VERSION ""

NS_ :

BS_:

BU_: Tester GW ECM ESP DCT EPS Ibooster HCU EDC IBooster

BO_ 87 PEPS10: 8 GW
 SG_ PEPS_VehAuth2 : 7|64@0+ (1,0) [0|1.84467440737096E+019] ""  HCU

BO_ 96 HCU_FD1: 64 HCU
 SG_ Checksum_HCU_PT1 : 71|8@0+ (1,0) [0|255] ""  GW,DCT,ESP,ECM,Ibooster
 SG_ HCU_AccelPedalPosn_Diag : 79|8@0+ (0.3937,0) [0|100.395] "%"  GW,DCT,ESP,ECM
 SG_ HCU_BrkPedalSts : 87|2@0+ (1,0) [0|3] ""  GW,DCT,ECM
 SG_ HCU_AccelPedalPosn_DiagValid : 85|1@0+ (1,0) [0|1] ""  GW,DCT,ESP,ECM
 SG_ HCU_BrkPedalStsValid : 84|1@0+ (1,0) [0|1] ""  GW,ECM
 SG_ ActWheelTrqDmd : 83|12@0+ (5,-6000) [-6000|14475] "Nm"  GW
 SG_ HCU_AccelPedalPosn : 103|8@0+ (0.3937,0) [0|100.395] "%"  GW,DCT,ESP
 SG_ HCU_AccelPedalPosnValid : 127|1@0+ (1,0) [0|1] ""  GW,DCT,ESP
 SG_ P4M_ActRotSpd : 111|16@0+ (1,-16382) [-16382|16383] "rpm"  DCT,ESP,ECM,Ibooster,EPS
 SG_ RollingCounter_HCU_PT1 : 123|4@0+ (1,0) [0|15] ""  GW,DCT,ESP,ECM,Ibooster
 SG_ Checksum_HCU_PT9 : 135|8@0+ (1,0) [0|255] ""  GW,ESP
 SG_ MaxPsblWheelTrq : 143|10@0+ (20,-6000) [-6000|14460] "Nm"  GW,ESP,ECM
 SG_ TotWheelTrq : 147|12@0+ (5,-6000) [-6000|14475] "Nm"  GW,ESP,ECM
 SG_ MinPsblWheelTrq : 167|10@0+ (20,-6000) [-6000|14460] "Nm"  GW,ESP,ECM
 SG_ HCU_ACCInterface : 170|1@0+ (1,0) [0|1] ""  GW
 SG_ RollingCounter_HCU_PT9 : 187|4@0+ (1,0) [0|15] ""  GW,ESP
 SG_ Checksum_HCU_HP1 : 199|8@0+ (1,0) [0|255] ""  DCT,ESP
 SG_ HCU_NetTrq_TrsmClutch : 207|12@0+ (0.05,-100) [-100|100] "%"  DCT,ESP
 SG_ HCU_TrqReq_TrsmClutch : 211|12@0+ (0.05,-100) [-100|100] "%"  DCT
 SG_ HCU_TrqReqWoDCT_TrsmClutch : 231|12@0+ (0.05,-100) [-100|100] "%"  DCT
 SG_ HCU_MaxTrqLimt_TrsmClutch : 235|10@0+ (0.2,-100) [-100|100] "%"  DCT
 SG_ HCU_TrsmClutchAdaptAck : 241|1@0+ (1,0) [0|1] ""  DCT
 SG_ HCU_K0ClutchAdaptAck : 240|1@0+ (1,0) [0|1] ""  DCT
 SG_ HCU_NetTrq_TrsmClutchValid : 255|1@0+ (1,0) [0|1] ""  DCT,ESP
 SG_ HCU_MaxEngTrqLimtValid : 254|1@0+ (1,0) [0|1] ""  DCT
 SG_ HCU_TrqReqWoDCT_TrsmClutchValid : 253|1@0+ (1,0) [0|1] ""  DCT
 SG_ HCU_TgtEngTrqValid : 252|1@0+ (1,0) [0|1] ""  DCT
 SG_ RollingCounter_HCU_HP1 : 251|4@0+ (1,0) [0|15] ""  DCT,ESP
 SG_ CheckSum_HCU_HP10 : 263|8@0+ (1,0) [0|255] ""  ESP,Ibooster
 SG_ RegenWheelTrqAct : 269|14@0+ (1,-16383) [-16383|0] ""  ESP
 SG_ AvailRgnTrq : 285|14@0+ (1,-16383) [-16383|0] "Nm"  ESP
 SG_ TargetGear_RA : 319|2@0+ (1,0) [0|3] ""  ESP
 SG_ RegenWheelTrqActValid : 317|1@0+ (1,0) [0|1] ""  ESP
 SG_ AvailRgnTrqValid : 316|1@0+ (1,0) [0|1] ""  ESP
 SG_ TrqReq_FAValid : 298|1@0+ (1,0) [0|1] ""  ESP
 SG_ TrqReq_FA : 297|10@0+ (1,-224) [-224|799] "Nm"  ESP
 SG_ HCU_PowertrainSts : 303|5@0+ (1,0) [0|31] ""  GW,DCT,ESP,ECM,Ibooster
 SG_ RollingCounter_HCU_HP10 : 315|4@0+ (1,0) [0|15] ""  ESP,Ibooster
 SG_ Checksum_HCU_HP11 : 327|8@0+ (1,0) [0|255] ""  DCT,ESP
 SG_ HCU_P4M_ActTrq : 335|14@0+ (0.1,-819) [-819|819.1] "Nm"  ESP
 SG_ HCU_AccPedalPosnCorrd : 351|8@0+ (0.3937,0) [0|100.395] "%" Vector__XXX
 SG_ ACU_ShiftInProgress : 375|2@0+ (1,0) [0|3] ""  GW,ESP
 SG_ ACU_ActGear : 373|3@0+ (1,0) [0|7] ""  ESP
 SG_ HCU_AccPedalPosnCorrdValid : 368|1@0+ (1,0) [0|1] "" Vector__XXX
 SG_ HCU_RaceLaunchSts : 367|3@0+ (1,0) [0|7] ""  GW,DCT,ECM
 SG_ HCU_RaceLaunchAvail : 364|2@0+ (1,0) [0|3] ""  GW
 SG_ HCU_HWPInterface : 337|1@0+ (1,0) [0|1] ""  GW
 SG_ HCU_RespHWP : 336|1@0+ (1,0) [0|1] ""  GW,ESP,Ibooster
 SG_ Rollingcounter_HCU_HP11 : 379|4@0+ (1,0) [0|15] ""  DCT,ESP
 SG_ BMS_BattChrgPower_10s : 423|10@0+ (0.2,0) [0|132] "KW"  DCT
 SG_ BMS_BattDchrgPower_10s : 429|10@0+ (0.2,0) [0|150] "KW"  DCT

BO_ 124 DCT_FD1: 64 DCT
 SG_ CheckSum_DCT1 : 71|8@0+ (1,0) [0|255] ""  ECM
 SG_ TqIdleReq : 125|1@0+ (1,0) [0|1] ""  HCU,ECM
 SG_ TqLossAct : 79|16@0+ (0.0030518,-100) [-100|99.9966612] "%"  HCU,ECM
 SG_ EngCrkEna : 127|1@0+ (1,0) [0|1] ""  GW
 SG_ TrsmAdaptActv : 124|1@0+ (1,0) [0|1] ""  HCU,ECM
 SG_ TrqRedFastReq : 95|16@0+ (0.0030518,-100) [-100|99.9966612] "%"  HCU
 SG_ EngTqMaxLim : 111|16@0+ (0.0030518,-100) [-100|99.9966612] "%"  HCU
 SG_ TCUResponseHWP : 126|1@0+ (1,0) [0|1] ""  GW
 SG_ RollingCounter_DCT1 : 123|4@0+ (1,0) [0|15] ""  ECM
 SG_ CheckSum_DCT2 : 135|8@0+ (1,0) [0|255] ""  ECM
 SG_ TC_SLIP_STATE : 191|3@0+ (1,0) [0|7] ""  HCU,ECM
 SG_ EngIdleSpdReq : 175|8@0+ (10,0) [0|2550] "RPM"  HCU,ECM
 SG_ EngTqGradientLim : 183|8@0+ (10,0) [0|2540] "Nm/s"  HCU
 SG_ TrqRedSlowReq : 159|16@0+ (0.0030518,-100) [-100|99.9966612] "%"  HCU
 SG_ RollingCounter_DCT2 : 187|4@0+ (1,0) [0|15] ""  ECM
 SG_ CheckSum_DCT3 : 199|8@0+ (1,0) [0|255] ""  ESP
 SG_ TgtEngSpdIP : 239|12@0+ (2,0) [0|8190] "RPM"  GW
 SG_ TgtEngSpdIPValid : 242|1@0+ (1,0) [0|1] ""  GW
 SG_ DCT_RaceLaunchAvail : 253|2@0+ (1,0) [0|3] ""  HCU
 SG_ DCT_RaceLaunchProhibit : 200|1@0+ (1,0) [0|1] ""  HCU
 SG_ DCT_EPBActvReqValid : 241|1@0+ (1,0) [0|1] ""  ESP
 SG_ DCT_EPBActvReq : 240|1@0+ (1,0) [0|1] ""  ESP
 SG_ TrsmTqIdle : 223|16@0+ (0.0030518,-100) [-100|99.9966612] "%"  HCU,ECM
 SG_ Start_Stop_Mode_DCT : 204|3@0+ (1,0) [0|7] ""  HCU
 SG_ StopStartFail_B_DCT : 207|1@0+ (1,0) [0|1] ""  HCU
 SG_ Start_Stop_Req_DCT : 206|2@0+ (1,0) [0|3] ""  HCU
 SG_ RatAct : 215|8@0+ (0.1,0) [0|25.5] ""  GW,HCU
 SG_ RollingCounter_DCT3 : 251|4@0+ (1,0) [0|15] ""  ESP
 SG_ CheckSumDCT11 : 327|8@0+ (1,0) [0|255] "" Vector__XXX
 SG_ DCT_K1ClutchOilPressure : 335|16@0+ (0.473,0) [0|31000] "mBar"  HCU
 SG_ DCT_K0ClutchPredictTorque : 351|12@0+ (0.05,-100) [-100|100] "%"  HCU
 SG_ DCT_K1ClutchPredictTorque : 355|12@0+ (0.05,-100) [-100|100] "%"  HCU
 SG_ DCT_K2ClutchPredictTorque : 375|12@0+ (0.05,-100) [-100|100] "%"  HCU
 SG_ RollingCounterDCT11 : 379|4@0+ (1,0) [0|15] "" Vector__XXX
 SG_ FreshnessValue_DCT_FD1 : 455|16@0+ (1,0) [0|65535] ""  GW
 SG_ MAC_Check_DCT_FD1 : 471|48@0+ (1,0) [0|281474976710655] ""  GW
 SG_ CheckSumDCT19 : 391|8@0+ (1,0) [0|255] ""  HCU
 SG_ TCU_TgtTrsmRatio : 423|8@0+ (0.1,0) [0|25.5] ""  HCU
 SG_ DCT_TrqRatio : 431|16@0+ (0.001,0) [0|65.533] ""  HCU
 SG_ RollingCounterDCT19 : 443|4@0+ (1,0) [0|15] ""  HCU

BO_ 135 PEPS3: 8 GW
 SG_ PEPS_VehAuth1 : 7|64@0+ (1,0) [0|1.84467440737095E+019] ""  HCU

BO_ 143 ECM_FD5: 64 ECM
 SG_ Checksum_ECM1 : 7|8@0+ (1,0) [0|255] ""  GW,HCU,DCT,ESP,Ibooster
 SG_ EngSpd_PHEV : 47|16@0+ (0.125,0) [0|8191.875] "rpm"  GW,HCU,DCT,ESP,Ibooster,EDC,EPS
 SG_ EngSpdVldty_PHEV : 63|2@0+ (1,0) [0|2] ""  GW,HCU,DCT,ESP,Ibooster,EDC,EPS
 SG_ RollingCounter_ECM1 : 59|4@0+ (1,0) [0|15] ""  GW,HCU,DCT,ESP,Ibooster
 SG_ Checksum_ECM_HP2 : 71|8@0+ (1,0) [0|255] ""  HCU,ESP
 SG_ TrqMaxSlowPath : 79|10@0+ (1,-224) [-224|799] "Nm"  HCU
 SG_ TrqMinSlowPath : 85|10@0+ (1,-224) [-224|799] "Nm"  HCU
 SG_ TrqMaxFastPath : 91|10@0+ (1,-224) [-224|799] "Nm"  HCU,ESP
 SG_ TrqMinFastPath : 97|10@0+ (1,-224) [-224|799] "Nm"  HCU
 SG_ TgtCrsAcc : 119|8@0+ (0.015,-1.5) [-1.5|2.325] "m/s2"  HCU
 SG_ TrqRngValid : 127|1@0+ (1,0) [0|1] ""  HCU
 SG_ TgtCrsAccValid : 126|1@0+ (1,0) [0|1] ""  HCU
 SG_ RollingCounter_ECM_HP2 : 123|4@0+ (1,0) [0|15] ""  HCU,ESP
 SG_ Checksum_ECM_HP4 : 135|8@0+ (1,0) [0|255] ""  HCU
 SG_ IdleTrq_PI : 143|10@0+ (0.5,-256) [-256|255.5] "NM"  HCU
 SG_ IdleTrq_PIValid : 149|1@0+ (1,0) [0|1] ""  HCU
 SG_ MaxAlwdTrqIntvntn : 148|10@0+ (1,-224) [-224|799] "Nm"  HCU
 SG_ IdleTrq_ECUInternal : 154|11@0+ (0.25,0) [0|511.75] "Nm"  HCU
 SG_ MinAlwdTrqIntvntn : 175|10@0+ (1,-224) [-224|799] "Nm"  HCU
 SG_ SpdGovFactor : 181|8@0+ (0.00393,0) [0|1] ""  HCU
 SG_ RngAlwdTrqIntvntnValid : 189|1@0+ (1,0) [0|1] ""  HCU
 SG_ CANSendSts_Wakeup : 188|1@0+ (1,0) [0|1] ""  HCU
 SG_ RollingCounter_ECM_HP4 : 187|4@0+ (1,0) [0|15] ""  HCU
 SG_ Checksum_ECM_HP3 : 199|8@0+ (1,0) [0|255] ""  HCU
 SG_ EngStatnryTrqSlowPathMax : 207|10@0+ (1,-224) [-224|799] "Nm"  HCU
 SG_ EngStatnryTrqSlowPathMin : 213|10@0+ (1,-224) [-224|799] "Nm"  HCU
 SG_ EngStatnryTrqFastPathMax : 219|10@0+ (1,-224) [-224|799] "Nm"  HCU
 SG_ EngStatnryTrqFastPathMin : 225|10@0+ (1,-224) [-224|799] "Nm"  HCU
 SG_ EngStatnryTrqRngValid : 255|1@0+ (1,0) [0|1] ""  HCU
 SG_ RollingCounter_ECM_HP3 : 251|4@0+ (1,0) [0|15] ""  HCU
 SG_ Checksum_ECM_PT5 : 263|8@0+ (1,0) [0|255] ""  HCU,DCT,ESP
 SG_ EngTrqLimProtFastPath : 271|10@0+ (1,-224) [-224|799] "Nm"  HCU
 SG_ EngTrqLimProtSlowPath : 277|10@0+ (1,-224) [-224|799] "Nm"  HCU
 SG_ EngTrqCrankshaftLvl : 283|12@0+ (0.25,-224) [-224|799.75] "Nm"  GW,HCU,DCT,ESP
 SG_ EngTrqCrankshaftLvlValid : 317|1@0+ (1,0) [0|1] ""  GW,HCU,DCT
 SG_ EngTrqLimProtValid : 316|1@0+ (1,0) [0|1] ""  HCU
 SG_ RollingCounter_ECM_PT5 : 315|4@0+ (1,0) [0|15] ""  HCU,DCT,ESP
 SG_ Checksum_ECM_HP1 : 327|8@0+ (1,0) [0|255] ""  HCU
 SG_ TrqMinFastPathFCO : 351|10@0+ (1,-224) [-224|799] "Nm"  HCU
 SG_ EngTrqLoss : 357|12@0+ (0.25,-224) [-224|799.75] "Nm"  HCU
 SG_ EngErrCategory0 : 361|1@0+ (1,0) [0|1] ""  HCU
 SG_ EngErrCategory1 : 360|1@0+ (1,0) [0|1] ""  HCU
 SG_ EngErrCategory2 : 375|1@0+ (1,0) [0|1] ""  HCU
 SG_ EngErrCategory3 : 374|1@0+ (1,0) [0|1] ""  HCU
 SG_ EngErrCategory4 : 373|1@0+ (1,0) [0|1] ""  HCU
 SG_ EngStopEnable : 372|1@0+ (1,0) [0|1] ""  HCU
 SG_ EngStartReq : 371|1@0+ (1,0) [0|1] ""  HCU
 SG_ ECM_TrqStructActv : 370|1@0+ (1,0) [0|1] ""  HCU
 SG_ FCOActv : 369|1@0+ (1,0) [0|1] ""  HCU,DCT
 SG_ FCOEnable : 368|1@0+ (1,0) [0|1] ""  HCU
 SG_ EngTrqLossValid : 383|1@0+ (1,0) [0|1] ""  HCU
 SG_ TrqMinFastPathFCOValid : 382|1@0+ (1,0) [0|1] ""  HCU
 SG_ RollingCounter_ECM_HP1 : 379|4@0+ (1,0) [0|15] ""  HCU

BO_ 150 IBooster_FD3: 32 IBooster
 SG_ CheckSum_IBooster_FD3_1 : 7|8@0+ (1,0) [0|255] ""  ESP
 SG_ DrvReqTarFxBrakeAvl : 15|2@0+ (1,0) [0|2] ""  ESP
 SG_ DrvReqTarFxBrake : 13|14@0+ (8,-125000) [-125000|0] ""  ESP
 SG_ DrvPressBrkPedalAvl : 31|2@0+ (1,0) [0|2] ""  ESP
 SG_ IsDrvPressBrkPedal : 29|1@0+ (1,0) [0|1] ""  ESP
 SG_ DrvReqFxBrkDomAvail : 28|2@0+ (1,0) [0|2] ""  ESP
 SG_ IsDrvReqFxBrakeDom : 26|1@0+ (1,0) [0|1] ""  ESP
 SG_ DrvReqParkBrakeAvail : 25|2@0+ (1,0) [0|2] ""  ESP
 SG_ DriverReqParkBrake : 39|2@0+ (1,0) [0|2] ""  ESP
 SG_ IsDrvReqParkBrkDom : 37|1@0+ (1,0) [0|1] ""  ESP
 SG_ BrkDiscTempStatus : 36|2@0+ (1,0) [0|3] ""  ESP
 SG_ BrkDiscTempStatusAvl : 47|2@0+ (1,0) [0|2] ""  ESP
 SG_ BrakeBckpStratState : 45|2@0+ (1,0) [0|2] ""  ESP
 SG_ BrkBckStratFxCtrlAvl : 34|3@0+ (1,0) [0|4] ""  ESP
 SG_ BrkBckStgyVehStopAvl : 43|3@0+ (1,0) [0|4] ""  ESP
 SG_ CurrentPumpRev : 40|9@0+ (20,0) [0|10000] ""  ESP
 SG_ RollingCounter_IBooster_FD3_1 : 59|4@0+ (1,0) [0|15] ""  ESP
 SG_ CheckSum_IBooster_FD3_2 : 71|8@0+ (1,0) [0|255] ""  ESP
 SG_ CompatibilityIndexAD : 79|4@0+ (1,0) [0|15] ""  ESP
 SG_ FxDrvBrake : 87|16@0+ (10,-250000) [-250000|250000] ""  ESP
 SG_ ParkBrakeRequest : 103|3@0+ (1,0) [0|4] ""  ESP
 SG_ DriveBckp2MnState : 75|4@0+ (1,0) [0|11] ""  ESP
 SG_ StopBckp2MnState : 100|4@0+ (1,0) [0|11] ""  ESP
 SG_ LsmBckpLvl23Avail : 111|2@0+ (1,0) [0|3] ""  ESP
 SG_ LsmBckpLvl23Cpbl : 109|2@0+ (1,0) [0|2] ""  ESP
 SG_ DrvBckpLvl3Avail : 107|2@0+ (1,0) [0|3] ""  ESP
 SG_ DrvBckpLvl3Cpbl : 105|2@0+ (1,0) [0|2] ""  ESP
 SG_ RollingCounter_IBooster_FD3_2 : 123|4@0+ (1,0) [0|15] ""  ESP
 SG_ CheckSum_IBooster_FD3_3 : 135|8@0+ (1,0) [0|255] ""  ESP
 SG_ UsedChannel : 143|2@0+ (1,0) [0|3] ""  ESP
 SG_ BrakeFxCapability : 141|2@0+ (1,0) [0|2] ""  ESP
 SG_ BrakeFxAvailability : 139|2@0+ (1,0) [0|2] ""  ESP
 SG_ BrakeFxActual : 151|14@0+ (8,-125000) [-125000|0] ""  ESP
 SG_ IsBrkFctReqFxBrkDom : 153|1@0+ (1,0) [0|1] ""  ESP
 SG_ DecStabAvail : 137|2@0+ (1,0) [0|2] ""  ESP
 SG_ DecStabCpblty : 167|2@0+ (1,0) [0|3] ""  ESP
 SG_ DecStabAvlForDriver : 165|2@0+ (1,0) [0|2] ""  ESP
 SG_ DecStabCpbltyForDrvr : 163|2@0+ (1,0) [0|3] ""  ESP
 SG_ DecStabActivity : 161|2@0+ (1,0) [0|2] ""  ESP
 SG_ AccStabAvail : 175|2@0+ (1,0) [0|2] ""  ESP
 SG_ AccStabActivity : 152|1@0+ (1,0) [0|1] ""  ESP
 SG_ YawRateStabAvl : 173|2@0+ (1,0) [0|2] ""  ESP
 SG_ YawRateStabActivity : 171|1@0+ (1,0) [0|1] ""  ESP
 SG_ ParkBrakeCapability : 183|2@0+ (1,0) [0|2] ""  ESP
 SG_ ParkBrakeAvl : 181|2@0+ (1,0) [0|2] ""  ESP
 SG_ ParkBrakeState : 170|3@0+ (1,0) [0|4] ""  ESP
 SG_ ParkBrakeSupportReq : 179|1@0+ (1,0) [0|1] ""  ESP
 SG_ IsBrkFctReqPrkBrkDom : 178|1@0+ (1,0) [0|1] ""  ESP
 SG_ RollingCounter_IBooster_FD3_3 : 187|4@0+ (1,0) [0|15] ""  ESP

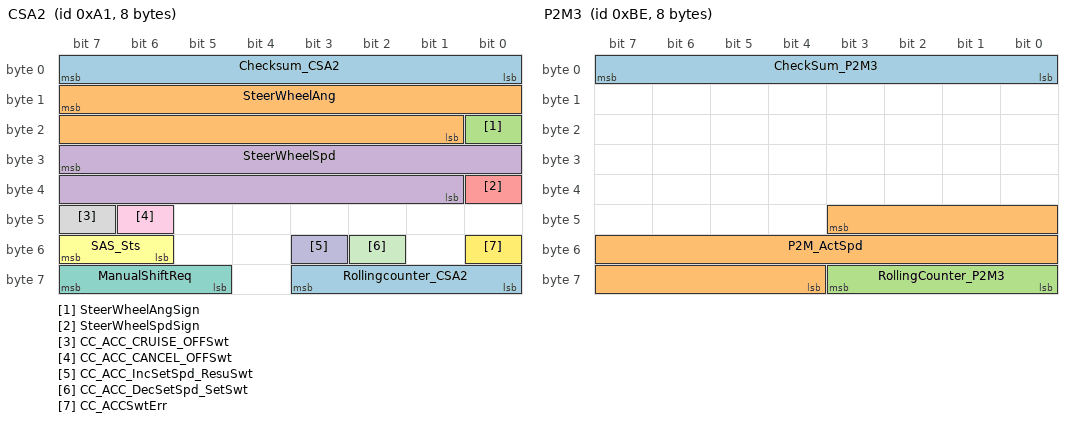
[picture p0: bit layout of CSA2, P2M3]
BO_ 161 CSA2: 8 GW
 SG_ Checksum_CSA2 : 7|8@0+ (1,0) [0|255] ""  ESP,ECM,Ibooster,EPS
 SG_ SteerWheelAng : 15|15@0+ (0.1,0) [0|780] "deg"  HCU,DCT,ESP,Ibooster,EDC,EPS
 SG_ SteerWheelAngSign : 16|1@0+ (1,0) [0|1] ""  HCU,ESP,Ibooster,EDC,EPS
 SG_ SteerWheelSpd : 31|15@0+ (0.1,0) [0|1016] "deg/s"  HCU,ESP,ECM,Ibooster,EDC
 SG_ SteerWheelSpdSign : 32|1@0+ (1,0) [0|1] ""  HCU,ESP,ECM,Ibooster,EDC
 SG_ SAS_Sts : 55|2@0+ (1,0) [0|3] ""  HCU,ESP,Ibooster,EPS
 SG_ ManualShiftReq : 63|3@0+ (1,0) [0|7] ""  DCT
 SG_ CC_ACC_CRUISE_OFFSwt : 47|1@0+ (1,0) [0|1] ""  ECM
 SG_ CC_ACC_CANCEL_OFFSwt : 46|1@0+ (1,0) [0|1] ""  ECM
 SG_ CC_ACC_IncSetSpd_ResuSwt : 51|1@0+ (1,0) [0|1] ""  ECM
 SG_ CC_ACC_DecSetSpd_SetSwt : 50|1@0+ (1,0) [0|1] ""  ECM
 SG_ CC_ACCSwtErr : 48|1@0+ (1,0) [0|1] ""  ECM
 SG_ Rollingcounter_CSA2 : 59|4@0+ (1,0) [0|15] ""  ESP,ECM,Ibooster,EPS

BO_ 165 PEPS1: 8 GW
 SG_ VehStartReq : 17|2@0+ (1,0) [0|3] ""  HCU

BO_ 168 DCT_FD2: 64 DCT
 SG_ CheckSumDCT12 : 71|8@0+ (1,0) [0|255] "" Vector__XXX
 SG_ DCT_K2ClutchOilPressure : 79|16@0+ (0.473,0) [0|31000] "mBar"  HCU
 SG_ DCT_K0ClutchActTrq : 95|12@0+ (0.05,-100) [-100|100] ""  HCU
 SG_ DCT_K1ClutchActTrq : 99|12@0+ (0.05,-100) [-100|100] "%"  HCU
 SG_ DCT_K2ClutchActTrq : 119|12@0+ (0.05,-100) [-100|100] "%"  HCU
 SG_ RollingCounterDCT12 : 123|4@0+ (1,0) [0|15] "" Vector__XXX
 SG_ CheckSumDCT13 : 135|8@0+ (1,0) [0|255] "" Vector__XXX
 SG_ DCT_K0ClutchTemp : 143|8@0+ (1,-40) [-40|214] "℃"  HCU
 SG_ DCT_K1ClutchTemp : 151|8@0+ (1,-40) [-40|214] "℃"  HCU
 SG_ DCT_K2ClutchTemp : 159|8@0+ (1,-40) [-40|214] "℃"  HCU
 SG_ DCT_K0ClutchMaxSpeedDif : 167|13@0+ (1,0) [0|8000] "rpm"  HCU
 SG_ DCT_TrsmClutchMaxSpeedDif : 170|13@0+ (1,0) [0|8000] "rpm"  HCU
 SG_ RollingCounterDCT13 : 187|4@0+ (1,0) [0|15] "" Vector__XXX
 SG_ CheckSumDCT14 : 199|8@0+ (1,0) [0|255] "" Vector__XXX
 SG_ DCT_K0ClutchOilPressure : 207|16@0+ (0.473,0) [0|31000] "mBar"  HCU
 SG_ DCT_MinTrqLim_TrsmClutch : 223|12@0+ (0.05,-100) [-100|100] "%"  HCU
 SG_ DCT_K0ClutchMinTrqLim : 227|12@0+ (0.05,-100) [-100|100] "%"  HCU
 SG_ DCT_K0ClutchMaxTrqLim : 247|12@0+ (0.05,-100) [-100|100] "%"  HCU
 SG_ RollingCounterDCT14 : 251|4@0+ (1,0) [0|15] "" Vector__XXX
 SG_ CheckSumDCT15 : 263|8@0+ (1,0) [0|255] "" Vector__XXX
 SG_ DCT_TrqOutpLimFlg : 305|2@0+ (1,0) [0|3] ""  HCU
 SG_ DCT_EngTrqLimC0 : 271|12@0+ (0.0488281,-100) [-100|99.9022414] "%"  HCU
 SG_ DCT_K0ClutchAdaptActv : 272|1@0+ (1,0) [0|1] ""  HCU
 SG_ DCT_K0ClutchActStatus : 275|3@0+ (1,0) [0|7] ""  HCU,ECM
 SG_ DCT_P2MotorSpdReq : 287|16@0+ (0.122074,0) [0|8000] "rpm"  HCU
 SG_ DCT_ISS : 303|14@0+ (1,0) [0|10000] "RPM"  HCU
 SG_ RollingCounterDCT15 : 315|4@0+ (1,0) [0|15] "" Vector__XXX
 SG_ CheckSumDCT16 : 327|8@0+ (1,0) [0|255] "" Vector__XXX
 SG_ DCT_TrqOutput : 335|12@0+ (1,-2000) [-2000|2095] "%"  HCU
 SG_ TrqIncSlowReq_Ktr : 339|12@0+ (0.0488281,-100) [-100|99.9022414] "%"  HCU
 SG_ TrqIncFastReq_Ktr : 359|12@0+ (0.0488281,-100) [-100|99.9022414] "%"  HCU
 SG_ TCU_TgtIdleLoadTrq : 363|12@0+ (0.0488281,-100) [-100|99.9022414] "%"  HCU
 SG_ DCT_K0EmgyReq : 383|2@0+ (1,0) [0|3] ""  HCU
 SG_ DCT_RvsGearSts : 381|2@0+ (1,0) [0|3] ""  HCU
 SG_ RollingCounterDCT16 : 379|4@0+ (1,0) [0|15] "" Vector__XXX

BO_ 189 ESP_FD1: 64 ESP
 SG_ CheckSum_ESP11 : 7|8@0+ (1,0) [0|255] ""  Ibooster
 SG_ ESP_VehSpd : 15|8@0+ (0.390625,0) [0|99.6] "m/s"  Ibooster
 SG_ ESP_PressEstimdMax : 23|8@0+ (1,0) [0|250] "bar"  Ibooster
 SG_ ESP_QntyTgtExt : 31|16@0+ (0.0078125,-252) [-252|252] "ml/s"  Ibooster
 SG_ ESP_VehSpdValid : 47|2@0+ (1,0) [0|2] ""  Ibooster
 SG_ ESP_QntyTgtExtVld : 43|2@0+ (1,0) [0|3] ""  Ibooster
 SG_ ESP_HMI_WarningOn : 41|2@0+ (1,0) [0|3] ""  GW,Ibooster
 SG_ ESP_IGNOn : 55|1@0+ (1,0) [0|1] ""  Ibooster
 SG_ ESP_ABSActv : 54|1@0+ (1,0) [0|1] ""  Ibooster
 SG_ RollingCounter_ESP11 : 59|4@0+ (1,0) [0|15] ""  Ibooster
 SG_ CheckSum_ESP12 : 71|8@0+ (1,0) [0|255] ""  Ibooster
 SG_ ESP_PMC1 : 79|10@0+ (0.3,-30) [-30|276.6] "bar"  Ibooster
 SG_ ESP_PMC1Vld : 85|2@0+ (1,0) [0|2] ""  Ibooster
 SG_ ESP_ForceBldActv : 83|2@0+ (1,0) [0|2] ""  Ibooster
 SG_ ESP_PMCVirt : 95|10@0+ (0.25,0) [0|250] "bar"  Ibooster
 SG_ ESP_PMCVirtVld : 101|2@0+ (1,0) [0|2] ""  Ibooster
 SG_ ESP_PressForceBldMC : 111|10@0+ (0.25,0) [0|250] "bar"  Ibooster
 SG_ ESP_PressForceBldMCVld : 117|2@0+ (1,0) [0|2] ""  Ibooster
 SG_ RollingCounter_ESP12 : 123|4@0+ (1,0) [0|15] ""  Ibooster
 SG_ Checksum_ESP10 : 199|8@0+ (1,0) [0|255] "" Vector__XXX
 SG_ TgtRcprtnTrqReq : 221|14@0+ (1,-16383) [-16383|0] "Nm"  HCU
 SG_ TgtRcprtnTrqSts : 239|2@0+ (1,0) [0|3] ""  GW,HCU
 SG_ RollingCounter_ESP10 : 251|4@0+ (1,0) [0|15] "" Vector__XXX
 SG_ CheckSum_ESP_FD1_3 : 135|8@0+ (1,0) [0|255] ""  Ibooster
 SG_ DriveMn2BckpState : 143|4@0+ (1,0) [0|11] ""  Ibooster
 SG_ StopMn2BckpState : 139|4@0+ (1,0) [0|11] ""  Ibooster
 SG_ LsmMainLvl23Avail : 151|2@0+ (1,0) [0|3] ""  Ibooster
 SG_ LsmMainLvl23Cpbl : 149|2@0+ (1,0) [0|2] ""  Ibooster
 SG_ DrvMainLvl3Avail : 147|2@0+ (1,0) [0|3] ""  Ibooster
 SG_ DrvMainLvl3Cpbl : 145|2@0+ (1,0) [0|2] ""  Ibooster
 SG_ LsmMotionSrvReq : 159|3@0+ (1,0) [0|4] ""  Ibooster
 SG_ RollingCounter_ESP_FD1_3 : 187|4@0+ (1,0) [0|15] ""  Ibooster
 SG_ CheckSum_ESP_FD1_5 : 263|8@0+ (1,0) [0|255] ""  Ibooster
 SG_ UsedChannel : 271|2@0+ (1,0) [0|3] ""  Ibooster
 SG_ BrakeFxCapability : 269|2@0+ (1,0) [0|2] ""  Ibooster
 SG_ BrakeFxAvailability : 267|2@0+ (1,0) [0|2] ""  Ibooster
 SG_ IsBrkFctReqFxBrkDom : 265|1@0+ (1,0) [0|1] ""  Ibooster
 SG_ DecStabAvail : 281|2@0+ (1,0) [0|2] ""  Ibooster
 SG_ DecStabCpblty : 295|2@0+ (1,0) [0|3] ""  Ibooster
 SG_ DecStabAvlForDriver : 293|2@0+ (1,0) [0|2] ""  Ibooster
 SG_ DecStabCpbltyForDrvr : 291|2@0+ (1,0) [0|3] ""  Ibooster
 SG_ DecStabActivity : 289|2@0+ (1,0) [0|2] ""  Ibooster
 SG_ AccStabAvail : 303|2@0+ (1,0) [0|2] ""  Ibooster
 SG_ AccStabActivity : 264|1@0+ (1,0) [0|1] ""  Ibooster
 SG_ YawRateStabAvl : 301|2@0+ (1,0) [0|2] ""  Ibooster
 SG_ YawRateStabActivity : 299|1@0+ (1,0) [0|1] ""  Ibooster
 SG_ ParkBrakeCapability : 311|2@0+ (1,0) [0|2] ""  Ibooster
 SG_ ParkBrakeAvl : 309|2@0+ (1,0) [0|2] ""  Ibooster
 SG_ ParkBrakeState : 298|3@0+ (1,0) [0|4] ""  Ibooster
 SG_ ParkBrakeSupportReq : 307|1@0+ (1,0) [0|1] ""  Ibooster
 SG_ IsBrkFctReqPrkBrkDom : 306|1@0+ (1,0) [0|1] ""  Ibooster
 SG_ BrakeFxActual : 279|14@0+ (8,-125000) [-125000|0] ""  Ibooster
 SG_ RollingCounter_ESP_FD1_5 : 315|4@0+ (1,0) [0|15] ""  Ibooster
 SG_ CheckSum_ESP_FD1_6 : 327|8@0+ (1,0) [0|255] ""  Ibooster
 SG_ DrvReqTarFxBrakeAvl : 335|2@0+ (1,0) [0|2] ""  Ibooster
 SG_ DrvPressBrkPedalAvl : 351|2@0+ (1,0) [0|2] ""  Ibooster
 SG_ IsDrvPressBrkPedal : 349|1@0+ (1,0) [0|1] ""  Ibooster
 SG_ DrvReqFxBrkDomAvail : 348|2@0+ (1,0) [0|2] ""  Ibooster
 SG_ IsDrvReqFxBrakeDom : 346|1@0+ (1,0) [0|1] ""  Ibooster
 SG_ DrvReqParkBrakeAvail : 345|2@0+ (1,0) [0|2] ""  Ibooster
 SG_ DriverReqParkBrake : 359|2@0+ (1,0) [0|2] ""  Ibooster
 SG_ IsDrvReqParkBrkDom : 357|1@0+ (1,0) [0|1] ""  Ibooster
 SG_ BrkDiscTempStatus : 356|2@0+ (1,0) [0|3] ""  Ibooster
 SG_ BrkDiscTempStatusAvl : 354|2@0+ (1,0) [0|2] ""  Ibooster
 SG_ BrakeBckpStratState : 375|2@0+ (1,0) [0|2] ""  Ibooster
 SG_ BrkBckStratFxCtrlAvl : 373|3@0+ (1,0) [0|4] ""  Ibooster
 SG_ BrkBckStgyVehStopAvl : 370|3@0+ (1,0) [0|4] ""  Ibooster
 SG_ DrvReqTarFxBrake : 333|14@0+ (8,-125000) [-125000|0] ""  Ibooster
 SG_ CurrentPumpRev : 352|9@0+ (20,0) [0|10000] ""  Ibooster
 SG_ RollingCounter_ESP_FD1_6 : 379|4@0+ (1,0) [0|15] ""  Ibooster

BO_ 190 P2M3: 8 GW
 SG_ CheckSum_P2M3 : 7|8@0+ (1,0) [0|255] ""  ESP,Ibooster
 SG_ P2M_ActSpd : 43|16@0+ (1,-2000) [-2000|10286] "rpm"  DCT,ESP,ECM,Ibooster,EDC,EPS
 SG_ RollingCounter_P2M3 : 59|4@0+ (1,0) [0|15] ""  ESP,Ibooster

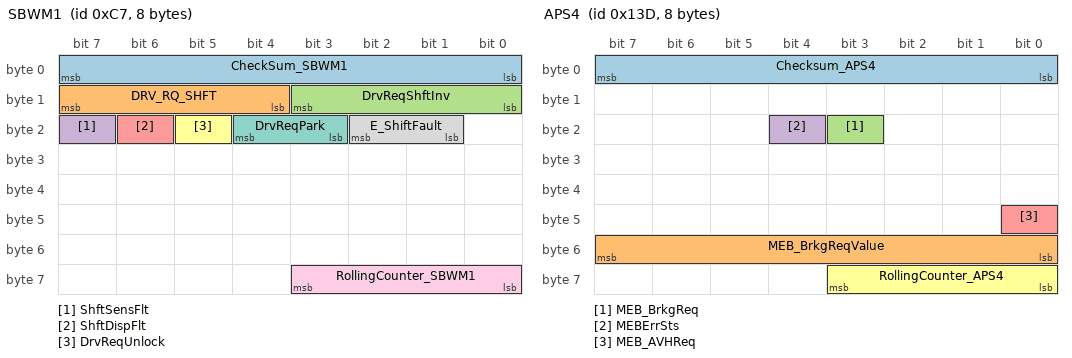
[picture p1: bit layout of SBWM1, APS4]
BO_ 199 SBWM1: 8 GW
 SG_ CheckSum_SBWM1 : 7|8@0+ (1,0) [0|255] ""  DCT
 SG_ DRV_RQ_SHFT : 15|4@0+ (1,0) [0|15] ""  DCT
 SG_ DrvReqShftInv : 11|4@0+ (1,0) [0|15] ""  DCT
 SG_ ShftSensFlt : 23|1@0+ (1,0) [0|1] ""  DCT
 SG_ ShftDispFlt : 22|1@0+ (1,0) [0|1] ""  DCT
 SG_ DrvReqUnlock : 21|1@0+ (1,0) [0|1] ""  DCT
 SG_ DrvReqPark : 20|2@0+ (1,0) [0|3] ""  DCT
 SG_ E_ShiftFault : 18|2@0+ (1,0) [0|3] ""  DCT
 SG_ RollingCounter_SBWM1 : 59|4@0+ (1,0) [0|15] ""  DCT

BO_ 209 Ibooster_FD1: 16 Ibooster
 SG_ Checksum_Ibooster1 : 7|8@0+ (1,0) [0|255] ""  HCU,ESP
 SG_ IB_DrvOutpRodVal : 15|12@0+ (0.015625,-5) [-5|47] "mm"  HCU,ESP
 SG_ IB_CurrOutpRodVal : 19|12@0+ (0.015625,-5) [-5|47] "mm"  HCU,ESP
 SG_ IB_DrvOutpRodValVld : 39|2@0+ (1,0) [0|3] ""  HCU,ESP
 SG_ IB_CurrOutpRodValVld : 37|2@0+ (1,0) [0|3] ""  HCU,ESP
 SG_ IB_ExtReqPrio : 35|1@0+ (1,0) [0|1] ""  ESP
 SG_ IB_ExtReqSts : 34|2@0+ (1,0) [0|3] ""  ESP
 SG_ RollingCounter_Ibooster1 : 59|4@0+ (1,0) [0|15] ""  HCU,ESP

BO_ 234 HCU_FD2: 64 HCU
 SG_ Checksum_HCU_HP2 : 71|8@0+ (1,0) [0|255] ""  DCT
 SG_ HCU_TrsmStsReq : 84|1@0+ (1,0) [0|1] ""  DCT
 SG_ HCU_FastRedTrqLim_TrsmClutch : 83|12@0+ (0.05,-100) [-100|100] "%"  DCT
 SG_ HCU_MinTrqLim_TrsmClutch : 103|12@0+ (0.05,-100) [-100|100] "%"  DCT
 SG_ TrqAct_RA : 107|12@0+ (0.5,-1024) [-1024|1023.5] "%"  DCT,ECM
 SG_ FastRedTrqLimValid : 127|1@0+ (1,0) [0|1] ""  DCT
 SG_ TrqAct_RAValid : 126|1@0+ (1,0) [0|1] ""  DCT,ECM
 SG_ HCU_MinEngTrqLimValid : 125|1@0+ (1,0) [0|1] ""  DCT
 SG_ RollingCounter_HCU_HP2 : 123|4@0+ (1,0) [0|15] ""  DCT
 SG_ Checksum_HCU_HP3 : 135|8@0+ (1,0) [0|255] ""  DCT,ESP,ECM
 SG_ HCU_P2MActTrq : 143|12@0+ (0.5,-819) [-819|819] "Nm"  DCT,ECM
 SG_ HCU_TrqInterventionStateESP : 147|2@0+ (1,0) [0|3] ""  ECM
 SG_ HCU_TrsmClutchStatusReq : 161|2@0+ (1,0) [0|3] ""  DCT
 SG_ AntiSurgeDamperInhb : 175|1@0+ (1,0) [0|1] ""  ECM
 SG_ HCU_PTRdy : 174|1@0+ (1,0) [0|1] ""  ECM
 SG_ HCU_EngIdleReq : 173|1@0+ (1,0) [0|1] ""  ECM
 SG_ FastTrqIntvntn : 172|1@0+ (1,0) [0|1] ""  ECM
 SG_ NoRampsReq : 171|1@0+ (1,0) [0|1] ""  ECM
 SG_ RelsIGNReq : 169|1@0+ (1,0) [0|1] ""  ECM
 SG_ FullTrqReq : 168|1@0+ (1,0) [0|1] ""  ECM
 SG_ HCU_EngStartReq : 183|1@0+ (1,0) [0|1] ""  DCT,ECM
 SG_ HCU_EngStopReq : 182|1@0+ (1,0) [0|1] ""  DCT,ECM
 SG_ FuelCutOffReq : 181|1@0+ (1,0) [0|1] ""  ECM
 SG_ CrsCtrlOvldAccelPedal : 178|1@0+ (1,0) [0|1] ""  ECM
 SG_ TrqReqSlowPathEnable : 177|1@0+ (1,0) [0|1] ""  ECM
 SG_ TrqReqFastPathEnable : 176|1@0+ (1,0) [0|1] ""  ECM
 SG_ HCU_EngStartPre : 191|1@0+ (1,0) [0|1] ""  DCT,ECM
 SG_ HCU_StartStopTypReq : 190|3@0+ (1,0) [0|7] ""  DCT,ECM
 SG_ TrqReq_RAValid : 144|1@0+ (1,0) [0|1] ""  ESP
 SG_ TrqReq_RA : 159|14@0+ (1,-224) [-224|799] "Nm"  ESP
 SG_ RollingCounter_HCU_HP3 : 187|4@0+ (1,0) [0|15] ""  DCT,ESP,ECM
 SG_ Checksum_HCU_HP4 : 199|8@0+ (1,0) [0|255] ""  ESP,ECM
 SG_ TrqLowLimit : 207|10@0+ (1,-224) [-224|799] "Nm"  ECM
 SG_ IdleTrqReserveReq : 219|10@0+ (1,-224) [-224|799] "Nm"  ECM
 SG_ P2M_InvActSts : 243|4@0+ (1,0) [0|15] ""  DCT,ESP
 SG_ P4M_OperMod : 255|4@0+ (1,0) [0|15] ""  ESP
 SG_ RollingCounter_HCU_HP4 : 251|4@0+ (1,0) [0|15] ""  ESP,ECM
 SG_ CheckSum_HCU_HP8 : 263|8@0+ (1,0) [0|255] ""  DCT,ESP,ECM
 SG_ IdleLoadTrq : 271|12@0+ (0.25,-224) [-224|799.5] "Nm"  ECM
 SG_ HCU_TrqLimMax_Norm : 272|9@0+ (2,0) [0|550] "Nm"  GW,DCT,ESP
 SG_ TrqReqSlowPath : 295|12@0+ (0.25,-224) [-224|799.5] "Nm"  ECM
 SG_ TrqReqFastPath : 299|12@0+ (0.25,-224) [-224|799.5] "Nm"  ECM
 SG_ RollingCounter_HCU_HP8 : 315|4@0+ (1,0) [0|15] ""  DCT,ESP,ECM
 SG_ Checksum_HCU_HP9 : 327|8@0+ (1,0) [0|255] ""  DCT,ESP
 SG_ HCU_K0ClutchStatusReq : 337|2@0+ (1,0) [0|3] ""  DCT
 SG_ HCU_TrsmClutchTargetSpeedDif : 335|10@0+ (1,0) [0|1000] ""  DCT
 SG_ HCU_K0ClutchTrqReq : 351|12@0+ (0.05,-100) [-100|100] ""  DCT
 SG_ TorqueLossValid : 341|1@0+ (1,0) [0|1] ""  DCT,ESP
 SG_ HCU_KickDownActv : 340|1@0+ (1,0) [0|1] ""  DCT
 SG_ HCU_EVTgtGearSts : 339|2@0+ (1,0) [0|3] ""  DCT
 SG_ HCU_DCTCreepInhbn : 362|1@0+ (1,0) [0|1] ""  DCT
 SG_ TorqueLoss : 375|12@0+ (0.0488281,-100) [-100|99.9510695] "%"  DCT,ESP
 SG_ RollingCounter_HCU_HP9 : 379|4@0+ (1,0) [0|15] ""  DCT,ESP
 SG_ HCU_ChrgDeplt : 423|1@0+ (1,0) [0|1] ""  ECM

BO_ 259 ECM_FD2: 64 ECM
 SG_ Checksum_ECM9 : 71|8@0+ (1,0) [0|255] "" Vector__XXX
 SG_ EngTgtIdleSpd : 87|8@0+ (10,0) [0|2550] "rpm"  HCU,DCT
 SG_ EngCatWarmUp : 111|8@0+ (1,0) [0|100] "%"  HCU
 SG_ RollingCounter_ECM9 : 123|4@0+ (1,0) [0|15] "" Vector__XXX
 SG_ CheckSum_ECM2 : 199|8@0+ (1,0) [0|255] ""  HCU,ESP,EPS
 SG_ FuelConsumption : 207|16@0+ (2,0) [0|131070] "μl"  GW,HCU
 SG_ EngSVSSig : 240|1@0+ (1,0) [0|1] ""  GW,HCU
 SG_ ThrtlPosRatio : 231|8@0+ (0.3937,0) [0|99.9998] "%"  GW,HCU,DCT,ESP
 SG_ TgtCrsVehSpd : 239|8@0+ (1,0) [0|255] "kph/mph"  GW,HCU,DCT
 SG_ TgtCrsVehSpdvalid : 245|1@0+ (1,0) [0|1] ""  HCU
 SG_ MILSts : 255|1@0+ (1,0) [0|1] ""  GW,HCU
 SG_ RollingCounter_ECM2 : 251|4@0+ (1,0) [0|15] ""  HCU,ESP,EPS
 SG_ Checksum_ECM_HP6 : 263|8@0+ (1,0) [0|255] ""  HCU
 SG_ EngCrankshaftPosn : 284|7@0+ (1,0) [0|119] ""  HCU
 SG_ Engoverspd : 293|2@0+ (1,0) [0|3] ""  HCU
 SG_ FCOReq : 289|2@0+ (1,0) [0|3] ""  HCU
 SG_ EngSpdLim : 311|11@0+ (4,0) [0|8188] "rpm"  HCU
 SG_ RollingCounter_ECM_HP6 : 315|4@0+ (1,0) [0|15] ""  HCU
 SG_ CheckSum_ECM_PT7 : 327|8@0+ (1,0) [0|255] ""  HCU
 SG_ EngState_PHEV : 351|3@0+ (1,0) [0|7] ""  GW,HCU,EDC,EPS
 SG_ EngStalled : 348|1@0+ (1,0) [0|1] ""  HCU
 SG_ CruiseCtrlSts_PHEV : 375|4@0+ (1,0) [0|15] ""  GW,HCU,DCT
 SG_ IdleSpdDmd : 382|1@0+ (1,0) [0|1] ""  HCU
 SG_ IdleSpdSts : 381|1@0+ (1,0) [0|1] ""  HCU
 SG_ RollingCounter_ECM_PT7 : 379|4@0+ (1,0) [0|15] ""  HCU

BO_ 266 DCT9: 8 DCT
 SG_ TCU_Auth_1 : 7|64@0+ (1,0) [0|1.84467440737096E+019] ""  GW

BO_ 267 DCT10: 8 DCT
 SG_ TCU_Auth_2 : 7|64@0+ (1,0) [0|1.84467440737096E+019] ""  GW

BO_ 270 PEPS8: 8 GW
 SG_ TCUAuth_PEPS_1 : 7|64@0+ (1,0) [0|1.84467440737096E+019] ""  DCT

BO_ 271 PEPS9: 8 GW
 SG_ TCUAuth_PEPS_2 : 7|64@0+ (1,0) [0|1.84467440737096E+019] ""  DCT

BO_ 288 Ibooster_FD2: 64 Ibooster
 SG_ Checksum_Ibooster2 : 7|8@0+ (1,0) [0|255] ""  ESP
 SG_ IB_Cmpatbltyindcd : 15|4@0+ (1,0) [0|15] ""  ESP
 SG_ IB_BrkPedalAppld : 11|1@0+ (1,0) [0|1] ""  GW,HCU,ESP
 SG_ IB_BrkPedalAppldVld : 10|2@0+ (1,0) [0|3] ""  GW,HCU,ESP
 SG_ IB_HBCReq : 8|1@0+ (1,0) [0|1] ""  ESP
 SG_ IB_PressRunout : 23|8@0+ (1,0) [0|250] "bar"  ESP
 SG_ IB_PressRunoutVld : 31|2@0+ (1,0) [0|3] ""  ESP
 SG_ IB_DiagActv : 29|1@0+ (1,0) [0|1] ""  ESP
 SG_ IB_RPRMod : 28|3@0+ (1,0) [0|5] ""  ESP
 SG_ IB_PressForceBldPotialVld : 25|2@0+ (1,0) [0|3] ""  ESP
 SG_ IB_PressForceBldPotial : 39|8@0+ (0.5,0) [0|125] "bar"  ESP
 SG_ IB_BLA : 47|1@0+ (1,0) [0|1] "" Vector__XXX
 SG_ IB_Warn : 46|1@0+ (1,0) [0|1] ""  GW,ESP
 SG_ IBooster_MILSts : 43|1@0+ (1,0) [0|1] ""  HCU
 SG_ RollingCounter_Ibooster2 : 59|4@0+ (1,0) [0|15] ""  ESP
 SG_ CheckSum_ABS1 : 135|8@0+ (1,0) [0|255] ""  GW
 SG_ FLWheelDriveDirection : 143|2@0+ (1,0) [0|3] ""  GW
 SG_ FLWheelSpdVld : 141|1@0+ (1,0) [0|1] ""  GW
 SG_ FLWheelSpd : 140|13@0+ (0.05625,0) [0|299.98125] "km/h"  GW
 SG_ FRWheelDriveDirection : 159|2@0+ (1,0) [0|3] ""  GW
 SG_ FRWheelSpdVld : 157|1@0+ (1,0) [0|1] ""  GW
 SG_ FRWheelSpd : 156|13@0+ (0.05625,0) [0|299.98125] "km/h"  GW
 SG_ WssFLEdgesSum : 175|8@0+ (1,0) [0|255] ""  GW
 SG_ WssFREdgesSum : 183|8@0+ (1,0) [0|255] ""  GW
 SG_ WssFLEdgesSumVld : 191|1@0+ (1,0) [0|1] ""  GW
 SG_ WssFREdgesSumVld : 190|1@0+ (1,0) [0|1] ""  GW
 SG_ RollingCounter_ABS1 : 187|4@0+ (1,0) [0|15] ""  GW
 SG_ CheckSum_ABS3 : 199|8@0+ (1,0) [0|255] ""  GW
 SG_ VehSpdVld : 205|1@0+ (1,0) [0|1] ""  GW
 SG_ VehSpd : 204|13@0+ (0.05625,0) [0|299.98125] "kph"  GW
 SG_ RollingCounter_ABS3 : 251|4@0+ (1,0) [0|15] ""  GW
 SG_ CheckSum_IBooster_FD2_5 : 263|8@0+ (1,0) [0|255] ""  GW,DCT,ESP
 SG_ L3VLCADactive : 271|1@0+ (1,0) [0|1] ""  GW
 SG_ L3mainVMCavailiable : 270|2@0+ (1,0) [0|3] ""  GW
 SG_ VLC_TgtGear : 268|3@0+ (1,0) [0|7] ""  DCT
 SG_ RollingCounter_Booster_FD2_5 : 315|4@0+ (1,0) [0|15] ""  GW,DCT,ESP
 SG_ CheckSum_ABS2 : 327|8@0+ (1,0) [0|255] ""  GW
 SG_ RLWheelDriveDirection : 335|2@0+ (1,0) [0|3] ""  GW
 SG_ RLWheelSpdVld : 333|1@0+ (1,0) [0|1] ""  GW
 SG_ RLWheelSpd : 332|13@0+ (0.05625,0) [0|299.98125] "km/h"  GW
 SG_ RRWheelDriveDirection : 351|2@0+ (1,0) [0|3] ""  GW
 SG_ RRWheelSpdVld : 349|1@0+ (1,0) [0|1] ""  GW
 SG_ RRWheelSpd : 348|13@0+ (0.05625,0) [0|299.98125] "km/h"  GW
 SG_ WssRREdgesSum : 367|8@0+ (1,0) [0|255] ""  GW
 SG_ WssRLEdgesSum : 375|8@0+ (1,0) [0|255] ""  GW
 SG_ WssRLEdgesSumVld : 383|1@0+ (1,0) [0|1] ""  GW
 SG_ WssRREdgesSumVld : 382|1@0+ (1,0) [0|1] ""  GW
 SG_ RollingCounter_ABS2 : 379|4@0+ (1,0) [0|15] ""  GW

BO_ 299 IFC_FD1: 64 GW
 SG_ Checksum_IFC1 : 71|8@0+ (1,0) [0|255] ""  EPS
 SG_ IFCTrqOvlCmdProtnValue : 79|14@0+ (1,0) [0|16383] ""  EPS
 SG_ IFCTrqOvlCmdReqValue : 103|11@0+ (0.01,-10.23) [-10.23|10.24] "Nm"  EPS
 SG_ IFCFuncTrqCmdReqFlag : 127|3@0+ (1,0) [0|7] ""  EPS
 SG_ IFCVibrationWarning : 105|2@0+ (1,0) [0|3] ""  EPS
 SG_ RollingCounter_IFC1 : 123|4@0+ (1,0) [0|15] ""  EPS

BO_ 303 HCU_FD3: 64 HCU
 SG_ Checksum_HCU_PT5 : 71|8@0+ (1,0) [0|255] ""  GW,DCT,ESP
 SG_ HCU_DrvMod : 79|4@0+ (1,0) [0|15] ""  GW,DCT,ESP,ECM
 SG_ HCU_PTDrvMod : 75|3@0+ (1,0) [0|7] ""  GW,ESP
 SG_ DrvTrqReqOvld : 87|2@0+ (1,0) [0|3] ""  GW
 SG_ HCUImmoAuthRes : 85|2@0+ (1,0) [0|3] ""  GW
 SG_ HCU_EPSEnable : 83|1@0+ (1,0) [0|1] ""  EPS
 SG_ HCU_EngLimpHome : 82|1@0+ (1,0) [0|1] ""  DCT
 SG_ HCU_VitlAccelPedalPosn_CrpValid : 81|1@0+ (1,0) [0|1] ""  ESP
 SG_ HCU_EVLmpSts : 80|1@0+ (1,0) [0|1] ""  GW
 SG_ HCU_ECODrvHabit_Indcn : 95|8@0+ (0.1,-10) [-10|10] ""  GW
 SG_ HCU_TotDrvReqPower : 103|8@0+ (1,-100) [-100|100] "%"  GW
 SG_ HCU_VitlAccelPedalPosn_Crp : 111|8@0+ (0.3937,0) [0|100.3935] "%"  ESP
 SG_ HCU_AvailPower_TM : 119|8@0+ (0.5,0) [0|50] "%"  GW
 SG_ RollingCounter_HCU_PT5 : 123|4@0+ (1,0) [0|15] ""  GW,DCT,ESP
 SG_ Checksum_HCU_HP6 : 135|8@0+ (1,0) [0|255] ""  DCT,ESP
 SG_ IdleSpdSetPointReq : 143|11@0+ (2,0) [0|4090] "rpm"  DCT,ECM
 SG_ HCU_VirtLoad_FA : 148|5@0+ (1,0) [0|31] ""  DCT
 SG_ HCU_VirtAccelPedalPosn_FA : 175|8@0+ (0.784314,-100) [-100|100] "%"  DCT
 SG_ HCU_GearShftInhibitReq_FA : 183|1@0+ (1,0) [0|1] ""  DCT
 SG_ HCU_EngSts : 182|3@0+ (1,0) [0|7] ""  DCT,ESP,ECM
 SG_ HCU_VirtAccelPedalPosn_FAValid : 177|1@0+ (1,0) [0|1] ""  DCT
 SG_ CrsCtrlSwSts_ASIL : 176|1@0+ (1,0) [0|1] ""  ECM
 SG_ CrsCtrlSwSts_NoClrSpd : 191|1@0+ (1,0) [0|1] ""  ECM
 SG_ CrsCtrlSwSts_ClrSpd : 190|1@0+ (1,0) [0|1] ""  ECM
 SG_ HCU_APS_Available : 188|1@0+ (1,0) [0|1] ""  GW
 SG_ RollingCounter_HCU_HP6 : 187|4@0+ (1,0) [0|15] ""  DCT,ESP
 SG_ HCU_SaveModChrgMod_OBD : 206|3@0+ (1,0) [0|7] ""  ECM
 SG_ HCU_VehSpdLimit : 215|8@0+ (2,0) [0|510] "km/h"  GW

BO_ 311 ESP_FD2: 64 ESP
 SG_ CheckSum_ESP_FD2_1 : 7|8@0+ (1,0) [0|255] ""  GW,DCT,ECM,Ibooster
 SG_ L12VLCADactive : 63|1@0+ (1,0) [0|1] ""  GW,DCT,ECM
 SG_ L12mainVMCavailiable : 62|1@0+ (1,0) [0|1] ""  GW,DCT,ECM
 SG_ WssCoreMonRob : 15|8@0+ (1,0) [0|255] ""  Ibooster
 SG_ TtcFactor_FL : 23|16@0+ (1E-005,0.7) [0.7|1.3] ""  Ibooster
 SG_ TtcFactor_FR : 39|16@0+ (1E-005,0.7) [0.7|1.3] ""  Ibooster
 SG_ RollingCounter_ESP_FD2_1 : 59|4@0+ (1,0) [0|15] ""  GW,DCT,ECM,Ibooster
 SG_ CheckSum_ESP2 : 71|8@0+ (1,0) [0|255] ""  GW,HCU,DCT
 SG_ BrkDskOvrheatd : 75|1@0+ (1,0) [0|1] ""  GW
 SG_ NoBrkForce : 76|1@0+ (1,0) [0|1] ""  GW,HCU
 SG_ VehStandstill : 78|2@0+ (1,0) [0|3] ""  GW,HCU
 SG_ SwtOffCrsCtrl : 79|1@0+ (1,0) [0|1] ""  HCU
 SG_ HHCSts : 80|1@0+ (1,0) [0|1] ""  HCU,DCT
 SG_ AEBIBActv : 81|1@0+ (1,0) [0|1] ""  GW,HCU,DCT
 SG_ AEBBAActv : 82|1@0+ (1,0) [0|1] ""  GW,HCU
 SG_ AEBAvailable : 83|1@0+ (1,0) [0|1] ""  GW,HCU,DCT
 SG_ ABPAvailable : 84|1@0+ (1,0) [0|1] ""  GW,HCU
 SG_ ABPActv : 85|1@0+ (1,0) [0|1] ""  GW,HCU
 SG_ ABAavailable : 86|1@0+ (1,0) [0|1] ""  GW,HCU
 SG_ ABAActv : 87|1@0+ (1,0) [0|1] ""  GW,HCU
 SG_ HDCFault : 89|2@0+ (1,0) [0|3] ""  GW,HCU
 SG_ HDCCtrl : 91|2@0+ (1,0) [0|2] ""  GW,HCU
 SG_ CDDActv : 92|1@0+ (1,0) [0|1] ""  GW,HCU,DCT
 SG_ CDDAvailable : 93|1@0+ (1,0) [0|1] ""  GW,HCU,DCT
 SG_ AWBAvailable : 94|1@0+ (1,0) [0|1] ""  GW,HCU
 SG_ AWBActv : 95|1@0+ (1,0) [0|1] ""  GW,HCU
 SG_ AVHErrSts : 99|2@0+ (1,0) [0|3] ""  GW,HCU,DCT
 SG_ AVHSts : 101|2@0+ (1,0) [0|2] ""  GW,HCU,DCT
 SG_ CDPVld : 102|1@0+ (1,0) [0|1] ""  HCU,DCT
 SG_ CDPActv : 103|1@0+ (1,0) [0|1] ""  GW,HCU,DCT
 SG_ SysOperatingMod_ESP : 127|4@0+ (1,0) [0|15] ""  HCU
 SG_ SCMActv : 72|1@0+ (1,0) [0|1] "" Vector__XXX
 SG_ CTABrkAvailable : 74|1@0+ (1,0) [0|1] ""  GW
 SG_ RollingCounter_ESP2 : 123|4@0+ (1,0) [0|15] ""  GW,HCU,DCT
 SG_ CheckSum_ESP1 : 135|8@0+ (1,0) [0|255] ""  GW,HCU
 SG_ ESPFuncOffSts : 140|1@0+ (1,0) [0|1] ""  GW,HCU
 SG_ ESPActvInfoLmp : 141|1@0+ (1,0) [0|1] ""  GW,HCU
 SG_ ESPBrkLmpCtrl : 142|1@0+ (1,0) [0|1] ""  GW,DCT
 SG_ ESPFailSts : 143|1@0+ (1,0) [0|1] ""  GW,HCU,DCT
 SG_ ESP_MasterCylBrkPressVld : 144|1@0+ (1,0) [0|1] ""  GW,HCU,DCT
 SG_ GearShftInhibitReq_FA : 145|1@0+ (1,0) [0|1] ""  HCU,DCT
 SG_ MSRActv : 149|1@0+ (1,0) [0|1] ""  GW,HCU
 SG_ VDCActv : 148|1@0+ (1,0) [0|1] ""  GW,HCU,DCT
 SG_ PTCActv : 150|1@0+ (1,0) [0|1] ""  GW,HCU,DCT
 SG_ BTCActv : 151|1@0+ (1,0) [0|1] ""  GW,HCU,DCT
 SG_ MSRActv_RA : 174|1@0+ (1,0) [0|1] ""  GW,HCU
 SG_ PTCActv_RA : 136|1@0+ (1,0) [0|1] ""  GW,HCU
 SG_ BTCActv_RA : 137|1@0+ (1,0) [0|1] ""  GW,HCU
 SG_ ESP_MasterCylBrkPress : 159|16@0+ (0.03125,-42.5) [-42.5|425] "bar"  GW,HCU,DCT
 SG_ TrqMaxLim : 171|12@0+ (1,0) [0|4094] "Nm" Vector__XXX
 SG_ RollingCounter_ESP1 : 187|4@0+ (1,0) [0|15] ""  GW
 SG_ CheckSum_ESP7 : 199|8@0+ (1,0) [0|255] ""  GW,DCT
 SG_ ESP_MEBBrkAvail : 209|1@0+ (1,0) [0|1] ""  GW
 SG_ APS_EngTrqReqEna : 247|1@0+ (1,0) [0|1] ""  GW,HCU
 SG_ EngTrqReq : 231|16@0+ (0.0030518,-100) [-100|99.999713] "%"  GW,HCU
 SG_ ESP_APS_GearBoxEna : 252|1@0+ (1,0) [0|1] ""  DCT
 SG_ ESP_APS_TgtGear : 242|3@0+ (1,0) [0|7] ""  DCT
 SG_ FourWhlsBrkTrq : 207|14@0+ (1,0) [0|16383] ""  GW,HCU,DCT
 SG_ LgtCtrlrAvail : 255|3@0+ (1,0) [0|7] ""  GW
 SG_ LgtCtrlrFailr : 220|3@0+ (1,0) [0|7] ""  GW,DCT
 SG_ LgtCtrlrSts : 223|3@0+ (1,0) [0|7] ""  GW
 SG_ RollingCounter_ESP7 : 251|4@0+ (1,0) [0|15] ""  GW,DCT
 SG_ CheckSum_ESP4 : 263|8@0+ (1,0) [0|255] "" Vector__XXX
 SG_ DrvTrqIncReq_FA : 271|16@0+ (0.0030518,-100) [-100|99.999713] "%"  HCU,DCT
 SG_ DrvTrqRedFastReq_FA : 287|16@0+ (0.0030518,-100) [-100|99.999713] "%"  HCU,DCT
 SG_ DrvTrqRedSlowReq_FA : 303|16@0+ (0.0030518,-100) [-100|99.999713] "%"  HCU,DCT
 SG_ DrvTrqRedReqActv_FA : 319|1@0+ (1,0) [0|1] ""  HCU,DCT
 SG_ DrvTrqIncReqActv_FA : 318|1@0+ (1,0) [0|1] ""  HCU,DCT
 SG_ RollingCounter_ESP4 : 315|4@0+ (1,0) [0|15] "" Vector__XXX
 SG_ CheckSum_ABS3 : 327|8@0+ (1,0) [0|255] ""  GW,ECM,Ibooster,EPS
 SG_ ABSFailSts : 335|1@0+ (1,0) [0|1] ""  GW,HCU,DCT
 SG_ EBDFailSts : 334|1@0+ (1,0) [0|1] ""  GW,HCU
 SG_ VehSpdVld : 333|1@0+ (1,0) [0|1] ""  GW,HCU,DCT,ECM,Ibooster,EDC,EPS
 SG_ VehSpd : 332|13@0+ (0.05625,0) [0|299.98125] "kph"  GW,HCU,DCT,ECM,Ibooster,EDC,EPS
 SG_ EBDActv : 351|1@0+ (1,0) [0|1] ""  GW,HCU,DCT
 SG_ ABSActv : 347|1@0+ (1,0) [0|1] ""  GW,HCU,DCT
 SG_ VehOdoInfoSts : 346|1@0+ (1,0) [0|1] ""  GW
 SG_ VehOdoInfo : 345|10@0+ (1,0) [0|999] "m"  GW
 SG_ ESP_MILSts : 349|1@0+ (1,0) [0|1] ""  HCU
 SG_ RollingCounter_ABS3 : 379|4@0+ (1,0) [0|15] ""  GW,ECM,Ibooster,EPS
 SG_ CheckSum_ESP_FD2_7 : 391|8@0+ (1,0) [0|255] ""  Ibooster
 SG_ TtcFactor_RL : 399|16@0+ (1E-005,0.7) [0.7|1.3] ""  Ibooster
 SG_ TtcFactor_RR : 415|16@0+ (1E-005,0.7) [0.7|1.3] ""  Ibooster
 SG_ RollingCounter_ESP_FD2_7 : 443|4@0+ (1,0) [0|15] ""  Ibooster

BO_ 315 ESP_FD3: 64 ESP
 SG_ CheckSum_ABS1 : 7|8@0+ (1,0) [0|255] ""  GW,DCT,ECM,EPS
 SG_ FLWheelDriveDirection : 15|2@0+ (1,0) [0|3] ""  GW,HCU,DCT,EPS
 SG_ FLWheelSpdVld : 13|1@0+ (1,0) [0|1] ""  GW,HCU,DCT,ECM,EDC,EPS
 SG_ FLWheelSpd : 12|13@0+ (0.05625,0) [0|299.98125] "km/h"  GW,HCU,DCT,ECM,EDC,EPS
 SG_ FRWheelDriveDirection : 31|2@0+ (1,0) [0|3] ""  GW,HCU,DCT,EPS
 SG_ FRWheelSpdVld : 29|1@0+ (1,0) [0|1] ""  GW,HCU,DCT,ECM,EDC,EPS
 SG_ FRWheelSpd : 28|13@0+ (0.05625,0) [0|299.98125] "km/h"  GW,HCU,DCT,ECM,EDC,EPS
 SG_ WssFLEdgesSum : 47|8@0+ (1,0) [0|255] ""  GW
 SG_ WssFREdgesSum : 55|8@0+ (1,0) [0|255] ""  GW
 SG_ WssFLEdgesSumVld : 63|1@0+ (1,0) [0|1] ""  GW
 SG_ WssFREdgesSumVld : 62|1@0+ (1,0) [0|1] ""  GW
 SG_ RollingCounter_ABS1 : 59|4@0+ (1,0) [0|15] ""  GW,DCT,ECM,EPS
 SG_ CheckSum_ABS2 : 327|8@0+ (1,0) [0|255] ""  GW,DCT,ECM,EPS
 SG_ RLWheelDriveDirection : 335|2@0+ (1,0) [0|3] ""  GW,HCU,DCT,EPS
 SG_ RLWheelSpdVld : 333|1@0+ (1,0) [0|1] ""  GW,HCU,DCT,ECM,EDC,EPS
 SG_ RLWheelSpd : 332|13@0+ (0.05625,0) [0|299.98125] "km/h"  GW,HCU,DCT,ECM,EDC,EPS
 SG_ RRWheelDriveDirection : 351|2@0+ (1,0) [0|3] ""  GW,HCU,DCT,EPS
 SG_ RRWheelSpdVld : 349|1@0+ (1,0) [0|1] ""  GW,HCU,DCT,ECM,EDC,EPS
 SG_ RRWheelSpd : 348|13@0+ (0.05625,0) [0|299.98125] "km/h"  GW,HCU,DCT,ECM,EDC,EPS
 SG_ WssRREdgesSum : 367|8@0+ (1,0) [0|255] ""  GW
 SG_ WssRLEdgesSum : 375|8@0+ (1,0) [0|255] ""  GW
 SG_ WssRLEdgesSumVld : 383|1@0+ (1,0) [0|1] ""  GW
 SG_ WssRREdgesSumVld : 382|1@0+ (1,0) [0|1] ""  GW
 SG_ RollingCounter_ABS2 : 379|4@0+ (1,0) [0|15] ""  GW,DCT,ECM,EPS
 SG_ CheckSum_EPB1 : 71|8@0+ (1,0) [0|255] ""  GW,EPS
 SG_ EPB_SwtPosnVld : 80|1@0+ (1,0) [0|1] ""  GW,HCU
 SG_ PressBrakePedalPointOut : 81|1@0+ (1,0) [0|1] "N/A"  GW
 SG_ EPBErrSts : 91|2@0+ (1,0) [0|3] ""  GW,HCU,DCT
 SG_ EPBSts : 93|2@0+ (1,0) [0|3] ""  GW,HCU,DCT
 SG_ EPB_SwtPosn : 95|2@0+ (1,0) [0|3] ""  GW,HCU
 SG_ EPBTextDisp : 103|4@0+ (1,0) [0|15] "N/A"  GW
 SG_ ESP_DSTTrqReq : 111|10@0+ (0.01,0) [0|8] "Nm"  EPS
 SG_ ESP_DSTTrqReqDir : 117|1@0+ (1,0) [0|1] ""  EPS
 SG_ ESP_DSTSts : 116|3@0+ (1,0) [0|7] ""  EPS
 SG_ EPBRedLmpSts : 89|2@0+ (1,0) [0|3] ""  GW
 SG_ RollingCounter_EPB1 : 123|4@0+ (1,0) [0|15] ""  GW,EPS
 SG_ CheckSum_ESP13 : 199|8@0+ (1,0) [0|255] "" Vector__XXX
 SG_ DrvTrqIncReq_RA : 207|16@0+ (0.0030518,-100) [-100|99.999713] "%"  HCU
 SG_ DrvTrqRedReq_RA : 223|16@0+ (0.0030518,-100) [-100|99.999713] "%"  HCU
 SG_ GearShftInhibitReq_RA : 239|1@0+ (1,0) [0|1] ""  HCU
 SG_ DrvTrqRedReqActv_RA : 232|1@0+ (1,0) [0|1] ""  HCU
 SG_ DrvTrqIncReqActv_RA : 255|1@0+ (1,0) [0|1] ""  HCU
 SG_ RollingCounter_ESP13 : 251|4@0+ (1,0) [0|15] "" Vector__XXX
 SG_ CheckSum_ESP_FD3_7 : 391|8@0+ (1,0) [0|255] ""  GW,HCU,DCT,Ibooster
 SG_ L3VLCADactive : 422|1@0+ (1,0) [0|1] ""  GW
 SG_ L3mainVMCavailiable : 421|2@0+ (1,0) [0|3] ""  GW
 SG_ VLC_ESP_FuelCutOffPrevention : 419|1@0+ (1,0) [0|1] ""  GW,HCU
 SG_ VLC_ESP_State : 418|2@0+ (1,0) [0|3] ""  GW,HCU
 SG_ LSMPosLongACapbl : 407|2@0+ (1,0) [0|3] ""  GW
 SG_ LSMSubMTReqAvailable : 392|1@0+ (1,0) [0|1] ""  GW
 SG_ LSMSubMTLevelEcho : 405|2@0+ (1,0) [0|3] ""  GW
 SG_ LSMSubMTLongEcho : 403|2@0+ (1,0) [0|3] ""  GW
 SG_ LSMSubMTReqEcho : 401|2@0+ (1,0) [0|2] ""  GW
 SG_ Lsm12ComfortAvl : 415|2@0+ (1,0) [0|3] ""  GW
 SG_ Lsm12EmergencyAvl : 413|2@0+ (1,0) [0|3] ""  GW
 SG_ Lsm23Avl : 411|2@0+ (1,0) [0|3] ""  GW
 SG_ LSMGearRequest : 409|2@0+ (1,0) [0|2] ""  GW,DCT
 SG_ ParkPawlRequest : 423|1@0+ (1,0) [0|1] ""  GW,DCT
 SG_ RollingCounter_ESP_FD3_7 : 443|4@0+ (1,0) [0|15] ""  GW,HCU,DCT,Ibooster

BO_ 317 APS4: 8 GW
 SG_ Checksum_APS4 : 7|8@0+ (1,0) [0|255] ""  ESP
 SG_ MEB_BrkgReqValue : 55|8@0+ (0.05,-10) [-10|0] "m/s^2"  ESP
 SG_ MEB_BrkgReq : 19|1@0+ (1,0) [0|1] ""  ESP
 SG_ MEBErrSts : 20|1@0+ (1,0) [0|1] ""  ESP
 SG_ MEB_AVHReq : 40|1@0+ (1,0) [0|1] ""  ESP
 SG_ RollingCounter_APS4 : 59|4@0+ (1,0) [0|15] ""  ESP

BO_ 323 ACC_FD1: 64 GW
 SG_ HWP_MotTypeReqMode_L2 : 55|2@0+ (1,0) [0|3] ""  HCU,ESP
 SG_ HWP_MotTypeReqLong_L2 : 53|2@0+ (1,0) [0|4] ""  ESP
 SG_ HWP_ShutdownReq_L2 : 51|1@0+ (1,0) [0|1] ""  ESP
 SG_ HWP_TgtAccel_L2 : 15|8@0+ (1,-10) [-10|10] ""  ESP
 SG_ HWP_UpperLimit_L2 : 23|8@0+ (0.1,0) [0|12.7] ""  ESP
 SG_ HWP_LowerLimit_L2 : 31|8@0+ (0.1,-12.7) [-12.7|0] ""  ESP
 SG_ HWP_SecureReq_L2 : 62|1@0+ (1,0) [0|1] ""  ESP
 SG_ HWP_AEBAvail : 61|1@0+ (1,0) [0|1] ""  ESP
 SG_ HWP_ACCAvail : 60|1@0+ (1,0) [0|1] ""  ESP
 SG_ HWP_TgtAccelCmftUpprLimVal_L2 : 39|8@0+ (0.0125,0) [0|3.125] ""  ESP
 SG_ HWP_TgtAccelCmftLwrLimVal_L2 : 47|8@0+ (0.0125,0) [0|3.125] ""  ESP
 SG_ HWP_UseTgtAccelCmftUpprLimVal_L2 : 63|1@0+ (1,0) [0|1] ""  ESP
 SG_ Checksum_ACC1 : 71|8@0+ (1,0) [0|255] ""  ESP
 SG_ Longctrl_VehHldReq : 79|1@0+ (1,0) [0|1] ""  ESP
 SG_ Longctrl_DrvOFF_Req : 78|1@0+ (1,0) [0|1] ""  ESP
 SG_ Longctrl_ModSts : 77|4@0+ (1,0) [0|15] ""  HCU,DCT,ESP
 SG_ Longctrl_Decel_Req : 72|1@0+ (1,0) [0|1] ""  ESP
 SG_ Longctrl_DecelToStopReq : 101|1@0+ (1,0) [0|1] ""  ESP
 SG_ Longctrl_Decel_ReqValue : 111|8@0+ (0.05,-7) [-7|5.75] "m/s^2"  ESP
 SG_ Longctrl_ParkShiftReq : 99|2@0+ (1,0) [0|3] ""  DCT
 SG_ RollingCounter_ACC1 : 123|4@0+ (1,0) [0|15] ""  ESP
 SG_ Checksum_ACC10 : 199|8@0+ (1,0) [0|255] ""  HCU,DCT
 SG_ Longctrl_HCUTrqReq : 223|16@0+ (0.5,-16384) [-16384|16383.5] "NM"  HCU,DCT
 SG_ Longctrl_HCUTrqReqActive : 239|1@0+ (1,0) [0|1] ""  HCU,DCT
 SG_ RollingCounter_ACC10 : 251|4@0+ (1,0) [0|15] ""  HCU,DCT

BO_ 327 EPS_FD1: 64 EPS
 SG_ CheckSum_EPS1 : 7|8@0+ (1,0) [0|255] ""  GW,ESP
 SG_ EPS_DSTCtrlSts : 11|3@0+ (1,0) [0|7] ""  ESP
 SG_ EPS_FailSts : 13|2@0+ (1,0) [0|3] ""  GW
 SG_ EPS_TrqSnsrSts : 14|1@0+ (1,0) [0|1] ""  GW
 SG_ EPS_InterferDetd : 31|1@0+ (1,0) [0|1] ""  GW
 SG_ EPS_InterferDetdVld : 30|1@0+ (1,0) [0|1] ""  GW
 SG_ EPS_AvailSts : 29|2@0+ (1,0) [0|3] ""  GW
 SG_ EPS_SteerMod : 55|3@0+ (1,0) [0|7] ""  GW
 SG_ RollingCounter_EPS1 : 59|4@0+ (1,0) [0|15] ""  GW,ESP
 SG_ CheckSum_EPS2 : 71|8@0+ (1,0) [0|255] ""  GW,ESP
 SG_ EPS_LKATorqOvrlDlvd : 111|16@0+ (0.01,-15) [-15|15] "Nm"  GW
 SG_ EPS_LKATorqOvrlDlvdVld : 127|1@0+ (1,0) [0|1] ""  GW
 SG_ EPS_LKATrqOvlDlvdSts : 125|2@0+ (1,0) [0|3] ""  GW
 SG_ EPS_DSTTrqOvl : 95|16@0+ (0.01,-15) [-15|15] "Nm"  ESP
 SG_ EPS_DrvInpTrqVal_HighReslolution : 79|12@0+ (0.015625,-31.984375) [-31.984375|32] "Nm"  GW,ESP
 SG_ RollingCounter_EPS2 : 123|4@0+ (1,0) [0|15] ""  GW,ESP
 SG_ CheckSum_EPS3 : 135|8@0+ (1,0) [0|255] ""  GW
 SG_ ElecPwrSteerCpby : 143|2@0+ (1,0) [0|2] ""  GW
 SG_ EPS_SteerWheelAng : 151|15@0+ (0.1,0) [0|780] "deg"  GW
 SG_ EPS_SteerWheelAngSign : 152|1@0+ (1,0) [0|1] ""  GW
 SG_ EPS_SteerWheelSpd : 167|15@0+ (0.1,0) [0|1016] "deg/s"  GW
 SG_ EPS_SteerWheelSpdSign : 168|1@0+ (1,0) [0|1] ""  GW
 SG_ EPS_HWPHndShkResp : 141|1@0+ (1,0) [0|1] ""  GW
 SG_ RollingCounter_EPS3 : 187|4@0+ (1,0) [0|15] ""  GW
 SG_ FreshnessValue_EPS_FD1 : 455|16@0+ (1,0) [0|65535] ""  GW
 SG_ MAC_Check_EPS_FD1 : 471|48@0+ (1,0) [0|281474976710655] ""  GW

BO_ 344 IDC_L3_FD1: 64 GW
 SG_ Checksum_IDC_L3_1 : 7|8@0+ (1,0) [0|255] ""  EPS
 SG_ HWP_ReqCtrlEPS : 55|1@0+ (1,0) [0|1] ""  EPS
 SG_ HWP_ReqCtrlEPSVld : 54|1@0+ (1,0) [0|1] ""  EPS
 SG_ HWP_AngCmdReqVal : 15|14@0+ (0.1,-780) [-780|780] "°"  EPS
 SG_ HWP_AngCmdReqValVld : 53|1@0+ (1,0) [0|1] ""  EPS
 SG_ HWP_HapcWarnReq : 52|2@0+ (1,0) [0|3] ""  EPS
 SG_ HWP_TrqOvlCmdProtnValue : 17|14@0+ (1,0) [0|16383] ""  EPS
 SG_ HWP_TrqOvlCmdReqValue : 35|11@0+ (0.01,-10.23) [-10.23|10.24] "Nm"  EPS
 SG_ HWP_FuncTrqCmdReqFlag : 50|3@0+ (1,0) [0|7] ""  EPS
 SG_ RollingCounter_IDC_L3_1 : 59|4@0+ (1,0) [0|15] ""  EPS
 SG_ HWP_WorkReq : 98|3@0+ (1,0) [0|7] ""  DCT,EPS
 SG_ HWP_WorkReqVld : 111|1@0+ (1,0) [0|1] ""  DCT,EPS
 SG_ HWP_TgtGearReq : 95|3@0+ (1,0) [0|7] ""  DCT
 SG_ HWP_TgtGearReqVld : 92|1@0+ (1,0) [0|1] ""  DCT
 SG_ HWP_lgt_ModSts : 102|4@0+ (1,0) [0|15] ""  DCT,ESP,Ibooster
 SG_ HWP_lgt_VehHldReq : 167|1@0+ (1,0) [0|1] ""  ESP,Ibooster
 SG_ HWP_lgt_DrvOFF_Req : 166|1@0+ (1,0) [0|1] ""  ESP,Ibooster
 SG_ HWP_lgt_DecelToStopReq : 164|1@0+ (1,0) [0|1] ""  ESP,Ibooster
 SG_ HWP_EPBCtrlReq : 183|1@0+ (1,0) [0|1] ""  ESP
 SG_ HWP_EPBCtrlReqVld : 182|1@0+ (1,0) [0|1] ""  ESP
 SG_ HWP_Lgt_HCUTrqReq : 207|16@0+ (0.5,-16384) [-16384|16383.5] "NM"  HCU
 SG_ HWP_Lgt_HCUTrqReqVld : 223|1@0+ (1,0) [0|1] ""  HCU
 SG_ HWP_Lgt_HCUTrqReqActv : 222|1@0+ (1,0) [0|1] ""  HCU
 SG_ HWP_Lgt_HCUTrqReqActvVld : 221|1@0+ (1,0) [0|1] ""  HCU
 SG_ HWP_HCUOvrdReq : 220|1@0+ (1,0) [0|1] ""  HCU
 SG_ HWP_MotTypeReqMode : 319|2@0+ (1,0) [0|3] ""  HCU,ESP,Ibooster
 SG_ HWP_MotTypeReqLong : 317|2@0+ (1,0) [0|3] ""  ESP,Ibooster
 SG_ HWP_ShutdownReq : 311|1@0+ (1,0) [0|1] ""  ESP,Ibooster
 SG_ HWP_TgtAccel : 271|8@0+ (1,-10) [-10|10] ""  ESP,Ibooster
 SG_ HWP_UpperLimit : 279|8@0+ (0.1,0) [0|12.7] ""  ESP,Ibooster
 SG_ HWP_LowerLimit : 287|8@0+ (0.1,-12.7) [-12.7|0] ""  ESP,Ibooster
 SG_ HWP_SecureReq : 309|1@0+ (1,0) [0|1] ""  ESP,Ibooster
 SG_ HWP_SuprAvail : 308|1@0+ (1,0) [0|1] ""  ESP,Ibooster
 SG_ HWP_TgtAccelCmftUpprLimVal : 295|8@0+ (0.0125,0) [0|3.125] ""  ESP,Ibooster
 SG_ HWP_TgtAccelCmftLwrLimVal : 303|8@0+ (0.0125,0) [0|3.125] ""  ESP,Ibooster
 SG_ HWP_UseTgtAccelCmftUpprLimVal : 310|1@0+ (1,0) [0|1] ""  ESP,Ibooster
 SG_ FreshnessValue_IDC_L3_FD1 : 455|16@0+ (1,0) [0|65535] ""  EPS
 SG_ MAC_Check_IDC_L3_FD1 : 471|48@0+ (1,0) [0|281474976710655] ""  EPS

BO_ 347 HAP_FD1: 64 GW
 SG_ Checksum_APS1 : 71|8@0+ (1,0) [0|255] ""  EPS
 SG_ APS_ReqEPSTgtAngValid : 73|1@0+ (1,0) [0|1] ""  EPS
 SG_ APS_ReqCtrlEPS : 72|1@0+ (1,0) [0|1] ""  EPS
 SG_ APS_ReqEPSTgtAng : 87|15@0+ (0.1,0) [-1638.3|1638.3] "deg"  EPS
 SG_ RollingCounter_APS1 : 123|4@0+ (1,0) [0|15] ""  EPS
 SG_ Checksum_APS4 : 135|8@0+ (1,0) [0|255] ""  ESP
 SG_ APS_BrkFctnMod : 143|3@0+ (1,0) [0|7] ""  ESP
 SG_ APS_ESP_TgtGearReq : 140|3@0+ (1,0) [0|7] ""  ESP
 SG_ APS_BrkCategory : 137|2@0+ (1,0) [0|3] ""  ESP
 SG_ APS_BrkModSts : 151|3@0+ (1,0) [0|7] ""  ESP
 SG_ MEBErrSts : 148|1@0+ (1,0) [0|1] ""  ESP
 SG_ MEB_BrkgReq : 147|1@0+ (1,0) [0|1] ""  ESP
 SG_ APS_WorkSts : 146|3@0+ (1,0) [0|7] ""  HCU
 SG_ APS_ESP_SpdLimn : 159|8@0+ (0.1,0) [0|25.5] "kmh"  DCT,ESP
 SG_ APS_ESP_BrkDistance : 167|12@0+ (1,0) [0|4095] "cm"  ESP
 SG_ MEB_AVHReq : 168|1@0+ (1,0) [0|1] ""  ESP
 SG_ MEB_BrkgReqValue : 183|8@0+ (0.05,-10) [-10|0] "m/s^2"  ESP
 SG_ RollingCounter_APS4 : 187|4@0+ (1,0) [0|15] ""  ESP
 SG_ HAP_ESP_LSMSubMTReq : 209|2@0+ (1,0) [0|3] ""  ESP
 SG_ HAP_ESP_LSMSubMTLevel : 226|2@0+ (1,0) [0|3] ""  ESP
 SG_ HAP_ESP_LSMSubMTLong : 239|2@0+ (1,0) [0|3] ""  ESP
 SG_ HAP_ESP_LSMPrefill : 224|1@0+ (1,0) [0|1] ""  ESP
 SG_ HAP_ESP_LSMDistToStop : 207|12@0+ (1,0) [0|4095] "cm"  ESP
 SG_ HAP_ESP_LSMVehDirRq : 237|2@0+ (1,0) [0|3] ""  ESP
 SG_ HAP_ESP_LSMvMaxRq : 223|11@0+ (0.1,0) [0|20] "kph"  ESP
 SG_ HAP_ESP_LSMVehSecReq : 233|1@0+ (1,0) [0|1] ""  ESP
 SG_ HAP_ESP_LSMNudgeReq : 232|1@0+ (1,0) [0|1] ""  ESP
 SG_ HAP_ESP_LSMComfBrakeReq : 235|2@0+ (1,0) [0|3] ""  ESP
 SG_ HAP_ESP_DriverPresenceExternal : 210|1@0+ (1,0) [0|1] ""  ESP
 SG_ HAP_ESP_SafeDrvrHandoverReq : 227|1@0+ (1,0) [0|1] ""  ESP
 SG_ FreshnessValue_HAP_FD1 : 455|16@0+ (1,0) [0|65535] ""  EPS
 SG_ MAC_Check_HAP_FD1 : 471|48@0+ (1,0) [0|281474976710655] ""  EPS

BO_ 367 RSDS_FD1: 64 GW
 SG_ Checksum_RSDS_R_2 : 71|8@0+ (1,0) [0|255] ""  ESP
 SG_ RSDS_Brk_ErrSts : 79|1@0+ (1,0) [0|1] ""  ESP
 SG_ RSDS_BrkgReq : 78|1@0+ (1,0) [0|1] ""  ESP
 SG_ RSDS_BrkgReqVal : 77|8@0+ (0.05,-10) [-10|2.75] "m/s^2"  ESP
 SG_ RollingCounter_RSDS_R_2 : 123|4@0+ (1,0) [0|15] ""  ESP

BO_ 395 AEB_FD1: 64 GW
 SG_ Checksum_AEB1 : 71|8@0+ (1,0) [0|255] ""  ESP
 SG_ AEB_ABA_Level : 79|2@0+ (1,0) [0|3] ""  ESP
 SG_ AEB_ABA_Req : 77|1@0+ (1,0) [0|1] ""  ESP
 SG_ EBA_TgtDecel_Req : 76|1@0+ (1,0) [0|1] ""  ESP
 SG_ AEB_ObjSty : 111|3@0+ (1,0) [0|7] ""  ESP
 SG_ AEB_VehHldReq : 75|1@0+ (1,0) [0|1] ""  ESP
 SG_ AEB_TgtDecel_Req : 74|1@0+ (1,0) [0|1] ""  ESP
 SG_ AEB_TgtDecel_ReqValue : 87|16@0+ (0.000488,-16) [-16|16] "m/s2"  ESP
 SG_ AEB_AWB_Req : 73|1@0+ (1,0) [0|1] ""  ESP
 SG_ AEB_AWB_Level : 103|4@0+ (1,0) [0|15] ""  ESP
 SG_ AEB_ABP_Req : 72|1@0+ (1,0) [0|1] ""  ESP
 SG_ RollingCounter_AEB1 : 123|4@0+ (1,0) [0|15] ""  ESP

BO_ 411 F_PBox1: 8 GW
 SG_ HoodSts_F_Pbox : 21|1@0+ (1,0) [0|1] ""  HCU

BO_ 516 HCU_FD4: 64 HCU
 SG_ CheckSum_HCU_PT7 : 71|8@0+ (1,0) [0|255] ""  GW
 SG_ HCU_HybSysErr_1 : 79|1@0+ (1,0) [0|1] ""  GW
 SG_ HCU_HybSysErr_2 : 78|1@0+ (1,0) [0|1] ""  GW
 SG_ HCU_HybSysErr_3 : 77|1@0+ (1,0) [0|1] ""  GW
 SG_ HCU_HybSysErr_4 : 76|1@0+ (1,0) [0|1] ""  GW
 SG_ HCU_HybSysErr_5 : 75|1@0+ (1,0) [0|1] ""  GW
 SG_ HCU_HybSysErr_6 : 74|1@0+ (1,0) [0|1] ""  GW
 SG_ HCU_HybSysErr_7 : 73|1@0+ (1,0) [0|1] ""  GW
 SG_ HCU_12VSysErrLmpSts : 72|1@0+ (1,0) [0|1] ""  GW
 SG_ HCU_HybSysErrLmpSts : 91|2@0+ (1,0) [0|3] ""  GW
 SG_ HCU_PowerRedWarnLmpCmd : 89|1@0+ (1,0) [0|1] ""  GW
 SG_ HCU_12VSysErr_1 : 88|1@0+ (1,0) [0|1] ""  GW
 SG_ HCU_12VSysErr_2 : 103|1@0+ (1,0) [0|1] ""  GW
 SG_ HCU_12VSysErr_3 : 102|1@0+ (1,0) [0|1] ""  GW
 SG_ HCU_RdyLmpSts : 101|1@0+ (1,0) [0|1] ""  GW,ECM
 SG_ HCU_EnrgFlowInd_P2 : 87|5@0+ (1,0) [0|31] ""  GW
 SG_ HCU_StrtMod : 114|2@0+ (1,0) [0|3] ""  GW
 SG_ HCU_ModSwtFail : 127|4@0+ (1,0) [0|15] ""  GW
 SG_ RollingCounter_HCU_PT7 : 123|4@0+ (1,0) [0|15] ""  GW
 SG_ HCU_ChrgSysLmpSts : 146|3@0+ (1,0) [0|7] ""  GW
 SG_ HCU_ChrgSysErr_1 : 159|1@0+ (1,0) [0|1] ""  GW
 SG_ HCU_ChrgSysErr_2 : 158|1@0+ (1,0) [0|1] ""  GW
 SG_ HCU_ChrgSysErr_3 : 157|1@0+ (1,0) [0|1] ""  GW
 SG_ HCU_ChrgSysErr_4 : 156|1@0+ (1,0) [0|1] ""  GW
 SG_ HCU_ChrgSysErr_5 : 155|1@0+ (1,0) [0|1] ""  GW
 SG_ HCU_ChrgSysErr_6 : 154|1@0+ (1,0) [0|1] ""  GW
 SG_ HCU_ChrgSysErr_7 : 153|1@0+ (1,0) [0|1] ""  GW
 SG_ HCU_ChrgSysErr_8 : 152|1@0+ (1,0) [0|1] ""  GW
 SG_ HCU_DrvModDisp : 175|4@0+ (1,0) [0|15] ""  GW
 SG_ Checksum_HCU_HP5 : 199|8@0+ (1,0) [0|255] ""  ECM
 SG_ HCU_MILSts : 212|1@0+ (1,0) [0|1] ""  ECM
 SG_ RadiatorFanReq : 223|8@0+ (0.3937,0) [0|100.395] "%"  ECM
 SG_ RollingCounter_HCU_HP5 : 251|4@0+ (1,0) [0|15] ""  ECM

BO_ 542 DCT_FD3: 64 DCT
 SG_ CheckSum_DCT5 : 71|8@0+ (1,0) [0|255] ""  GW,ESP
 SG_ CurrentGearValid : 82|1@0+ (1,0) [0|1] ""  GW,HCU,ESP,ECM
 SG_ SHIFT_IN_PROGRESS : 81|1@0+ (1,0) [0|1] ""  GW,HCU,ESP,ECM
 SG_ TargetGearValid : 80|1@0+ (1,0) [0|1] ""  GW,HCU,ESP
 SG_ TCU_APS_Available : 92|1@0+ (1,0) [0|1] ""  GW,ESP
 SG_ TCU_ESP_DriverIntervention : 72|1@0+ (1,0) [0|1] ""  ESP
 SG_ TARGET_GEAR : 91|4@0+ (1,0) [0|15] ""  GW,HCU,ESP
 SG_ ShiftInPrgValid : 95|1@0+ (1,0) [0|1] ""  GW,HCU,ESP,ECM
 SG_ DCT_OSS : 103|14@0+ (1,0) [0|10000] "RPM"  HCU
 SG_ CURRENT_GEAR : 119|4@0+ (1,0) [0|15] ""  GW,HCU,ESP,ECM
 SG_ TGS_LEVER : 115|4@0+ (1,0) [0|15] ""  GW,HCU,ESP,ECM,EPS
 SG_ TRANS_Warning_LAMP : 127|1@0+ (1,0) [0|1] ""  ECM
 SG_ ShiftLeverPosn_SBWM : 126|3@0+ (1,0) [0|7] ""  GW
 SG_ RollingCounter_DCT5 : 123|4@0+ (1,0) [0|15] ""  GW,ESP
 SG_ CheckSumDCT17 : 135|8@0+ (1,0) [0|255] "" Vector__XXX
 SG_ DCT_SlipStrtSts : 189|2@0+ (1,0) [0|3] ""  HCU
 SG_ TCU_DrivingMode : 159|4@0+ (1,0) [0|15] ""  HCU
 SG_ TCU_EngSpdReq : 143|12@0+ (2,0) [0|6300] "RPM"  HCU
 SG_ TCU_TgtGearHybMode : 147|4@0+ (1,0) [0|15] ""  HCU
 SG_ DCT_TgtGearEleMode : 155|4@0+ (1,0) [0|15] ""  HCU
 SG_ RollingCounterDCT17 : 187|4@0+ (1,0) [0|15] "" Vector__XXX

BO_ 566 DCT_FD4: 64 DCT
 SG_ CheckSum_DCT7 : 71|8@0+ (1,0) [0|255] ""  GW
 SG_ Oil_CoolerReq : 79|4@0+ (1,0) [0|15] ""  ECM
 SG_ TRANS_OIL_TEMP : 87|8@0+ (1,-40) [-40|214] "℃"  HCU
 SG_ DCT_PrsBrk_Warn : 95|2@0+ (1,0) [0|3] ""  GW
 SG_ DCT_ShftNotAlwd_Warn : 93|2@0+ (1,0) [0|3] ""  GW
 SG_ DCT_ShftRecom_M : 91|2@0+ (1,0) [0|3] ""  GW
 SG_ DrvWarnMsg : 103|3@0+ (1,0) [0|7] ""  GW
 SG_ DrvFaiMsg : 100|4@0+ (1,0) [0|15] ""  GW
 SG_ DrvModDisp : 111|3@0+ (1,0) [0|7] ""  GW
 SG_ DrvModDispSts : 108|2@0+ (1,0) [0|3] ""  GW
 SG_ DrvAutoGearDisp : 127|4@0+ (1,0) [0|15] ""  GW
 SG_ DrvGearDispSts : 119|2@0+ (1,0) [0|3] ""  GW
 SG_ CoolFanReq_DCT7 : 116|4@0+ (1,0) [0|15] ""  ECM
 SG_ RollingCounter_DCT7 : 123|4@0+ (1,0) [0|15] ""  GW
 SG_ CheckSum_DCT18 : 135|8@0+ (1,0) [0|255] "" Vector__XXX
 SG_ DCT_MaxVehSpd : 143|8@0+ (1,0) [0|255] "kph"  HCU
 SG_ DCT_MinVehSpd : 151|8@0+ (1,0) [0|255] "kph"  HCU
 SG_ DCT_OvrspdFlag : 153|2@0+ (1,0) [0|3] ""  HCU
 SG_ DCT_MaxAllwSpd : 175|12@0+ (2,0) [0|6300] "RPM"  HCU
 SG_ RollingCounter_DCT18 : 187|4@0+ (1,0) [0|15] "" Vector__XXX
 SG_ FreshnessValue_DCT_FD4 : 455|16@0+ (1,0) [0|65535] ""  GW
 SG_ MAC_Check_DCT_FD4 : 471|48@0+ (1,0) [0|281474976710655] ""  GW

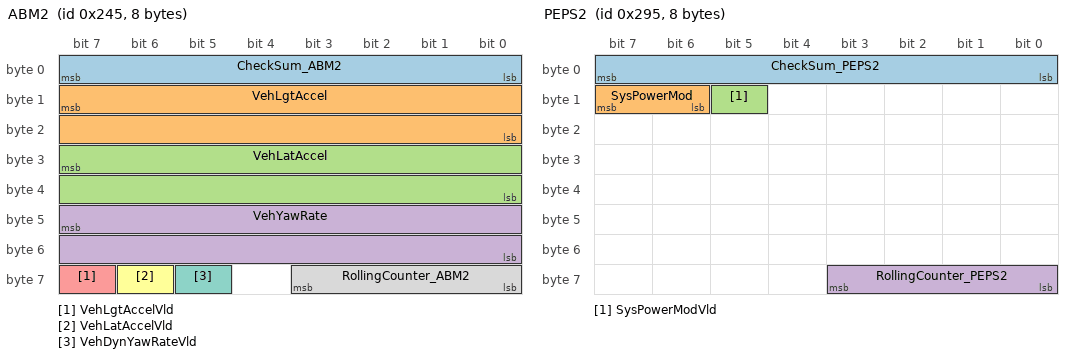
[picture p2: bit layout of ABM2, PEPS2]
BO_ 581 ABM2: 8 GW
 SG_ CheckSum_ABM2 : 7|8@0+ (1,0) [0|255] ""  ESP,Ibooster
 SG_ VehLgtAccel : 15|16@0+ (0.00098,-21.592) [-21.592|21.592] "m/s^2"  HCU,DCT,ESP,Ibooster,EDC
 SG_ VehLatAccel : 31|16@0+ (0.00098,-21.592) [-21.592|21.592] "m/s^2"  HCU,DCT,ESP,Ibooster,EDC
 SG_ VehYawRate : 47|16@0+ (0.00024,-2.093) [-2.093|2.093] "rad/s"  HCU,ESP,Ibooster,EPS
 SG_ VehLgtAccelVld : 63|1@0+ (1,0) [0|1] ""  HCU,DCT,ESP,Ibooster,EDC
 SG_ VehLatAccelVld : 62|1@0+ (1,0) [0|1] ""  HCU,DCT,ESP,Ibooster,EDC
 SG_ VehDynYawRateVld : 61|1@0+ (1,0) [0|1] ""  HCU,ESP,Ibooster,EPS
 SG_ RollingCounter_ABM2 : 59|4@0+ (1,0) [0|15] ""  ESP,Ibooster

BO_ 639 IP2: 16 GW
 SG_ CheckSum_IP2 : 7|8@0+ (1,0) [0|255] ""  DCT,ESP,Ibooster
 SG_ IP_VehTotDistance : 15|24@0+ (0.1,0) [0|999999.9] "Km"  DCT,ESP,ECM,Ibooster,EDC,EPS
 SG_ IP_FuelLvlInfo : 39|8@0+ (1,0) [0|200] "L"  ECM
 SG_ IP_VehTotDistanceValid : 46|1@0+ (1,0) [0|1] ""  ESP,ECM,Ibooster,EDC,EPS
 SG_ IP_VehSpdUnit : 53|1@0+ (1,0) [0|1] ""  HCU,DCT,ECM
 SG_ IP_VINcompr : 63|1@0+ (1,0) [0|1] ""  ECM
 SG_ RollingCounter_IP2 : 59|4@0+ (1,0) [0|15] ""  DCT,ESP,Ibooster

BO_ 659 IP1: 8 GW
 SG_ IP_FuelMainTankR : 17|10@0+ (1,0) [10|1000] "Ohm"  ECM
 SG_ IP_FuelAuxTankR : 39|10@0+ (1,0) [10|1000] "Ohm"  ECM

BO_ 661 PEPS2: 8 GW
 SG_ CheckSum_PEPS2 : 7|8@0+ (1,0) [0|255] ""  DCT
 SG_ SysPowerMod : 15|2@0+ (1,0) [0|3] ""  HCU,DCT
 SG_ SysPowerModVld : 13|1@0+ (1,0) [0|1] ""  HCU,DCT
 SG_ RollingCounter_PEPS2 : 59|4@0+ (1,0) [0|15] ""  DCT

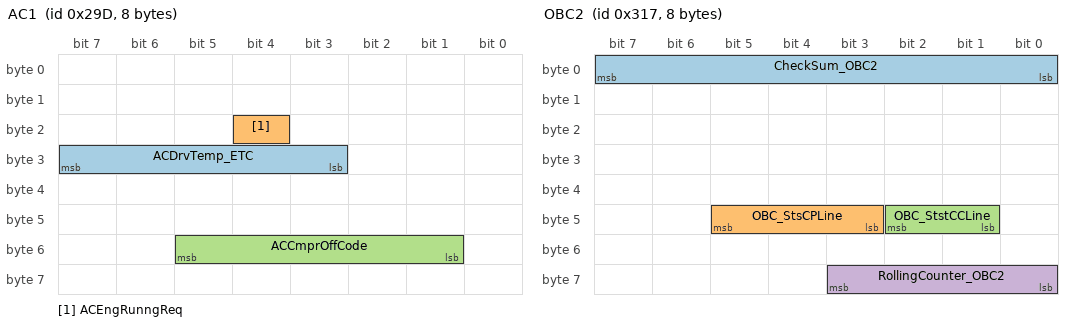
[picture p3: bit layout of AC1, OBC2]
BO_ 669 AC1: 8 GW
 SG_ ACDrvTemp_ETC : 31|5@0+ (1,0) [0|17] ""  ECM
 SG_ ACEngRunngReq : 20|1@0+ (1,0) [0|1] ""  HCU
 SG_ ACCmprOffCode : 53|5@0+ (1,0) [0|31] ""  HCU

BO_ 680 EEM1: 8 GW
 SG_ TranPMode_Sts : 7|1@0+ (1,0) [0|1] ""  ECM

BO_ 699 GW_FD1: 64 GW
 SG_ U_BATT : 71|14@0+ (0.0009765625,3) [3|18] "V"  HCU
 SG_ I_RANGE : 73|2@0+ (1,0) [0|3] ""  HCU
 SG_ I_BATT : 87|16@0+ (1,-32768) [-200|200] "A"  HCU
 SG_ T_BATT : 103|8@0+ (1,-40) [-40|105] "°C"  HCU
 SG_ IBATT_QUIESCENT : 111|8@0+ (0.00390625,0) [0|0.984375] "A"  HCU
 SG_ Status_Current : 119|2@0+ (1,0) [0|3] ""  HCU
 SG_ Status_Voltage : 117|2@0+ (1,0) [0|3] ""  HCU
 SG_ Status_Temp : 115|2@0+ (1,0) [0|3] ""  HCU
 SG_ ERROR_Calib : 113|1@0+ (1,0) [0|1] ""  HCU
 SG_ ERROR_IDENT : 112|1@0+ (1,0) [0|1] ""  HCU
 SG_ Resp_Error : 127|1@0+ (1,0) [0|1] ""  HCU
 SG_ FLAG_INCONSISTENCY : 126|1@0+ (1,0) [0|1] ""  HCU
 SG_ SOC : 135|8@0+ (1,0) [0|100] "%"  HCU,DCT
 SG_ SOH_SUL : 143|8@0+ (1,0) [0|100] "%"  HCU
 SG_ SOFV_StopEnable : 151|8@0+ (0.0625,0) [0|15.875] "V"  HCU
 SG_ SOFV_Restart : 159|8@0+ (0.0625,0) [0|15.875] "V"  HCU
 SG_ SOH_LAM : 167|8@0+ (0.5,0) [0|127] "Ah"  HCU
 SG_ SOH_COR : 175|8@0+ (0.0625,0) [0|15.875] "V"  HCU
 SG_ SOC_STATE : 183|2@0+ (1,0) [0|3] ""  HCU
 SG_ SOH_SUL_STATE : 181|2@0+ (1,0) [0|3] ""  HCU
 SG_ SOFV_StopEnable_STATE : 179|2@0+ (1,0) [0|3] ""  HCU
 SG_ SOFV_Restart_STATE : 177|2@0+ (1,0) [0|3] ""  HCU
 SG_ SOH_LAM_STATE : 191|2@0+ (1,0) [0|3] ""  HCU
 SG_ SOH_COR_STATE : 189|2@0+ (1,0) [0|3] ""  HCU
 SG_ Q_Charge : 207|16@0+ (0.125,0) [0|8191.75] "Ah"  HCU
 SG_ Q_Discharge : 223|16@0+ (0.125,0) [0|8191.75] "Ah"  HCU

BO_ 707 HUT_FD1: 64 GW
 SG_ HUT_ESPFuncOffSwtSts : 98|1@0+ (1,0) [0|1] ""  ESP
 SG_ DSTSwtReq : 112|1@0+ (1,0) [0|1] ""  ESP
 SG_ EPSSteerModSwtReq : 114|2@0+ (1,0) [0|3] ""  EPS
 SG_ HUT_BattSOCLimSaveMod : 119|5@0+ (1,0) [0|31] ""  HCU

BO_ 708 BMS35: 8 GW
 SG_ BMS_BattSOC : 15|10@0+ (0.1,0) [0|100] "%"  DCT,ECM

BO_ 729 EDC1: 8 EDC
 SG_ CurrDamprMode : 15|3@0+ (1,0) [0|7] ""  GW
 SG_ WarnLmpReq : 12|1@0+ (1,0) [0|1] ""  GW

BO_ 760 AC6: 8 GW
 SG_ ACCoolFanReq : 46|7@0+ (1,0) [0|100] "%"  ECM

BO_ 764 HCU_FD5: 64 HCU
 SG_ Checksum_HCU_PT4 : 71|8@0+ (1,0) [0|255] ""  DCT
 SG_ P2M_MotorStatorActTemp : 79|8@0+ (1,-40) [-40|213] "°C"  DCT
 SG_ P4M_MotorOverSpdSts : 96|1@0+ (1,0) [0|1] ""  DCT
 SG_ HCU_EnerSavePowerMod : 93|2@0+ (1,0) [0|3] ""  GW
 SG_ HCU_SOCLow_Indcn : 89|1@0+ (1,0) [0|1] ""  GW
 SG_ HCU_RemoveChrgLine_Indcn : 88|1@0+ (1,0) [0|1] ""  GW
 SG_ HCU_Shift_P_Indcn : 100|1@0+ (1,0) [0|1] ""  GW
 SG_ HCU_ConnectChrgLine_Indcn : 99|1@0+ (1,0) [0|1] ""  GW
 SG_ ImdtlyChrgSts : 98|1@0+ (1,0) [0|1] ""  GW
 SG_ HCU_EgyRecFB : 111|2@0+ (1,0) [0|3] ""  GW
 SG_ HCU_ACStsReq : 114|2@0+ (1,0) [0|3] ""  GW
 SG_ HCU_RefuReq : 87|3@0+ (1,0) [0|7] ""  GW,ECM
 SG_ HCU_OilTankCoverSts : 109|1@0+ (1,0) [0|1] ""  GW,ECM
 SG_ HCU_InhbChrgInfo : 108|1@0+ (1,0) [0|1] ""  GW
 SG_ HCU_RefuBtnSts : 112|1@0+ (1,0) [0|1] "" Vector__XXX
 SG_ HCU_EACPwrAld : 107|9@0+ (0.02,0) [0|8] "Kw"  GW
 SG_ RollingCounter_HCU_PT4 : 123|4@0+ (1,0) [0|15] ""  DCT
 SG_ HCU_AGSPosnReq : 271|7@0+ (1,0) [0|100] "%"  ECM

BO_ 769 ECM_FD3: 64 ECM
 SG_ CheckSum_ECM3 : 71|8@0+ (1,0) [0|255] ""  GW,HCU,DCT,ESP,Ibooster
 SG_ BaroPressure : 79|8@0+ (0.59,0) [0|149.86] "kPa"  GW,HCU,DCT,ESP
 SG_ EngCoolantTemp : 95|8@0+ (0.75,-48) [-48|143.25] "°C"  GW,HCU,DCT,ESP,Ibooster
 SG_ IntakeAirTemp : 103|8@0+ (0.75,-48) [-48|142.5] "°C"  HCU
 SG_ GPF_Warning : 111|2@0+ (1,0) [0|3] ""  GW
 SG_ EngClntTempWarn : 104|1@0+ (1,0) [0|1] ""  GW,HCU
 SG_ EngClntTempVldty : 119|2@0+ (1,0) [0|2] ""  GW,HCU,DCT,ESP,Ibooster
 SG_ DrivingCycle : 117|1@0+ (1,0) [0|1] ""  GW,HCU,DCT,ESP,Ibooster
 SG_ WarmUpCycle : 116|1@0+ (1,0) [0|1] ""  GW,HCU,DCT,ESP,Ibooster
 SG_ GPF_ActvRgn_Ena : 114|1@0+ (1,0) [0|1] "" Vector__XXX
 SG_ ECM_ClearPDTC : 112|1@0+ (1,0) [0|1] ""  GW,HCU,DCT,ESP,Ibooster
 SG_ GeneralDenominator : 127|1@0+ (1,0) [0|1] ""  GW,HCU,DCT,ESP,Ibooster
 SG_ IgnitionCycle : 126|1@0+ (1,0) [0|1] ""  GW,HCU,DCT,ESP,Ibooster
 SG_ ECM_FreezeIUPR : 124|1@0+ (1,0) [0|1] ""  GW,HCU,DCT,ESP,Ibooster
 SG_ AGS_Failure : 113|1@0+ (1,0) [0|1] ""  GW
 SG_ RollingCounter_ECM3 : 123|4@0+ (1,0) [0|15] ""  GW,HCU,DCT,ESP,Ibooster
 SG_ CheckSum_ECM11 : 135|8@0+ (1,0) [0|255] ""  GW,HCU,ESP,Ibooster
 SG_ EngSpd_ForIP : 175|16@0+ (0.125,0) [0|8191.875] "rpm"  GW
 SG_ CoolFanDutyRatio : 143|7@0+ (1,0) [0|100] "%"  GW
 SG_ GPF_PasRgn_Ena : 191|2@0+ (1,0) [0|3] ""  HCU
 SG_ AbsltthrtlPosn : 151|8@0+ (0.3922,0) [0|100] "%"  GW,HCU,DCT,ESP,Ibooster
 SG_ MaxAvailEngTrq : 159|8@0+ (0.3922,0) [0|100] "%"  GW,HCU,DCT,ESP,Ibooster
 SG_ CoolerSts : 167|7@0+ (1,0) [0|100] "%"  DCT
 SG_ EWP_Err : 160|1@0+ (1,0) [1|1] ""  GW
 SG_ RollingCounter_ECM11 : 187|4@0+ (1,0) [0|15] ""  GW,HCU,ESP,Ibooster
 SG_ CheckSum_ECM_PT6 : 199|8@0+ (1,0) [0|255] ""  HCU
 SG_ PressReliProgs : 215|7@0+ (1,0) [0|100] "%"  GW,HCU
 SG_ FTIVFault : 208|1@0+ (1,0) [0|1] ""  GW,HCU
 SG_ FanErrSts : 234|2@0+ (1,0) [0|3] ""  HCU
 SG_ FuelTankCapWarning : 242|2@0+ (1,0) [0|3] ""  GW
 SG_ RollingCounter_ECM_PT6 : 251|4@0+ (1,0) [0|15] ""  HCU

BO_ 791 OBC2: 8 GW
 SG_ CheckSum_OBC2 : 7|8@0+ (1,0) [0|255] ""  DCT
 SG_ OBC_StsCPLine : 45|3@0+ (1,0) [0|7] ""  DCT
 SG_ OBC_StstCCLine : 42|2@0+ (1,0) [0|3] ""  DCT
 SG_ RollingCounter_OBC2 : 59|4@0+ (1,0) [0|15] ""  DCT

BO_ 793 BCM1: 16 GW
 SG_ DrvDoorSts : 22|1@0+ (1,0) [0|1] ""  HCU,DCT,ESP

BO_ 837 BCM3: 16 GW
 SG_ DoorLockSts : 13|2@0+ (1,0) [0|3] ""  HCU
 SG_ VehicleSoakTime : 31|12@0+ (1,0) [0|1000] "Min"  ESP

BO_ 849 ABM1: 16 GW
 SG_ CheckSum_ABM1 : 7|8@0+ (1,0) [0|255] ""  ESP,ECM
 SG_ DrvSBR : 11|1@0+ (1,0) [0|1] ""  HCU,ESP
 SG_ CrashOutputSts : 23|8@0+ (1,0) [0|18] ""  HCU,DCT,ESP,ECM
 SG_ RollingCounter_ABM1 : 59|4@0+ (1,0) [0|15] ""  ESP,ECM

BO_ 865 HCU_FD6: 64 HCU
 SG_ P2M_DFC : 7|8@0+ (1,0) [0|255] ""  GW
 SG_ P2M_MotorStatorActTemp : 15|8@0+ (1,-40) [-40|213] "°C"  GW
 SG_ P2M_InverterActTemp : 23|8@0+ (1,-40) [-40|213] "°C"  GW
 SG_ P2M_CoolantTemp : 31|8@0+ (1,-40) [-40|213] "°C"  GW
 SG_ P2M_ResOffsetActSts : 39|2@0+ (1,0) [0|3] ""  GW
 SG_ P2M_InvActSts : 37|4@0+ (1,0) [0|15] ""  GW
 SG_ P2M_ResOffset_Calib : 33|2@0+ (1,0) [0|3] ""  GW
 SG_ P2M_ActvDchrgSts : 47|3@0+ (1,0) [0|7] ""  GW
 SG_ P2M_ErrCagy : 44|5@0+ (1,0) [0|31] ""  GW
 SG_ P2M_ActEffi : 55|7@0+ (1,0) [0|100] "%"  GW
 SG_ P2M_ASCSts : 63|2@0+ (1,0) [0|3] ""  GW
 SG_ P2M_InvPlsOffSts : 61|2@0+ (1,0) [0|3] ""  GW
 SG_ P2M_ActvdampSts : 48|1@0+ (1,0) [0|1] ""  GW
 SG_ P2M_MILSts : 59|1@0+ (1,0) [0|1] ""  GW
 SG_ P2M_PosTrqAvailMax : 71|13@0+ (0.1,0) [0|819.1] "Nm"  GW
 SG_ P2M_NegTrqAvailMin : 87|13@0+ (0.1,-819) [-819|0] "Nm"  GW
 SG_ P2M_NegTrqAvailMin_2s : 103|13@0+ (0.1,-819) [-819|0] "Nm"  GW
 SG_ P2M_PosTrqAvailMax_2s : 119|13@0+ (0.1,0) [0|819.1] "Nm"  GW
 SG_ P4M_PosTrqAvailMax_2s : 135|13@0+ (0.1,0) [0|819.1] "Nm"  GW
 SG_ P4M_NegTrqAvailMin_2s : 151|13@0+ (0.1,-819) [-819|0] "Nm"  GW
 SG_ P4M_NegTrqAvailMin_10s : 167|13@0+ (0.1,-819) [-819|0] "Nm"  GW
 SG_ P4M_NegTrqAvailMin : 183|13@0+ (0.1,-819) [-819|0] "Nm"  GW
 SG_ P4M_MotorActTemp : 199|8@0+ (1,-40) [-40|213] "°C"  GW
 SG_ P4M_InvActTemp : 207|8@0+ (1,-40) [-40|213] "°C"  GW
 SG_ P4M_InletCoolantTemp : 215|8@0+ (1,-40) [-40|213] "°C"  GW
 SG_ P4M_ResOffsetActSts : 223|2@0+ (1,0) [0|3] ""  GW
 SG_ P4M_SPOTest : 221|2@0+ (1,0) [0|3] ""  GW
 SG_ P4M_MotorOverSpdSts : 219|1@0+ (1,0) [0|1] ""  GW
 SG_ HCU_HVILSts : 218|2@0+ (1,0) [0|3] ""  GW
 SG_ HCU_BMSSleepCmd : 216|1@0+ (1,0) [0|1] ""  GW
 SG_ HCU_InvStsReq_P2M : 247|4@0+ (1,0) [0|15] ""  GW
 SG_ HCU_P2MTrqReq : 231|14@0+ (0.1,-819) [-819|819.1] "Nm"  GW
 SG_ HCU_P2MActHvDcCurr_RM : 263|16@0+ (0.1,-1000) [-1000|1000] "A"  GW
 SG_ HCU_P2MActHvDcVolt_RM : 279|16@0+ (0.1,0) [0|6000] "V"  GW
 SG_ HCU_DTCNumber1 : 293|9@0+ (1,0) [0|511] ""  GW
 SG_ HCU_DTCNumber2 : 300|9@0+ (1,0) [0|511] ""  GW
 SG_ HCU_MotorAmount_RM : 335|8@0+ (1,0) [1|253] ""  GW

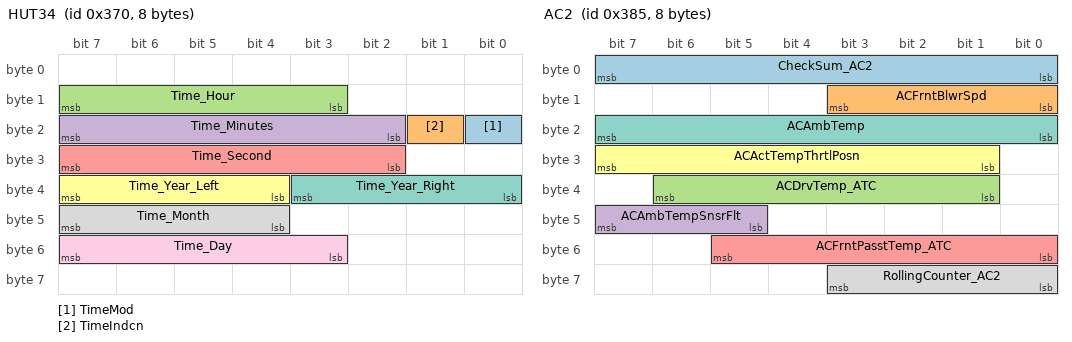
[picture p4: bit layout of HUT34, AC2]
BO_ 880 HUT34: 8 GW
 SG_ TimeMod : 16|1@0+ (1,0) [0|1] ""  DCT,ESP,ECM,Ibooster,EDC
 SG_ TimeIndcn : 17|1@0+ (1,0) [0|1] ""  DCT,ESP,ECM,Ibooster,EDC
 SG_ Time_Hour : 15|5@0+ (1,0) [0|31] ""  DCT,ESP,ECM,Ibooster,EDC,EPS
 SG_ Time_Minutes : 23|6@0+ (1,0) [0|63] ""  DCT,ESP,ECM,Ibooster,EDC,EPS
 SG_ Time_Second : 31|6@0+ (1,0) [0|63] ""  DCT,ESP,ECM,Ibooster,EDC
 SG_ Time_Year_Left : 39|4@0+ (1,0) [0|15] ""  DCT,ESP,ECM,Ibooster,EDC,EPS
 SG_ Time_Year_Right : 35|4@0+ (1,0) [0|15] ""  DCT,ESP,ECM,Ibooster,EDC,EPS
 SG_ Time_Month : 47|4@0+ (1,0) [0|15] ""  DCT,ESP,ECM,Ibooster,EDC,EPS
 SG_ Time_Day : 55|5@0+ (1,0) [0|31] ""  DCT,ESP,ECM,Ibooster,EDC,EPS

BO_ 901 AC2: 8 GW
 SG_ CheckSum_AC2 : 7|8@0+ (1,0) [0|255] ""  ESP,ECM,Ibooster
 SG_ ACFrntBlwrSpd : 11|4@0+ (1,0) [0|15] ""  ECM
 SG_ ACDrvTemp_ATC : 38|6@0+ (0.5,16) [16|32] "°C"  ECM
 SG_ ACAmbTempSnsrFlt : 47|3@0+ (1,0) [0|7] ""  ECM
 SG_ ACFrntPasstTemp_ATC : 53|6@0+ (0.5,16) [16|32] "°C"  ECM
 SG_ ACActTempThrtlPosn : 31|7@0+ (1,0) [0|100] "%"  ECM
 SG_ ACAmbTemp : 23|8@0+ (0.5,-40) [-40|86.5] "°C"  DCT,ESP,ECM,Ibooster
 SG_ RollingCounter_AC2 : 59|4@0+ (1,0) [0|15] ""  ESP,ECM,Ibooster

BO_ 949 ECM19: 8 ECM
 SG_ ECM_VIN : 7|64@0+ (1,0) [0|1.84467440737096E+019] ""  GW

BO_ 951 ECM20: 8 ECM
 SG_ ECM_VehDstBackup : 7|24@0+ (0.1,0) [0|999999.9] "Km"  GW
 SG_ EngStrtEndCounter : 31|16@0+ (1,0) [0|65535] "s"  DCT

BO_ 961 ECM21: 8 ECM
 SG_ ECMIntErr : 7|64@0+ (1,0) [0|1.84467440737096E+019] "" Vector__XXX

BO_ 968 ECM22: 8 ECM
 SG_ CloudMdlReqHiPre : 7|64@0+ (1,0) [0|1.84467440737096E+019] "" Vector__XXX

BO_ 971 ECM23: 8 ECM
 SG_ CloudMdlReqRot : 7|64@0+ (1,0) [0|1.84467440737096E+019] "" Vector__XXX

BO_ 1888 DiagFuncReq: 8 Tester
 SG_ DiagFuncReq : 7|64@0+ (1,0) [0|1.84467440737096E+019] ""  GW,HCU,ECM,ESP,DCT,EPS,Ibooster,EDC

BO_ 2015 DiagFuncEOBDReqFT: 8 Tester
 SG_ DiagFuncEOBDReqFT : 7|64@0+ (1,0) [0|1.84467440737096E+019] ""  GW,HCU,ECM,ESP,DCT,Ibooster

BO_ 1889 GW_Phy_Req: 8 Tester
 SG_ GW_Phy_Req : 7|64@0+ (1,0) [0|1.84467440737096E+019] ""  GW

BO_ 2019 HCU_Phy_Req_EOBD: 8 Tester
 SG_ HCU_Phy_Req_EOBD : 7|64@0+ (1,0) [0|1.84467440737096E+019] ""  GW,HCU

BO_ 1930 HCU_Phy_Req: 8 Tester
 SG_ HCU_Phy_Req : 7|64@0+ (1,0) [0|1.84467440737096E+019] ""  GW,HCU

BO_ 2016 ECM_Phy_Req: 8 Tester
 SG_ ECM_Phy_Req : 7|64@0+ (1,0) [0|1.84467440737096E+019] ""  GW,ECM

BO_ 1922 ESP_Phy_Req: 8 Tester
 SG_ ESP_Phy_Req : 7|64@0+ (1,0) [0|1.84467440737096E+019] ""  GW,ESP

BO_ 2021 ESP_Phy_Req_EOBD: 8 Tester
 SG_ ESP_Phy_Req_EOBD : 7|64@0+ (1,0) [0|1.84467440737096E+019] ""  GW,ESP

BO_ 2017 DCT_Phy_Req: 8 Tester
 SG_ DCT_Phy_Req : 7|64@0+ (1,0) [0|1.84467440737096E+019] ""  GW,DCT

BO_ 1825 EPS_Phy_Req: 8 Tester
 SG_ EPS_Phy_Req : 7|64@0+ (1,0) [0|1.84467440737096E+019] ""  GW,EPS

BO_ 1765 EDC_Phy_Req: 8 Tester
 SG_ EDC_Phy_Req : 7|64@0+ (1,0) [0|1.84467440737096E+019] ""  GW,EDC

BO_ 1728 IB_Phy_Req: 8 Tester
 SG_ IB_Phy_Req : 7|64@0+ (1,0) [0|1.84467440737096E+019] ""  GW,Ibooster

BO_ 2022 IB_Phy_Req_EOBD: 8 Tester
 SG_ IB_Phy_Req_EOBD : 7|64@0+ (1,0) [0|1.84467440737096E+019] ""  GW,Ibooster

BO_ 1953 GW_Phy_Resp: 8 GW
 SG_ GW_Phy_Resp : 7|64@0+ (1,0) [0|1.84467440737096E+019] ""  Tester

BO_ 2024 ECM_Phy_Resp: 8 ECM
 SG_ ECM_Phy_Resp : 7|64@0+ (1,0) [0|1.84467440737096E+019] ""  GW,Tester

BO_ 1986 ESP_Phy_Resp: 8 ESP
 SG_ ESP_Phy_Resp : 7|64@0+ (1,0) [0|1.84467440737096E+019] ""  GW,Tester

BO_ 2029 ESP_Phy_Resp_EOBD: 8 ESP
 SG_ ESP_Phy_Resp_EOBD : 7|64@0+ (1,0) [0|1.84467440737096E+019] ""  GW,Tester

BO_ 2025 DCT_Phy_Resp: 8 DCT
 SG_ DCT_Phy_Resp : 7|64@0+ (1,0) [0|1.84467440737096E+019] ""  GW,Tester

BO_ 1833 EPS_Phy_Resp: 8 EPS
 SG_ EPS_Phy_Resp : 7|64@0+ (1,0) [0|1.84467440737096E+019] ""  GW,Tester

BO_ 1729 IB_Phy_Resp: 8 Ibooster
 SG_ IB_Phy_Resp : 7|64@0+ (1,0) [0|1.84467440737096E+019] ""  GW,Tester

BO_ 2030 IB_Phy_Resp_EOBD: 8 Ibooster
 SG_ IB_Phy_Resp_EOBD : 7|64@0+ (1,0) [0|1.84467440737096E+019] ""  GW,Tester

BO_ 1994 HCU_Phy_Resp: 8 HCU
 SG_ HCU_Phy_Resp : 7|64@0+ (1,0) [0|1.84467440737096E+019] ""  GW,Tester

BO_ 2027 HCU_Phy_Resp_EOBD: 8 HCU
 SG_ HCU_Phy_Resp_EOBD : 7|64@0+ (1,0) [0|1.84467440737096E+019] ""  GW,Tester

BO_ 1773 EDC_Phy_Resp: 8 EDC
 SG_ EDC_Phy_Resp : 7|64@0+ (1,0) [0|1.84467440737096E+019] ""  GW,Tester

CM_ SG_ 96 HCU_BrkPedalSts "C";
CM_ SG_ 96 HCU_AccelPedalPosn "C";
CM_ SG_ 96 HCU_AccelPedalPosnValid "C";
CM_ SG_ 96 HCU_NetTrq_TrsmClutch "C";
CM_ SG_ 96 HCU_TrqReq_TrsmClutch "C";
CM_ SG_ 96 HCU_TrqReqWoDCT_TrsmClutch "C";
CM_ SG_ 96 HCU_NetTrq_TrsmClutchValid "C";
CM_ SG_ 96 HCU_TrqReqWoDCT_TrsmClutchValid "C";
CM_ SG_ 96 HCU_PowertrainSts "A";
CM_ SG_ 161 CC_ACC_CRUISE_OFFSwt "A";
CM_ SG_ 161 CC_ACC_CANCEL_OFFSwt "A";
CM_ SG_ 161 CC_ACC_IncSetSpd_ResuSwt "A";
CM_ SG_ 161 CC_ACC_DecSetSpd_SetSwt "A";
CM_ SG_ 161 CC_ACCSwtErr "A";
CM_ SG_ 234 HCU_TrsmClutchStatusReq "A";
CM_ SG_ 234 HCU_EngStartReq "A";
CM_ SG_ 234 HCU_EngStopReq "QM(A)";
CM_ SG_ 234 HCU_StartStopTypReq "B";
CM_ SG_ 234 TrqReqSlowPath "C";
CM_ SG_ 234 TrqReqFastPath "C";
CM_ SG_ 234 HCU_K0ClutchStatusReq "A(A)";
CM_ SG_ 311 VehOdoInfoSts "B";
CM_ SG_ 311 VehOdoInfo "B";
CM_ SG_ 516 HCU_12VSysErrLmpSts "B";
CM_ SG_ 516 HCU_HybSysErrLmpSts "B（C)";
CM_ SG_ 639 IP_VehTotDistance "B";
CM_ SG_ 639 IP_VehTotDistanceValid "B";
CM_ SG_ 764 P4M_MotorOverSpdSts "C";
CM_ SG_ 764 HCU_RefuReq "/";
CM_ SG_ 764 HCU_OilTankCoverSts "/";
CM_ SG_ 764 HCU_InhbChrgInfo "/";
CM_ SG_ 764 HCU_RefuBtnSts "/";
CM_ SG_ 791 OBC_StsCPLine "A";
CM_ SG_ 791 OBC_StstCCLine "A";
CM_ SG_ 865 P2M_InvActSts "A";
CM_ SG_ 865 P2M_ASCSts "A";
CM_ SG_ 865 P2M_InvPlsOffSts "A";
CM_ SG_ 865 P4M_MotorOverSpdSts "C";
CM_ SG_ 865 HCU_InvStsReq_P2M "A";
CM_ SG_ 865 HCU_P2MTrqReq "C";
BA_DEF_  "Manufacturer" STRING ;
BA_DEF_  "DBName" STRING ;
BA_DEF_  "BusType" STRING ;
BA_DEF_  "GenEnvVarEndingDsp" STRING ;
BA_DEF_  "GenEnvVarEndingSnd" STRING ;
BA_DEF_  "GenEnvVarPrefix" STRING ;
BA_DEF_  "GenNWMApBusSleep" STRING ;
BA_DEF_  "GenNWMApCanNormal" STRING ;
BA_DEF_  "GenNWMApCanOff" STRING ;
BA_DEF_  "GenNWMApCanOn" STRING ;
BA_DEF_  "GenNWMApCanSleep" STRING ;
BA_DEF_  "GenNWMApCanWakeUp" STRING ;
BA_DEF_  "GenNWMGotoMode_Awake" STRING ;
BA_DEF_  "GenNWMGotoMode_BusSleep" STRING ;
BA_DEF_  "GenNWMTalkNM" STRING ;
BA_DEF_  "NmBaseAddress" HEX 1152 1279;
BA_DEF_ BU_  "NodeLayerModules" STRING ;
BA_DEF_ BU_  "NmCAN" INT 0 2;
BA_DEF_ BU_  "ILUsed" ENUM  "No","Yes";
BA_DEF_ BO_  "DiagState" ENUM  "No","Yes";
BA_DEF_ BO_  "GenMsgILSupport" ENUM  "No","Yes";
BA_DEF_ BO_  "GenMsgCycleTime" INT 0 65535;
BA_DEF_ BO_  "GenMsgMinAcceptLength" INT 0 8;
BA_DEF_ BO_  "GenMsgSendType" ENUM  "Cyclic","CyclicAndSpontanX","Event";
BA_DEF_ BO_  "CANFD_BRS" ENUM  "0","1";
BA_DEF_ BO_  "VFrameFormat" ENUM  "StandardCAN","ExtendedCAN","reserved","reserved","reserved","reserved","reserved","reserved","reserved","reserved","reserved","reserved","reserved","reserved","StandardCAN_FD","ExtendedCAN_FD";
BA_DEF_ SG_  "GenSigEnvVarType" ENUM  "undef","int","float";
BA_DEF_ SG_  "GenSigSendType" ENUM  "Cyclic","OnWrite","OnWriteWithRepetition","OnChange","OnChangeWithRepetition","IfActive","IfActiveWithRepetition","NoSigSendType","NotUsed","NotUsed","NotUsed","NotUsed","NotUsed";
BA_DEF_ SG_  "GenSigStartValue" FLOAT 0 1215752192;
BA_DEF_DEF_  "Manufacturer" "GWM";
BA_DEF_DEF_  "DBName" "V71P_for_PT_CANFD_V2_2_1";
BA_DEF_DEF_  "BusType" "";
BA_DEF_DEF_  "GenEnvVarEndingDsp" "_d";
BA_DEF_DEF_  "GenEnvVarEndingSnd" "_s";
BA_DEF_DEF_  "GenEnvVarPrefix" "c";
BA_DEF_DEF_  "GenNWMApBusSleep" "apBusSleep()";
BA_DEF_DEF_  "GenNWMApCanNormal" "apCanNormal()";
BA_DEF_DEF_  "GenNWMApCanOff" "apCanOff()";
BA_DEF_DEF_  "GenNWMApCanOn" "apCanOn()";
BA_DEF_DEF_  "GenNWMApCanSleep" "apCanSleep()";
BA_DEF_DEF_  "GenNWMApCanWakeUp" "apCanWakeUp()";
BA_DEF_DEF_  "GenNWMGotoMode_Awake" "GotoMode_Awake()";
BA_DEF_DEF_  "GenNWMGotoMode_BusSleep" "GotoMode_BusSleep()";
BA_DEF_DEF_  "GenNWMTalkNM" "TalkNM()";
BA_DEF_DEF_  "NmBaseAddress" 1152;
BA_DEF_DEF_  "NodeLayerModules" "CANoeILNLVector.dll";
BA_DEF_DEF_  "NmCAN" 1;
BA_DEF_DEF_  "ILUsed" "Yes";
BA_DEF_DEF_  "DiagState" "No";
BA_DEF_DEF_  "GenMsgILSupport" "Yes";
BA_DEF_DEF_  "GenMsgCycleTime" 10;
BA_DEF_DEF_  "GenMsgMinAcceptLength" 8;
BA_DEF_DEF_  "GenMsgSendType" "Cyclic";
BA_DEF_DEF_  "CANFD_BRS" "1";
BA_DEF_DEF_  "VFrameFormat" "StandardCAN";
BA_DEF_DEF_  "GenSigEnvVarType" "undef";
BA_DEF_DEF_  "GenSigSendType" "Cyclic";
BA_DEF_DEF_  "GenSigStartValue" 0;
BA_ "BusType" "CAN FD";
BA_ "GenMsgSendType" BO_ 87 2;
BA_ "GenMsgCycleTime" BO_ 87 0;
BA_ "VFrameFormat" BO_ 87 14;
BA_ "VFrameFormat" BO_ 96 14;
BA_ "VFrameFormat" BO_ 124 14;
BA_ "GenMsgSendType" BO_ 135 2;
BA_ "GenMsgCycleTime" BO_ 135 0;
BA_ "VFrameFormat" BO_ 135 14;
BA_ "VFrameFormat" BO_ 143 14;
BA_ "VFrameFormat" BO_ 150 14;
BA_ "VFrameFormat" BO_ 161 14;
BA_ "GenMsgSendType" BO_ 165 2;
BA_ "GenMsgCycleTime" BO_ 165 0;
BA_ "VFrameFormat" BO_ 165 14;
BA_ "VFrameFormat" BO_ 168 14;
BA_ "VFrameFormat" BO_ 189 14;
BA_ "VFrameFormat" BO_ 190 14;
BA_ "GenMsgCycleTime" BO_ 199 50;
BA_ "VFrameFormat" BO_ 199 14;
BA_ "VFrameFormat" BO_ 209 14;
BA_ "VFrameFormat" BO_ 234 14;
BA_ "GenMsgCycleTime" BO_ 259 20;
BA_ "VFrameFormat" BO_ 259 14;
BA_ "GenMsgSendType" BO_ 266 2;
BA_ "GenMsgCycleTime" BO_ 266 0;
BA_ "VFrameFormat" BO_ 266 14;
BA_ "GenMsgSendType" BO_ 267 2;
BA_ "GenMsgCycleTime" BO_ 267 0;
BA_ "VFrameFormat" BO_ 267 14;
BA_ "GenMsgSendType" BO_ 270 2;
BA_ "GenMsgCycleTime" BO_ 270 0;
BA_ "VFrameFormat" BO_ 270 14;
BA_ "GenMsgSendType" BO_ 271 2;
BA_ "GenMsgCycleTime" BO_ 271 0;
BA_ "VFrameFormat" BO_ 271 14;
BA_ "GenMsgCycleTime" BO_ 288 20;
BA_ "VFrameFormat" BO_ 288 14;
BA_ "GenMsgCycleTime" BO_ 299 20;
BA_ "VFrameFormat" BO_ 299 14;
BA_ "GenMsgCycleTime" BO_ 303 20;
BA_ "VFrameFormat" BO_ 303 14;
BA_ "GenMsgCycleTime" BO_ 311 20;
BA_ "VFrameFormat" BO_ 311 14;
BA_ "GenMsgCycleTime" BO_ 315 20;
BA_ "VFrameFormat" BO_ 315 14;
BA_ "GenMsgCycleTime" BO_ 317 20;
BA_ "VFrameFormat" BO_ 317 14;
BA_ "GenMsgCycleTime" BO_ 323 20;
BA_ "VFrameFormat" BO_ 323 14;
BA_ "GenMsgCycleTime" BO_ 327 20;
BA_ "VFrameFormat" BO_ 327 14;
BA_ "GenMsgCycleTime" BO_ 344 20;
BA_ "VFrameFormat" BO_ 344 14;
BA_ "GenMsgCycleTime" BO_ 347 20;
BA_ "VFrameFormat" BO_ 347 14;
BA_ "GenMsgCycleTime" BO_ 367 20;
BA_ "VFrameFormat" BO_ 367 14;
BA_ "GenMsgCycleTime" BO_ 395 20;
BA_ "VFrameFormat" BO_ 395 14;
BA_ "GenMsgCycleTime" BO_ 411 50;
BA_ "VFrameFormat" BO_ 411 14;
BA_ "GenMsgCycleTime" BO_ 516 50;
BA_ "VFrameFormat" BO_ 516 14;
BA_ "GenMsgCycleTime" BO_ 542 20;
BA_ "VFrameFormat" BO_ 542 14;
BA_ "GenMsgCycleTime" BO_ 566 50;
BA_ "VFrameFormat" BO_ 566 14;
BA_ "GenMsgCycleTime" BO_ 581 20;
BA_ "VFrameFormat" BO_ 581 14;
BA_ "GenMsgCycleTime" BO_ 639 50;
BA_ "VFrameFormat" BO_ 639 14;
BA_ "GenMsgCycleTime" BO_ 659 100;
BA_ "VFrameFormat" BO_ 659 14;
BA_ "GenMsgCycleTime" BO_ 661 50;
BA_ "VFrameFormat" BO_ 661 14;
BA_ "GenMsgCycleTime" BO_ 669 100;
BA_ "VFrameFormat" BO_ 669 14;
BA_ "GenMsgCycleTime" BO_ 680 100;
BA_ "VFrameFormat" BO_ 680 14;
BA_ "GenMsgCycleTime" BO_ 699 100;
BA_ "VFrameFormat" BO_ 699 14;
BA_ "GenMsgCycleTime" BO_ 707 100;
BA_ "VFrameFormat" BO_ 707 14;
BA_ "GenMsgCycleTime" BO_ 708 100;
BA_ "VFrameFormat" BO_ 708 14;
BA_ "GenMsgCycleTime" BO_ 729 100;
BA_ "VFrameFormat" BO_ 729 14;
BA_ "GenMsgCycleTime" BO_ 760 100;
BA_ "VFrameFormat" BO_ 760 14;
BA_ "GenMsgCycleTime" BO_ 764 100;
BA_ "VFrameFormat" BO_ 764 14;
BA_ "GenMsgCycleTime" BO_ 769 100;
BA_ "VFrameFormat" BO_ 769 14;
BA_ "GenMsgCycleTime" BO_ 791 200;
BA_ "VFrameFormat" BO_ 791 14;
BA_ "GenMsgCycleTime" BO_ 793 50;
BA_ "VFrameFormat" BO_ 793 14;
BA_ "GenMsgCycleTime" BO_ 837 50;
BA_ "VFrameFormat" BO_ 837 14;
BA_ "GenMsgSendType" BO_ 849 1;
BA_ "GenMsgCycleTime" BO_ 849 500;
BA_ "VFrameFormat" BO_ 849 14;
BA_ "GenMsgCycleTime" BO_ 865 500;
BA_ "VFrameFormat" BO_ 865 14;
BA_ "GenMsgCycleTime" BO_ 880 1000;
BA_ "VFrameFormat" BO_ 880 14;
BA_ "GenMsgCycleTime" BO_ 901 100;
BA_ "VFrameFormat" BO_ 901 14;
BA_ "GenMsgCycleTime" BO_ 949 1000;
BA_ "VFrameFormat" BO_ 949 14;
BA_ "GenMsgCycleTime" BO_ 951 1000;
BA_ "VFrameFormat" BO_ 951 14;
BA_ "GenMsgSendType" BO_ 961 2;
BA_ "GenMsgCycleTime" BO_ 961 0;
BA_ "VFrameFormat" BO_ 961 14;
BA_ "GenMsgCycleTime" BO_ 968 1000;
BA_ "VFrameFormat" BO_ 968 14;
BA_ "GenMsgCycleTime" BO_ 971 1000;
BA_ "VFrameFormat" BO_ 971 14;
BA_ "GenMsgSendType" BO_ 1888 2;
BA_ "GenMsgCycleTime" BO_ 1888 0;
BA_ "DiagState" BO_ 1888 1;
BA_ "GenMsgSendType" BO_ 2015 2;
BA_ "GenMsgCycleTime" BO_ 2015 0;
BA_ "DiagState" BO_ 2015 1;
BA_ "GenMsgSendType" BO_ 1889 2;
BA_ "GenMsgCycleTime" BO_ 1889 0;
BA_ "GenMsgSendType" BO_ 2019 2;
BA_ "GenMsgCycleTime" BO_ 2019 0;
BA_ "GenMsgSendType" BO_ 1930 2;
BA_ "GenMsgCycleTime" BO_ 1930 0;
BA_ "GenMsgSendType" BO_ 2016 2;
BA_ "GenMsgCycleTime" BO_ 2016 0;
BA_ "GenMsgSendType" BO_ 1922 2;
BA_ "GenMsgCycleTime" BO_ 1922 0;
BA_ "GenMsgSendType" BO_ 2021 2;
BA_ "GenMsgCycleTime" BO_ 2021 0;
BA_ "GenMsgSendType" BO_ 2017 2;
BA_ "GenMsgCycleTime" BO_ 2017 0;
BA_ "GenMsgSendType" BO_ 1825 2;
BA_ "GenMsgCycleTime" BO_ 1825 0;
BA_ "GenMsgSendType" BO_ 1765 2;
BA_ "GenMsgCycleTime" BO_ 1765 0;
BA_ "GenMsgSendType" BO_ 1728 2;
BA_ "GenMsgCycleTime" BO_ 1728 0;
BA_ "GenMsgSendType" BO_ 2022 2;
BA_ "GenMsgCycleTime" BO_ 2022 0;
BA_ "GenMsgSendType" BO_ 1953 2;
BA_ "GenMsgCycleTime" BO_ 1953 0;
BA_ "GenMsgSendType" BO_ 2024 2;
BA_ "GenMsgCycleTime" BO_ 2024 0;
BA_ "GenMsgSendType" BO_ 1986 2;
BA_ "GenMsgCycleTime" BO_ 1986 0;
BA_ "GenMsgSendType" BO_ 2029 2;
BA_ "GenMsgCycleTime" BO_ 2029 0;
BA_ "GenMsgSendType" BO_ 2025 2;
BA_ "GenMsgCycleTime" BO_ 2025 0;
BA_ "GenMsgSendType" BO_ 1833 2;
BA_ "GenMsgCycleTime" BO_ 1833 0;
BA_ "GenMsgSendType" BO_ 1729 2;
BA_ "GenMsgCycleTime" BO_ 1729 0;
BA_ "GenMsgSendType" BO_ 2030 2;
BA_ "GenMsgCycleTime" BO_ 2030 0;
BA_ "GenMsgSendType" BO_ 1994 2;
BA_ "GenMsgCycleTime" BO_ 1994 0;
BA_ "GenMsgSendType" BO_ 2027 2;
BA_ "GenMsgCycleTime" BO_ 2027 0;
BA_ "GenMsgSendType" BO_ 1773 2;
BA_ "GenMsgCycleTime" BO_ 1773 0;
BA_ "GenSigSendType" SG_ 87 PEPS_VehAuth2 10;
BA_ "GenSigStartValue" SG_ 96 HCU_AccelPedalPosn_DiagValid 1;
BA_ "GenSigStartValue" SG_ 96 ActWheelTrqDmd 1200;
BA_ "GenSigStartValue" SG_ 96 HCU_AccelPedalPosnValid 1;
BA_ "GenSigStartValue" SG_ 96 P4M_ActRotSpd 32766;
BA_ "GenSigStartValue" SG_ 96 MaxPsblWheelTrq 300;
BA_ "GenSigStartValue" SG_ 96 TotWheelTrq 1200;
BA_ "GenSigStartValue" SG_ 96 MinPsblWheelTrq 300;
BA_ "GenSigStartValue" SG_ 96 HCU_NetTrq_TrsmClutch 2000;
BA_ "GenSigStartValue" SG_ 96 HCU_TrqReq_TrsmClutch 2000;
BA_ "GenSigStartValue" SG_ 96 HCU_TrqReqWoDCT_TrsmClutch 2000;
BA_ "GenSigStartValue" SG_ 96 HCU_MaxTrqLimt_TrsmClutch 500;
BA_ "GenSigStartValue" SG_ 96 HCU_NetTrq_TrsmClutchValid 1;
BA_ "GenSigStartValue" SG_ 96 HCU_MaxEngTrqLimtValid 1;
BA_ "GenSigStartValue" SG_ 96 HCU_TrqReqWoDCT_TrsmClutchValid 1;
BA_ "GenSigStartValue" SG_ 96 HCU_TgtEngTrqValid 1;
BA_ "GenSigStartValue" SG_ 96 RegenWheelTrqActValid 1;
BA_ "GenSigStartValue" SG_ 96 AvailRgnTrqValid 1;
BA_ "GenSigStartValue" SG_ 96 HCU_P4M_ActTrq 16382;
BA_ "GenSigStartValue" SG_ 96 HCU_AccPedalPosnCorrdValid 1;
BA_ "GenSigStartValue" SG_ 124 TrqRedFastReq 65534;
BA_ "GenSigStartValue" SG_ 124 TrqRedSlowReq 65534;
BA_ "GenSigStartValue" SG_ 124 DCT_RaceLaunchAvail 3;
BA_ "GenSigStartValue" SG_ 124 DCT_RaceLaunchProhibit 1;
BA_ "GenSigStartValue" SG_ 124 RatAct 254;
BA_ "GenSigStartValue" SG_ 124 DCT_K0ClutchPredictTorque 2000;
BA_ "GenSigStartValue" SG_ 124 DCT_K1ClutchPredictTorque 2000;
BA_ "GenSigStartValue" SG_ 124 DCT_K2ClutchPredictTorque 2000;
BA_ "GenSigStartValue" SG_ 124 TCU_TgtTrsmRatio 254;
BA_ "GenSigStartValue" SG_ 124 DCT_TrqRatio 65534;
BA_ "GenSigSendType" SG_ 135 PEPS_VehAuth1 10;
BA_ "GenSigStartValue" SG_ 143 EngSpdVldty_PHEV 2;
BA_ "GenSigStartValue" SG_ 143 TrqRngValid 1;
BA_ "GenSigStartValue" SG_ 143 TgtCrsAccValid 1;
BA_ "GenSigStartValue" SG_ 143 IdleTrq_PIValid 1;
BA_ "GenSigStartValue" SG_ 143 RngAlwdTrqIntvntnValid 1;
BA_ "GenSigStartValue" SG_ 143 EngStatnryTrqRngValid 1;
BA_ "GenSigStartValue" SG_ 143 EngTrqCrankshaftLvlValid 1;
BA_ "GenSigStartValue" SG_ 143 EngTrqLimProtValid 1;
BA_ "GenSigStartValue" SG_ 143 EngTrqLossValid 1;
BA_ "GenSigStartValue" SG_ 143 TrqMinFastPathFCOValid 1;
BA_ "GenSigSendType" SG_ 165 VehStartReq 10;
BA_ "GenSigStartValue" SG_ 168 DCT_K0ClutchActTrq 2000;
BA_ "GenSigStartValue" SG_ 168 DCT_K1ClutchActTrq 2000;
BA_ "GenSigStartValue" SG_ 168 DCT_K2ClutchActTrq 2000;
BA_ "GenSigStartValue" SG_ 168 DCT_MinTrqLim_TrsmClutch 2000;
BA_ "GenSigStartValue" SG_ 168 DCT_K0ClutchMinTrqLim 2000;
BA_ "GenSigStartValue" SG_ 168 DCT_K0ClutchMaxTrqLim 2000;
BA_ "GenSigStartValue" SG_ 168 DCT_K0ClutchActStatus 7;
BA_ "GenSigStartValue" SG_ 168 TrqIncSlowReq_Ktr 4094;
BA_ "GenSigStartValue" SG_ 168 TrqIncFastReq_Ktr 4094;
BA_ "GenSigStartValue" SG_ 168 DCT_RvsGearSts 2;
BA_ "GenSigStartValue" SG_ 189 TgtRcprtnTrqReq 8192;
BA_ "GenSigStartValue" SG_ 199 DRV_RQ_SHFT 8;
BA_ "GenSigStartValue" SG_ 199 DrvReqShftInv 7;
BA_ "GenSigStartValue" SG_ 234 HCU_FastRedTrqLim_TrsmClutch 2000;
BA_ "GenSigStartValue" SG_ 234 HCU_MinTrqLim_TrsmClutch 2000;
BA_ "GenSigStartValue" SG_ 234 TrqAct_RA 2048;
BA_ "GenSigStartValue" SG_ 234 FastRedTrqLimValid 1;
BA_ "GenSigStartValue" SG_ 234 TrqAct_RAValid 1;
BA_ "GenSigStartValue" SG_ 234 HCU_MinEngTrqLimValid 1;
BA_ "GenSigStartValue" SG_ 234 HCU_P2MActTrq 4094;
BA_ "GenSigStartValue" SG_ 234 HCU_TrqLimMax_Norm 275;
BA_ "GenSigStartValue" SG_ 234 HCU_K0ClutchTrqReq 2000;
BA_ "GenSigStartValue" SG_ 234 TorqueLossValid 1;
BA_ "GenSigStartValue" SG_ 234 TorqueLoss 2048;
BA_ "GenSigStartValue" SG_ 259 TgtCrsVehSpdvalid 1;
BA_ "GenSigSendType" SG_ 266 TCU_Auth_1 10;
BA_ "GenSigSendType" SG_ 267 TCU_Auth_2 10;
BA_ "GenSigSendType" SG_ 270 TCUAuth_PEPS_1 10;
BA_ "GenSigSendType" SG_ 271 TCUAuth_PEPS_2 10;
BA_ "GenSigStartValue" SG_ 288 WssFLEdgesSumVld 1;
BA_ "GenSigStartValue" SG_ 288 WssFREdgesSumVld 1;
BA_ "GenSigStartValue" SG_ 288 WssRLEdgesSumVld 1;
BA_ "GenSigStartValue" SG_ 288 WssRREdgesSumVld 1;
BA_ "GenSigStartValue" SG_ 299 IFCTrqOvlCmdProtnValue 7169;
BA_ "GenSigStartValue" SG_ 299 IFCTrqOvlCmdReqValue 1023;
BA_ "GenSigStartValue" SG_ 303 HCU_VitlAccelPedalPosn_CrpValid 1;
BA_ "GenSigStartValue" SG_ 303 HCU_ECODrvHabit_Indcn 100;
BA_ "GenSigStartValue" SG_ 303 HCU_TotDrvReqPower 100;
BA_ "GenSigStartValue" SG_ 303 IdleSpdSetPointReq 2046;
BA_ "GenSigStartValue" SG_ 303 HCU_VirtAccelPedalPosn_FAValid 1;
BA_ "GenSigStartValue" SG_ 311 SwtOffCrsCtrl 1;
BA_ "GenSigStartValue" SG_ 311 SysOperatingMod_ESP 1;
BA_ "GenSigStartValue" SG_ 311 ESP_MasterCylBrkPressVld 1;
BA_ "GenSigStartValue" SG_ 311 EngTrqReq 65535;
BA_ "GenSigStartValue" SG_ 311 DrvTrqRedFastReq_FA 65535;
BA_ "GenSigStartValue" SG_ 311 DrvTrqRedSlowReq_FA 65535;
BA_ "GenSigStartValue" SG_ 311 ABSFailSts 1;
BA_ "GenSigStartValue" SG_ 311 VehOdoInfoSts 1;
BA_ "GenSigStartValue" SG_ 315 WssFLEdgesSumVld 1;
BA_ "GenSigStartValue" SG_ 315 WssFREdgesSumVld 1;
BA_ "GenSigStartValue" SG_ 315 WssRLEdgesSumVld 1;
BA_ "GenSigStartValue" SG_ 315 WssRREdgesSumVld 1;
BA_ "GenSigStartValue" SG_ 317 MEB_BrkgReqValue 200;
BA_ "GenSigStartValue" SG_ 323 Longctrl_ModSts 1;
BA_ "GenSigStartValue" SG_ 327 EPS_DSTCtrlSts 2;
BA_ "GenSigStartValue" SG_ 327 EPS_TrqSnsrSts 1;
BA_ "GenSigStartValue" SG_ 327 EPS_DrvInpTrqVal_HighReslolution 2047;
BA_ "GenSigStartValue" SG_ 344 HWP_AngCmdReqVal 7800;
BA_ "GenSigStartValue" SG_ 344 HWP_TrqOvlCmdProtnValue 7169;
BA_ "GenSigStartValue" SG_ 344 HWP_TrqOvlCmdReqValue 1023;
BA_ "GenSigStartValue" SG_ 344 HWP_WorkReqVld 1;
BA_ "GenSigStartValue" SG_ 344 HWP_TgtGearReqVld 1;
BA_ "GenSigStartValue" SG_ 344 HWP_Lgt_HCUTrqReqVld 1;
BA_ "GenSigStartValue" SG_ 344 HWP_Lgt_HCUTrqReqActvVld 1;
BA_ "GenSigStartValue" SG_ 347 MEB_BrkgReqValue 200;
BA_ "GenSigStartValue" SG_ 367 RSDS_BrkgReqVal 200;
BA_ "GenSigStartValue" SG_ 542 TGS_LEVER 14;
BA_ "GenSigStartValue" SG_ 542 ShiftLeverPosn_SBWM 7;
BA_ "GenSigStartValue" SG_ 566 DCT_MaxVehSpd 255;
BA_ "GenSigStartValue" SG_ 566 DCT_MinVehSpd 255;
BA_ "GenSigStartValue" SG_ 581 VehLgtAccel 22033;
BA_ "GenSigStartValue" SG_ 581 VehLatAccel 22033;
BA_ "GenSigStartValue" SG_ 581 VehYawRate 8721;
BA_ "GenSigStartValue" SG_ 659 IP_FuelMainTankR 10;
BA_ "GenSigStartValue" SG_ 659 IP_FuelAuxTankR 10;
BA_ "GenSigStartValue" SG_ 699 U_BATT 16383;
BA_ "GenSigStartValue" SG_ 699 I_RANGE 3;
BA_ "GenSigStartValue" SG_ 699 I_BATT 65535;
BA_ "GenSigStartValue" SG_ 699 T_BATT 255;
BA_ "GenSigStartValue" SG_ 699 IBATT_QUIESCENT 255;
BA_ "GenSigStartValue" SG_ 699 SOC 255;
BA_ "GenSigStartValue" SG_ 699 SOH_SUL 255;
BA_ "GenSigStartValue" SG_ 699 SOFV_StopEnable 255;
BA_ "GenSigStartValue" SG_ 699 SOFV_Restart 255;
BA_ "GenSigStartValue" SG_ 699 SOH_LAM 255;
BA_ "GenSigStartValue" SG_ 699 SOH_COR 255;
BA_ "GenSigStartValue" SG_ 699 SOC_STATE 3;
BA_ "GenSigStartValue" SG_ 699 SOH_SUL_STATE 3;
BA_ "GenSigStartValue" SG_ 699 SOFV_StopEnable_STATE 3;
BA_ "GenSigStartValue" SG_ 699 SOFV_Restart_STATE 3;
BA_ "GenSigStartValue" SG_ 699 SOH_LAM_STATE 3;
BA_ "GenSigStartValue" SG_ 699 SOH_COR_STATE 3;
BA_ "GenSigStartValue" SG_ 699 Q_Charge 65535;
BA_ "GenSigStartValue" SG_ 699 Q_Discharge 65535;
BA_ "GenSigStartValue" SG_ 707 HUT_BattSOCLimSaveMod 4;
BA_ "GenSigStartValue" SG_ 764 P2M_MotorStatorActTemp 254;
BA_ "GenSigStartValue" SG_ 764 HCU_ACStsReq 2;
BA_ "GenSigStartValue" SG_ 764 HCU_EACPwrAld 511;
BA_ "GenSigStartValue" SG_ 769 IntakeAirTemp 255;
BA_ "GenSigStartValue" SG_ 769 EngClntTempVldty 2;
BA_ "GenSigStartValue" SG_ 849 DrvSBR 1;
BA_ "GenSigStartValue" SG_ 865 P2M_DFC 254;
BA_ "GenSigStartValue" SG_ 865 P2M_MotorStatorActTemp 254;
BA_ "GenSigStartValue" SG_ 865 P2M_InverterActTemp 254;
BA_ "GenSigStartValue" SG_ 865 P2M_CoolantTemp 254;
BA_ "GenSigStartValue" SG_ 865 P2M_InvActSts 13;
BA_ "GenSigStartValue" SG_ 865 P2M_ActvDchrgSts 6;
BA_ "GenSigStartValue" SG_ 865 P2M_PosTrqAvailMax 8190;
BA_ "GenSigStartValue" SG_ 865 P2M_NegTrqAvailMin 8190;
BA_ "GenSigStartValue" SG_ 865 P2M_NegTrqAvailMin_2s 8190;
BA_ "GenSigStartValue" SG_ 865 P2M_PosTrqAvailMax_2s 8190;
BA_ "GenSigStartValue" SG_ 865 P4M_PosTrqAvailMax_2s 8190;
BA_ "GenSigStartValue" SG_ 865 P4M_NegTrqAvailMin_2s 8190;
BA_ "GenSigStartValue" SG_ 865 P4M_NegTrqAvailMin_10s 8190;
BA_ "GenSigStartValue" SG_ 865 P4M_NegTrqAvailMin 8190;
BA_ "GenSigStartValue" SG_ 865 P4M_MotorActTemp 254;
BA_ "GenSigStartValue" SG_ 865 P4M_InvActTemp 254;
BA_ "GenSigStartValue" SG_ 865 HCU_InvStsReq_P2M 13;
BA_ "GenSigStartValue" SG_ 865 HCU_P2MTrqReq 16382;
BA_ "GenSigStartValue" SG_ 880 Time_Hour 31;
BA_ "GenSigStartValue" SG_ 880 Time_Minutes 63;
BA_ "GenSigStartValue" SG_ 880 Time_Second 63;
BA_ "GenSigStartValue" SG_ 880 Time_Year_Left 15;
BA_ "GenSigStartValue" SG_ 880 Time_Year_Right 15;
BA_ "GenSigStartValue" SG_ 901 ACFrntBlwrSpd 15;
BA_ "GenSigStartValue" SG_ 901 ACDrvTemp_ATC 33;
BA_ "GenSigStartValue" SG_ 901 ACFrntPasstTemp_ATC 33;
BA_ "GenSigStartValue" SG_ 901 ACAmbTemp 254;
BA_ "GenSigSendType" SG_ 961 ECMIntErr 10;
BA_ "GenSigSendType" SG_ 1888 DiagFuncReq 10;
BA_ "GenSigSendType" SG_ 2015 DiagFuncEOBDReqFT 10;
BA_ "GenSigSendType" SG_ 1889 GW_Phy_Req 10;
BA_ "GenSigSendType" SG_ 2019 HCU_Phy_Req_EOBD 10;
BA_ "GenSigSendType" SG_ 1930 HCU_Phy_Req 10;
BA_ "GenSigSendType" SG_ 2016 ECM_Phy_Req 10;
BA_ "GenSigSendType" SG_ 1922 ESP_Phy_Req 10;
BA_ "GenSigSendType" SG_ 2021 ESP_Phy_Req_EOBD 10;
BA_ "GenSigSendType" SG_ 2017 DCT_Phy_Req 10;
BA_ "GenSigSendType" SG_ 1825 EPS_Phy_Req 10;
BA_ "GenSigSendType" SG_ 1765 EDC_Phy_Req 10;
BA_ "GenSigSendType" SG_ 1728 IB_Phy_Req 10;
BA_ "GenSigSendType" SG_ 2022 IB_Phy_Req_EOBD 10;
BA_ "GenSigSendType" SG_ 1953 GW_Phy_Resp 10;
BA_ "GenSigSendType" SG_ 2024 ECM_Phy_Resp 10;
BA_ "GenSigSendType" SG_ 1986 ESP_Phy_Resp 10;
BA_ "GenSigSendType" SG_ 2029 ESP_Phy_Resp_EOBD 10;
BA_ "GenSigSendType" SG_ 2025 DCT_Phy_Resp 10;
BA_ "GenSigSendType" SG_ 1833 EPS_Phy_Resp 10;
BA_ "GenSigSendType" SG_ 1729 IB_Phy_Resp 10;
BA_ "GenSigSendType" SG_ 2030 IB_Phy_Resp_EOBD 10;
BA_ "GenSigSendType" SG_ 1994 HCU_Phy_Resp 10;
BA_ "GenSigSendType" SG_ 2027 HCU_Phy_Resp_EOBD 10;
BA_ "GenSigSendType" SG_ 1773 EDC_Phy_Resp 10;
VAL_ 96 Checksum_HCU_PT1 0 " Valid values " ;
VAL_ 96 HCU_AccelPedalPosn_Diag 0 " Vaild value " ;
VAL_ 96 HCU_BrkPedalSts 0 " not pressed " 1 " pressed " 2 " reserved " 3 " error " ;
VAL_ 96 HCU_AccelPedalPosn_DiagValid 0 " Invaild " 1 " Vaild " ;
VAL_ 96 HCU_BrkPedalStsValid 0 " Invalid values " 1 " Valid values " ;
VAL_ 96 ActWheelTrqDmd 0 " Valid values " ;
VAL_ 96 HCU_AccelPedalPosn 0 " Vaild value " ;
VAL_ 96 HCU_AccelPedalPosnValid 0 " Invalid value " 1 " Valid value " ;
VAL_ 96 P4M_ActRotSpd 0 " Valid value " 32766 " Reserved " 65534 " Init " 65535 " invalid " ;
VAL_ 96 RollingCounter_HCU_PT1 0 " Valid value " 15 " Invalid value " ;
VAL_ 96 Checksum_HCU_PT9 0 " Valid values " ;
VAL_ 96 MaxPsblWheelTrq 0 " Vaild value " ;
VAL_ 96 TotWheelTrq 0 " Vaild value " ;
VAL_ 96 MinPsblWheelTrq 0 " Vaild value " ;
VAL_ 96 HCU_ACCInterface 0 " No response " 1 " Response " ;
VAL_ 96 RollingCounter_HCU_PT9 0 " Valid value " 15 " Invalid value " ;
VAL_ 96 Checksum_HCU_HP1 0 " Valid values " ;
VAL_ 96 HCU_NetTrq_TrsmClutch 0 " Valid values " 4001 " Reserved " ;
VAL_ 96 HCU_TrqReq_TrsmClutch 0 " Valid values " 4001 " Reserved " ;
VAL_ 96 HCU_TrqReqWoDCT_TrsmClutch 0 " Valid values " 4001 " Reserved " ;
VAL_ 96 HCU_MaxTrqLimt_TrsmClutch 0 " Valid values " 1001 " Reserved " ;
VAL_ 96 HCU_TrsmClutchAdaptAck 0 " Inactive " 1 " Active " ;
VAL_ 96 HCU_K0ClutchAdaptAck 0 " Inactive " 1 " Active " ;
VAL_ 96 HCU_NetTrq_TrsmClutchValid 0 " Invalid value " 1 " Valid value " ;
VAL_ 96 HCU_MaxEngTrqLimtValid 0 " Invalid value " 1 " Valid value " ;
VAL_ 96 HCU_TrqReqWoDCT_TrsmClutchValid 0 " Invalid value " 1 " Valid value " ;
VAL_ 96 HCU_TgtEngTrqValid 0 " Invalid value " 1 " Valid value " ;
VAL_ 96 RollingCounter_HCU_HP1 0 " Valid value " 15 " Invalid value " ;
VAL_ 96 CheckSum_HCU_HP10 0 " Valid values " ;
VAL_ 96 RegenWheelTrqAct 0 " Valid values " ;
VAL_ 96 AvailRgnTrq 0 " Valid values " ;
VAL_ 96 TargetGear_RA 0 " Default value " 1 " 1st gear " 2 " 2nd gear " 3 " N gear " ;
VAL_ 96 RegenWheelTrqActValid 0 " Invalid values " 1 " Valid values " ;
VAL_ 96 AvailRgnTrqValid 0 " Invalid value " 1 " Valid value " ;
VAL_ 96 TrqReq_FAValid 0 " Invaild " 1 " Vaild " ;
VAL_ 96 TrqReq_FA 0 " Vaild value " ;
VAL_ 96 HCU_PowertrainSts 0 " Sleep " 1 " Initialize Mode " 2 " power up " 3 " power down " 4 " Home " 5 " run " 6 " Charging " 7 " Cellphone AC " 8 " Limphome  " 9 " Emergency Mode  " 10 " V2L " 11 " Prepare Sleep " 12 " ready " 13 " LV Charging " 14 " LT Charging " 15 " IL heating " 16 " Thermal run away " 17 " End of line " 18 " BattTempKeep " 19 " Reserved " ;
VAL_ 96 RollingCounter_HCU_HP10 0 " Valid value " 15 " Invalid value " ;
VAL_ 96 Checksum_HCU_HP11 0 " Valid values " ;
VAL_ 96 HCU_P4M_ActTrq 0 " Valid values " 16382 " Init " 16383 " invalid values " ;
VAL_ 96 HCU_AccPedalPosnCorrd 0 " Vaild value " ;
VAL_ 96 ACU_ShiftInProgress 0 " Not in progress " 1 " In progress " 2 " Reserved " 3 " Invalid " ;
VAL_ 96 ACU_ActGear 0 " Default " 1 " First gear " 2 " Second gear " 3 " Neutral gear " 4 " Between position N-1    " 5 " Between position N-2 " 6 " Unknow-before/during referencing ,and in the repeatable referencing phase " 7 " Gear not determinable due to error  or final unsuccessful referencing " ;
VAL_ 96 HCU_AccPedalPosnCorrdValid 0 " Invaild " 1 " Vaild " ;
VAL_ 96 HCU_RaceLaunchSts 0 " Not active " 1 " Active " 2 " Timeout protection " 3 " Reserved " ;
VAL_ 96 HCU_RaceLaunchAvail 0 " Race Launch is available  " 1 " Race Launch is not available due to ESP is not OFF  " 2 " Race Launch is not available due to temporary hybrid system limitations  " 3 " Reserved  " ;
VAL_ 96 HCU_HWPInterface 0 " No response " 1 " Response " ;
VAL_ 96 HCU_RespHWP 0 " No response " 1 " Response " ;
VAL_ 96 Rollingcounter_HCU_HP11 0 " Valid value " 15 " Invalid value " ;
VAL_ 96 BMS_BattChrgPower_10s 0 " Valid value " 661 " Reserved " 1023 " Invalid " ;
VAL_ 96 BMS_BattDchrgPower_10s 0 " Valid value " 751 " Reserved " 1023 " Invalid " ;
VAL_ 124 CheckSum_DCT1 0 " Valid values " ;
VAL_ 124 TqIdleReq 0 " Inactive " 1 " Active " ;
VAL_ 124 TqLossAct 0 " Valid values " 65535 " Invalid values " ;
VAL_ 124 EngCrkEna 0 " No " 1 " Yes " ;
VAL_ 124 TrsmAdaptActv 0 " Inactive " 1 " Active " ;
VAL_ 124 TrqRedFastReq 0 " Valid values " 65534 " No control " 65535 " Invalid values " ;
VAL_ 124 EngTqMaxLim 0 " Valid values " 65535 " Invalid values " ;
VAL_ 124 TCUResponseHWP 0 " No response " 1 " Response " ;
VAL_ 124 RollingCounter_DCT1 0 " Valid value " 15 " Invalid value " ;
VAL_ 124 CheckSum_DCT2 0 " Valid values " ;
VAL_ 124 TC_SLIP_STATE 0 " Closed " 1 " Open  " 2 " Micro slip " 3 " Slip " 4 " Reversed " 7 " Invalid values " ;
VAL_ 124 EngIdleSpdReq 0 " Valid values " ;
VAL_ 124 EngTqGradientLim 0 " Valid values " 255 " No limit(No control) " ;
VAL_ 124 TrqRedSlowReq 0 " Valid values " 65534 " No control " 65535 " Invalid values " ;
VAL_ 124 RollingCounter_DCT2 0 " Valid value " 15 " Invalid value " ;
VAL_ 124 CheckSum_DCT3 0 " Valid values " ;
VAL_ 124 TgtEngSpdIP 0 " Valid values " ;
VAL_ 124 TgtEngSpdIPValid 0 " Invalid " 1 " Valid " ;
VAL_ 124 DCT_RaceLaunchAvail 0 " Race Launch is available " 1 " Race Launch is not available due to ESP is not OFF " 2 " Race Launch is not available due to temporary hybrid system limitations " 3 " reserved " ;
VAL_ 124 DCT_RaceLaunchProhibit 0 " no prohibit " 1 " prohibit " ;
VAL_ 124 DCT_EPBActvReqValid 0 " Invalid values  " 1 " Valid values " ;
VAL_ 124 DCT_EPBActvReq 0 " No request " 1 " Request " ;
VAL_ 124 TrsmTqIdle 0 " Valid values " 65535 " Invalid values " ;
VAL_ 124 Start_Stop_Mode_DCT 0 " Normal operation " 1 " TCU ready to stop " 2 " Engine running down " 3 " Engine stopped " 4 " Engine cranking " 5 " Engine starting " 6 " Transmit torque " 7 " Reserved " ;
VAL_ 124 StopStartFail_B_DCT 0 " No fault " 1 " Fault " ;
VAL_ 124 Start_Stop_Req_DCT 0 " No request " 1 " Inhibit engine stop (engine shall not ask for stop preparation) " 2 " Engine start request " 3 " Inhibit engine start " ;
VAL_ 124 RatAct 0 " Valid values " 254 " Unknown " 255 " Invalid values " ;
VAL_ 124 RollingCounter_DCT3 0 " Valid value " 15 " Invalid value " ;
VAL_ 124 CheckSumDCT11 0 " Valid values " ;
VAL_ 124 DCT_K1ClutchOilPressure 0 " Valid values " 65535 " Invalid values " ;
VAL_ 124 DCT_K0ClutchPredictTorque 0 " Valid values " 4001 " Reserved " ;
VAL_ 124 DCT_K1ClutchPredictTorque 0 " Valid values " 4001 " Reserved " ;
VAL_ 124 DCT_K2ClutchPredictTorque 0 " Valid values " 4001 " Reserved " ;
VAL_ 124 RollingCounterDCT11 0 " Valid value " 15 " Invalid value " ;
VAL_ 124 CheckSumDCT19 0 " Valid values " ;
VAL_ 124 TCU_TgtTrsmRatio 0 " Valid values " 254 " Unknown " 255 " Invalid values " ;
VAL_ 124 DCT_TrqRatio 0 " Valid values " 65534 " Unknown " 65535 " Invalid value " ;
VAL_ 124 RollingCounterDCT19 0 " Valid value " 15 " Invalid value " ;
VAL_ 135 PEPS_VehAuth1 0 " Valid Value " ;
VAL_ 143 Checksum_ECM1 0 " Valid values " ;
VAL_ 143 EngSpd_PHEV 0 " Valid values " ;
VAL_ 143 EngSpdVldty_PHEV 0 " InValid values " 1 " Valid values " 2 " Init value " 3 " Reserved " ;
VAL_ 143 RollingCounter_ECM1 0 " Valid value " 15 " Invalid value " ;
VAL_ 143 Checksum_ECM_HP2 0 " Valid values " ;
VAL_ 143 TrqMaxSlowPath 0 " Valid values " ;
VAL_ 143 TrqMinSlowPath 0 " Valid values " ;
VAL_ 143 TrqMaxFastPath 0 " Valid values " ;
VAL_ 143 TrqMinFastPath 0 " Valid values " ;
VAL_ 143 TgtCrsAcc 0 " Valid values " ;
VAL_ 143 TrqRngValid 0 " Invalid values " 1 " Valid values " ;
VAL_ 143 TgtCrsAccValid 0 " Invalid values " 1 " Valid values " ;
VAL_ 143 RollingCounter_ECM_HP2 0 " Valid value " 15 " Invalid value " ;
VAL_ 143 Checksum_ECM_HP4 0 " Valid values " ;
VAL_ 143 IdleTrq_PI 0 " Valid values " ;
VAL_ 143 IdleTrq_PIValid 0 " Invalid value " 1 " Valid value " ;
VAL_ 143 MaxAlwdTrqIntvntn 0 " Valid values " ;
VAL_ 143 IdleTrq_ECUInternal 0 " Valid values " ;
VAL_ 143 MinAlwdTrqIntvntn 0 " Valid values " ;
VAL_ 143 SpdGovFactor 0 " Valid values " ;
VAL_ 143 RngAlwdTrqIntvntnValid 0 " Invalid value " 1 " Valid value " ;
VAL_ 143 CANSendSts_Wakeup 0 " Not send " 1 " Send " ;
VAL_ 143 RollingCounter_ECM_HP4 0 " Valid value " 15 " Invalid value " ;
VAL_ 143 Checksum_ECM_HP3 0 " Valid values " ;
VAL_ 143 EngStatnryTrqSlowPathMax 0 " Valid values " ;
VAL_ 143 EngStatnryTrqSlowPathMin 0 " Valid values " ;
VAL_ 143 EngStatnryTrqFastPathMax 0 " Valid values " ;
VAL_ 143 EngStatnryTrqFastPathMin 0 " Valid values " ;
VAL_ 143 EngStatnryTrqRngValid 0 " Invalid value " 1 " Valid value " ;
VAL_ 143 RollingCounter_ECM_HP3 0 " Valid value " 15 " Invalid value " ;
VAL_ 143 Checksum_ECM_PT5 0 " Valid values " ;
VAL_ 143 EngTrqLimProtFastPath 0 " Valid values " ;
VAL_ 143 EngTrqLimProtSlowPath 0 " Valid values " ;
VAL_ 143 EngTrqCrankshaftLvl 0 " Valid values " ;
VAL_ 143 EngTrqCrankshaftLvlValid 0 " Invalid value " 1 " Valid value " ;
VAL_ 143 EngTrqLimProtValid 0 " Invalid value " 1 " Valid value " ;
VAL_ 143 RollingCounter_ECM_PT5 0 " Valid value " 15 " Invalid value " ;
VAL_ 143 Checksum_ECM_HP1 0 " Valid values " ;
VAL_ 143 TrqMinFastPathFCO 0 " Valid values " ;
VAL_ 143 EngTrqLoss 0 " Valid values " ;
VAL_ 143 EngErrCategory0 0 " No Error " 1 " Slight error but not affect torque and engine start " ;
VAL_ 143 EngErrCategory1 0 " No Error " 1 " Error but affect engine start " ;
VAL_ 143 EngErrCategory2 0 " No Error " 1 " Error with limited performance or inaccurate torque " ;
VAL_ 143 EngErrCategory3 0 " No Error " 1 " Limp home without torque response " ;
VAL_ 143 EngErrCategory4 0 " No Error " 1 " Shut down " ;
VAL_ 143 EngStopEnable 0 " Disable  " 1 " Enable " ;
VAL_ 143 EngStartReq 0 " Not start  " 1 " Start  " ;
VAL_ 143 ECM_TrqStructActv 0 " Inactive " 1 " Active " ;
VAL_ 143 FCOActv 0 " Inactive  " 1 " Active " ;
VAL_ 143 FCOEnable 0 " Disable " 1 " Enable " ;
VAL_ 143 EngTrqLossValid 0 " Invalid value " 1 " Valid value " ;
VAL_ 143 TrqMinFastPathFCOValid 0 " Invalid value " 1 " Valid value " ;
VAL_ 143 RollingCounter_ECM_HP1 0 " Valid value " 15 " Invalid value " ;
VAL_ 150 CheckSum_IBooster_FD3_1 0 " Valid values " ;
VAL_ 150 DrvReqTarFxBrakeAvl 0 " Valid value " 3 " Reserved " ;
VAL_ 150 DrvReqTarFxBrake 0 " Valid value " 15626 " Reserved " ;
VAL_ 150 DrvPressBrkPedalAvl 0 " Valid value " 3 " Reserved " ;
VAL_ 150 IsDrvPressBrkPedal 0 " Valid value " ;
VAL_ 150 DrvReqFxBrkDomAvail 0 " Valid value " 3 " Reserved " ;
VAL_ 150 IsDrvReqFxBrakeDom 0 " Valid value " ;
VAL_ 150 DrvReqParkBrakeAvail 0 " Valid value " 3 " Reserved " ;
VAL_ 150 DriverReqParkBrake 0 " Valid value " 3 " Reserved " ;
VAL_ 150 IsDrvReqParkBrkDom 0 " Valid value " ;
VAL_ 150 BrkDiscTempStatus 0 " Valid value " ;
VAL_ 150 BrkDiscTempStatusAvl 0 " Valid value " 3 " Reserved " ;
VAL_ 150 BrakeBckpStratState 0 " Valid value " 3 " Reserved " ;
VAL_ 150 BrkBckStratFxCtrlAvl 0 " Valid value " 5 " Reserved " ;
VAL_ 150 BrkBckStgyVehStopAvl 0 " Valid value " 5 " Reserved " ;
VAL_ 150 CurrentPumpRev 0 " Valid value " 501 " Reserved " ;
VAL_ 150 RollingCounter_IBooster_FD3_1 0 " Valid value " 15 " Invalid value " ;
VAL_ 150 CheckSum_IBooster_FD3_2 0 " Valid values " ;
VAL_ 150 CompatibilityIndexAD 0 " Valid values " ;
VAL_ 150 FxDrvBrake 0 " Valid value " 50001 " Reserved " ;
VAL_ 150 ParkBrakeRequest 0 " Valid value " 5 " Reserved " ;
VAL_ 150 DriveBckp2MnState 0 " Valid values " 12 " Reserved " ;
VAL_ 150 StopBckp2MnState 0 " Valid values " 12 " Reserved " ;
VAL_ 150 LsmBckpLvl23Avail 0 " Valid value " ;
VAL_ 150 LsmBckpLvl23Cpbl 0 " Valid value " 3 " Reserved " ;
VAL_ 150 DrvBckpLvl3Avail 0 " Valid value " ;
VAL_ 150 DrvBckpLvl3Cpbl 0 " Valid value " 3 " Reserved " ;
VAL_ 150 RollingCounter_IBooster_FD3_2 0 " Valid value " 15 " Invalid value " ;
VAL_ 150 CheckSum_IBooster_FD3_3 0 " Valid values " ;
VAL_ 150 UsedChannel 0 " Valid value " ;
VAL_ 150 BrakeFxCapability 0 " Valid value " 3 " Reserved " ;
VAL_ 150 BrakeFxAvailability 0 " Valid value " 3 " Reserved " ;
VAL_ 150 BrakeFxActual 0 " Valid value " 15626 " Reserved " ;
VAL_ 150 IsBrkFctReqFxBrkDom 0 " Valid value " ;
VAL_ 150 DecStabAvail 0 " Valid value " 3 " Reserved " ;
VAL_ 150 DecStabCpblty 0 " Valid value " ;
VAL_ 150 DecStabAvlForDriver 0 " Valid value " 3 " Reserved " ;
VAL_ 150 DecStabCpbltyForDrvr 0 " Valid value " ;
VAL_ 150 DecStabActivity 0 " Valid value " 3 " Reserved " ;
VAL_ 150 AccStabAvail 0 " Valid value " 3 " Reserved " ;
VAL_ 150 AccStabActivity 0 " Valid value " ;
VAL_ 150 YawRateStabAvl 0 " Valid value " 3 " Reserved " ;
VAL_ 150 YawRateStabActivity 0 " Valid value " ;
VAL_ 150 ParkBrakeCapability 0 " Valid value " 3 " Reserved " ;
VAL_ 150 ParkBrakeAvl 0 " Valid value " 3 " Reserved " ;
VAL_ 150 ParkBrakeState 0 " Valid value " 5 " Reserved " ;
VAL_ 150 ParkBrakeSupportReq 0 " Valid value " ;
VAL_ 150 IsBrkFctReqPrkBrkDom 0 " Valid value " ;
VAL_ 150 RollingCounter_IBooster_FD3_3 0 " Valid value " 15 " Invalid value " ;
VAL_ 161 Checksum_CSA2 0 " Valid values " ;
VAL_ 161 SteerWheelAng 0 " Valid value " 7801 " Reserved " 32767 " Invalid " ;
VAL_ 161 SteerWheelAngSign 0 " Left (Positive) " 1 " Right (Negative) " ;
VAL_ 161 SteerWheelSpd 0 " Valid value " 10161 " Reserved " 32767 " Invalid " ;
VAL_ 161 SteerWheelSpdSign 0 " Left (Positive) " 1 " Right (Negative) " ;
VAL_ 161 SAS_Sts 0 " SAS Angle And Speed Correct " 1 " SAS Not Calibrated " 2 " Intermittent Error Detected " 3 " Permanent Error Detected " ;
VAL_ 161 ManualShiftReq 0 " no shift/ no control " 1 " Shift up request  " 2 " Shift down request  " 3 " both pedals pressed " 4 " Reserved " 6 " Invalid " 7 " Fault " ;
VAL_ 161 CC_ACC_CRUISE_OFFSwt 0 " No press " 1 " Pressed " ;
VAL_ 161 CC_ACC_CANCEL_OFFSwt 0 " No press " 1 " Pressed " ;
VAL_ 161 CC_ACC_IncSetSpd_ResuSwt 0 " No press " 1 " Pressed " ;
VAL_ 161 CC_ACC_DecSetSpd_SetSwt 0 " No press " 1 " Pressed " ;
VAL_ 161 CC_ACCSwtErr 0 " No error " 1 " Error " ;
VAL_ 161 Rollingcounter_CSA2 0 " Valid value " 15 " Invalid value " ;
VAL_ 165 VehStartReq 0 " No Action " 1 " Local Start Vehicle Request " 2 " Remote Start Vehicle Request " 3 " Reserved " ;
VAL_ 168 CheckSumDCT12 0 " Valid values " ;
VAL_ 168 DCT_K2ClutchOilPressure 0 " Valid values " 65535 " Invalid values " ;
VAL_ 168 DCT_K0ClutchActTrq 0 " Valid values " 4001 " Reserved " ;
VAL_ 168 DCT_K1ClutchActTrq 0 " Valid values " 4001 " Reserved " ;
VAL_ 168 DCT_K2ClutchActTrq 0 " Valid values " 4001 " Reserved " ;
VAL_ 168 RollingCounterDCT12 0 " Valid value " 15 " Invalid value " ;
VAL_ 168 CheckSumDCT13 0 " Valid values " ;
VAL_ 168 DCT_K0ClutchTemp 0 " Valid values " 255 " Invalid values " ;
VAL_ 168 DCT_K1ClutchTemp 0 " Valid values " 255 " Invalid values " ;
VAL_ 168 DCT_K2ClutchTemp 0 " Valid values " 255 " Invalid values " ;
VAL_ 168 DCT_K0ClutchMaxSpeedDif 0 " Valid values " 8001 " Reserved " ;
VAL_ 168 DCT_TrsmClutchMaxSpeedDif 0 " Valid values " 8001 " Reserved " ;
VAL_ 168 RollingCounterDCT13 0 " Valid value " 15 " Invalid value " ;
VAL_ 168 CheckSumDCT14 0 " Valid values " ;
VAL_ 168 DCT_K0ClutchOilPressure 0 " Valid values " 65535 " Invalid values " ;
VAL_ 168 DCT_MinTrqLim_TrsmClutch 0 " Valid values " 4001 " Reserved " ;
VAL_ 168 DCT_K0ClutchMinTrqLim 0 " Valid values " 4001 " Reserved " ;
VAL_ 168 DCT_K0ClutchMaxTrqLim 0 " Valid values " 4001 " Reserved " ;
VAL_ 168 RollingCounterDCT14 0 " Valid value " 15 " Invalid value " ;
VAL_ 168 CheckSumDCT15 0 " Valid values " ;
VAL_ 168 DCT_TrqOutpLimFlg 0 " Not actived " 1 " Actived " 2 " Reserved " 3 " Invalid " ;
VAL_ 168 DCT_EngTrqLimC0 0 " Valid values " 4094 " No control (default value) " 4095 " Invalid values " ;
VAL_ 168 DCT_K0ClutchAdaptActv 0 " Inactive " 1 " Active " ;
VAL_ 168 DCT_K0ClutchActStatus 0 " Closed " 1 " Open  " 2 " Micro Slip " 3 " Slip " 4 " torque control " 5 " Filled " 6 " Reversed " 7 " Invalid values " ;
VAL_ 168 DCT_P2MotorSpdReq 0 " Valid values " 65535 " Invalid values " ;
VAL_ 168 DCT_ISS 0 " Valid values " 10001 " Reserved " 16383 " Invalid value " ;
VAL_ 168 RollingCounterDCT15 0 " Valid value " 15 " Invalid value " ;
VAL_ 168 CheckSumDCT16 0 " Valid values " ;
VAL_ 168 DCT_TrqOutput 0 " Valid values " 4095 " Invalid values " ;
VAL_ 168 TrqIncSlowReq_Ktr 0 " Valid values " 4094 " No control (default value) " 4095 " Invalid values " ;
VAL_ 168 TrqIncFastReq_Ktr 0 " Valid values " 4094 " No control (default value) " 4095 " Invalid values " ;
VAL_ 168 TCU_TgtIdleLoadTrq 0 " Valid values " 4095 " Invalid values " ;
VAL_ 168 DCT_K0EmgyReq 0 " No Request " 1 " Open Request " 2 " Close Request " 3 " Reserved " ;
VAL_ 168 DCT_RvsGearSts 0 " Inactive (not in reverse gear) " 1 " Active (in reverse gear) " 2 " Unavailable " 3 " Invalid values " ;
VAL_ 168 RollingCounterDCT16 0 " Valid value " 15 " Invalid value " ;
VAL_ 189 CheckSum_ESP11 0 " Valid values " ;
VAL_ 189 ESP_VehSpd 0 " Valid values " ;
VAL_ 189 ESP_PressEstimdMax 0 " Valid values " 251 " InValid " ;
VAL_ 189 ESP_QntyTgtExt 0 " Valid values " 64513 " Reserved " ;
VAL_ 189 ESP_VehSpdValid 0 " Not initialized " 1 " Normal " 2 " Faulty " ;
VAL_ 189 ESP_QntyTgtExtVld 0 " qTarget_Off " 1 " qTarget_EBR " 2 " qTarget_EBR_SensDrvDet " 3 " Reserved " ;
VAL_ 189 ESP_HMI_WarningOn 0 " No warning lamp " 1 " Yellow Lamp " 2 " Red Lamp " 3 " reserved " ;
VAL_ 189 ESP_IGNOn 0 " IgnitionOff " 1 " IgnitionOn " ;
VAL_ 189 ESP_ABSActv 0 " ABS inactive " 1 " ABS active " ;
VAL_ 189 RollingCounter_ESP11 0 " Valid value " 15 " Invalid value " ;
VAL_ 189 CheckSum_ESP12 0 " Valid values " ;
VAL_ 189 ESP_PMC1 0 " Valid values " 1023 " Reserved " ;
VAL_ 189 ESP_PMC1Vld 0 " Not initialized " 1 " Normal " 2 " Faulty " ;
VAL_ 189 ESP_ForceBldActv 0 " PFC inactive " 1 " PFC hold " 2 " PFC active " ;
VAL_ 189 ESP_PMCVirt 0 " Valid values " 1001 " InValid " ;
VAL_ 189 ESP_PMCVirtVld 0 " Not initialized " 1 " Normal " 2 " Faulty " ;
VAL_ 189 ESP_PressForceBldMC 0 " Valid values " 1001 " InValid " ;
VAL_ 189 ESP_PressForceBldMCVld 0 " Not initialized " 1 " Normal " 2 " Faulty " ;
VAL_ 189 RollingCounter_ESP12 0 " Valid value " 15 " Invalid value " ;
VAL_ 189 Checksum_ESP10 0 " Valid values " ;
VAL_ 189 TgtRcprtnTrqReq 0 " Valid values " ;
VAL_ 189 TgtRcprtnTrqSts 0 " Not Initialized " 1 " Normal " 2 " Faulty " 3 " Reserved " ;
VAL_ 189 RollingCounter_ESP10 0 " Valid value " 15 " Invalid value " ;
VAL_ 189 CheckSum_ESP_FD1_3 0 " Valid values " ;
VAL_ 189 DriveMn2BckpState 0 " Valid value " 12 " Reserved " ;
VAL_ 189 StopMn2BckpState 0 " Valid value " 12 " Reserved " ;
VAL_ 189 LsmMainLvl23Avail 0 " Valid value " ;
VAL_ 189 LsmMainLvl23Cpbl 0 " Valid value " 3 " Reserved " ;
VAL_ 189 DrvMainLvl3Avail 0 " Valid value " ;
VAL_ 189 DrvMainLvl3Cpbl 0 " Valid value " 3 " Reserved " ;
VAL_ 189 LsmMotionSrvReq 0 " Valid value " 5 " Reserved " ;
VAL_ 189 RollingCounter_ESP_FD1_3 0 " Valid value " 15 " Invalid value " ;
VAL_ 189 CheckSum_ESP_FD1_5 0 " Valid values " ;
VAL_ 189 UsedChannel 0 " Valid value " ;
VAL_ 189 BrakeFxCapability 0 " Valid value " 3 " Reserved " ;
VAL_ 189 BrakeFxAvailability 0 " Valid value " 3 " Reserved " ;
VAL_ 189 IsBrkFctReqFxBrkDom 0 " Valid value " ;
VAL_ 189 DecStabAvail 0 " Valid value " 3 " Reserved " ;
VAL_ 189 DecStabCpblty 0 " Valid value " ;
VAL_ 189 DecStabAvlForDriver 0 " Valid value " 3 " Reserved " ;
VAL_ 189 DecStabCpbltyForDrvr 0 " Valid value " ;
VAL_ 189 DecStabActivity 0 " Valid value " 3 " Reserved " ;
VAL_ 189 AccStabAvail 0 " Valid value " 3 " Reserved " ;
VAL_ 189 AccStabActivity 0 " Valid value " ;
VAL_ 189 YawRateStabAvl 0 " Valid value " 3 " Reserved " ;
VAL_ 189 YawRateStabActivity 0 " Valid value " ;
VAL_ 189 ParkBrakeCapability 0 " Valid value " 3 " Reserved " ;
VAL_ 189 ParkBrakeAvl 0 " Valid value " 3 " Reserved " ;
VAL_ 189 ParkBrakeState 0 " Valid value " 5 " Reserved " ;
VAL_ 189 ParkBrakeSupportReq 0 " Valid value " ;
VAL_ 189 IsBrkFctReqPrkBrkDom 0 " Valid value " ;
VAL_ 189 BrakeFxActual 0 " Valid value " 15626 " Reserved " ;
VAL_ 189 RollingCounter_ESP_FD1_5 0 " Valid value " 15 " Invalid value " ;
VAL_ 189 CheckSum_ESP_FD1_6 0 " Valid values " ;
VAL_ 189 DrvReqTarFxBrakeAvl 0 " Valid value " 3 " Reserved " ;
VAL_ 189 DrvPressBrkPedalAvl 0 " Valid value " 3 " Reserved " ;
VAL_ 189 IsDrvPressBrkPedal 0 " Valid value " ;
VAL_ 189 DrvReqFxBrkDomAvail 0 " Valid value " 3 " Reserved " ;
VAL_ 189 IsDrvReqFxBrakeDom 0 " Valid value " ;
VAL_ 189 DrvReqParkBrakeAvail 0 " Valid value " 3 " Reserved " ;
VAL_ 189 DriverReqParkBrake 0 " Valid value " 3 " Reserved " ;
VAL_ 189 IsDrvReqParkBrkDom 0 " Valid value " ;
VAL_ 189 BrkDiscTempStatus 0 " Valid value " ;
VAL_ 189 BrkDiscTempStatusAvl 0 " Valid value " 3 " Reserved " ;
VAL_ 189 BrakeBckpStratState 0 " Valid value " 3 " Reserved " ;
VAL_ 189 BrkBckStratFxCtrlAvl 0 " Valid value " 5 " Reserved " ;
VAL_ 189 BrkBckStgyVehStopAvl 0 " Valid value " 5 " Reserved " ;
VAL_ 189 DrvReqTarFxBrake 0 " Valid value " 15626 " Reserved " ;
VAL_ 189 CurrentPumpRev 0 " Valid value " 501 " Reserved " ;
VAL_ 189 RollingCounter_ESP_FD1_6 0 " Valid value " 15 " Invalid value " ;
VAL_ 190 CheckSum_P2M3 0 " Valid value " ;
VAL_ 190 P2M_ActSpd 0 " Valid value " 12287 " Invalid " ;
VAL_ 190 RollingCounter_P2M3 0 " Valid value " 15 " Invalid value " ;
VAL_ 199 CheckSum_SBWM1 0 " Valid values " ;
VAL_ 199 DRV_RQ_SHFT 0 " Shifter position zero (Z) / POS_ZERO " 1 " Reserved " 2 " Shifter position two (forward twice / x2) / POS_TWO " 3 " Shifter position three (forward once / x1) / POS_THREE " 4 " Shifter position four (backwards once / Y1) / POS_FOUR " 5 " Shifter position five (backwards twice / Y2) / POS_FIVE " 6 " Reserved " 7 " Reserved " 8 " Shifter not initialized / INIT " 9 " Reserved " 15 " Signal not available / SNA (Double fault shifter sensor) " ;
VAL_ 199 DrvReqShftInv 0 " Signal not available / SNA (Double fault shifter sensor) " 1 " Reserved " 7 " Shifter not initialized / INIT " 8 " Reserved " 9 " Reserved " 10 " Shifter position five (backwards twice / Y2) / POS_FIVE " 11 " Shifter position four (backwards once / Y1) / POS_FOUR " 12 " Shifter position three (forward once / x1) / POS_THREE " 13 " Shifter position two (forward twice / x2) / POS_TWO " 14 " Reserved " 15 " Shifter position zero (Z) / POS_ZERO " ;
VAL_ 199 ShftSensFlt 0 " Shift sensor single OK " 1 " Shift sensor single fault " ;
VAL_ 199 ShftDispFlt 0 " Display OK " 1 " Display fault " ;
VAL_ 199 DrvReqUnlock 0 " no request " 1 " driver request unlock button " ;
VAL_ 199 DrvReqPark 0 " no request " 1 " driver request park button " 2 " Park button fault " 3 " reserved " ;
VAL_ 199 E_ShiftFault 0 " E-shift Normal " 1 " E-shift fault " 2 " reserved " ;
VAL_ 199 RollingCounter_SBWM1 0 " Valid value " 15 " Invalid value " ;
VAL_ 209 Checksum_Ibooster1 0 " Valid values " ;
VAL_ 209 IB_DrvOutpRodVal 0 " Valid values " ;
VAL_ 209 IB_CurrOutpRodVal 0 " Valid values " ;
VAL_ 209 IB_DrvOutpRodValVld 0 " Not initialized " 1 " Normal " 2 " Faulty " 3 " Reserved " ;
VAL_ 209 IB_CurrOutpRodValVld 0 " Not initialized " 1 " Normal " 2 " Faulty " 3 " Reserved " ;
VAL_ 209 IB_ExtReqPrio 0 " EBR not dominate the brake torque " 1 " EBR dominate the brake torque " ;
VAL_ 209 IB_ExtReqSts 0 " EBR not initialized " 1 " EBR not available " 2 " EBR available " 3 " Reserved " ;
VAL_ 209 RollingCounter_Ibooster1 0 " Valid value " 15 " Invalid value " ;
VAL_ 234 Checksum_HCU_HP2 0 " Valid values " ;
VAL_ 234 HCU_TrsmStsReq 0 " Transmission passive request " 1 " Transmission active request " ;
VAL_ 234 HCU_FastRedTrqLim_TrsmClutch 0 " Valid values " 4001 " Reserved " ;
VAL_ 234 HCU_MinTrqLim_TrsmClutch 0 " Valid values " 4001 " Reserved " ;
VAL_ 234 TrqAct_RA 0 " Valid values " ;
VAL_ 234 FastRedTrqLimValid 0 " Invalid value " 1 " Valid value " ;
VAL_ 234 TrqAct_RAValid 0 " Invalid value " 1 " Valid value " ;
VAL_ 234 HCU_MinEngTrqLimValid 0 " Invalid value " 1 " Valid value " ;
VAL_ 234 RollingCounter_HCU_HP2 0 " Valid value " 15 " Invalid value " ;
VAL_ 234 Checksum_HCU_HP3 0 " Valid values " ;
VAL_ 234 HCU_P2MActTrq 0 " Valid values " 4094 " Init " 4095 " invalid " ;
VAL_ 234 HCU_TrqInterventionStateESP 0 " No ESP Intervention " 1 " ESP TrqRedFastReq_FA " 2 " ESP TrqRedSlowReq_FA " 3 " ESP TrqIncReq_FA " ;
VAL_ 234 HCU_TrsmClutchStatusReq 0 " No request " 1 " comfort open request " 2 " emergency open request " 3 " slipping request " ;
VAL_ 234 AntiSurgeDamperInhb 0 " Not inhibit " 1 " Inhibit " ;
VAL_ 234 HCU_PTRdy 0 " No Ready " 1 " Ready " ;
VAL_ 234 HCU_EngIdleReq 0 " NO request " 1 " Request " ;
VAL_ 234 FastTrqIntvntn 0 " Not active " 1 " Active " ;
VAL_ 234 NoRampsReq 0 " NO request " 1 " Request " ;
VAL_ 234 RelsIGNReq 0 " NO request " 1 " Request " ;
VAL_ 234 FullTrqReq 0 " NO request " 1 " Request " ;
VAL_ 234 HCU_EngStartReq 0 " NO request " 1 " Request " ;
VAL_ 234 HCU_EngStopReq 0 " NO request " 1 " Request " ;
VAL_ 234 FuelCutOffReq 0 " NO request " 1 " Request " ;
VAL_ 234 CrsCtrlOvldAccelPedal 0 " Not active " 1 " Active " ;
VAL_ 234 TrqReqSlowPathEnable 0 " Not enable " 1 " Enable " ;
VAL_ 234 TrqReqFastPathEnable 0 " Not enable " 1 " Enable " ;
VAL_ 234 HCU_EngStartPre 0 " Not active " 1 " Active " ;
VAL_ 234 HCU_StartStopTypReq 0 " init and no start " 1 " conventional 12V start idle " 2 " 12V BSG start idle / GM idle start " 3 " 12V BSG start drive / GM normal start " 4 " P2 start idle/GM Cold Start Idle " 5 " P2 start comfort drive " 6 " Launch start " 7 " P2 start dynamic drive " ;
VAL_ 234 TrqReq_RAValid 0 " Invaild " 1 " Vaild " ;
VAL_ 234 TrqReq_RA 0 " Vaild value " ;
VAL_ 234 RollingCounter_HCU_HP3 0 " Valid value " 15 " Invalid value " ;
VAL_ 234 Checksum_HCU_HP4 0 " Valid values " ;
VAL_ 234 TrqLowLimit 0 " Vaild value " 1023 " Invalid value " ;
VAL_ 234 IdleTrqReserveReq 0 " Vaild value " ;
VAL_ 234 P2M_InvActSts 0 " InverterStandby " 1 " TorqueCtrl " 2 " SpeedCtrl " 3 " VoltageCtrl_Precharge " 4 " VoltageCtrl_LoadCompensation " 5 " InverterError " 6 " InverterSafeState " 7 " InverterCrashPreSleep(for A1) " 8 " Inverter Init mode " 9 " CrashInit(for A1) " 10 " PrepareSleep " 11 " Resolver Offset Detection " 12 " AC Insulation Detection " 13 " Sleep mode " 14 " Reserved " 15 " OFF " ;
VAL_ 234 P4M_OperMod 0 " InverterStandby " 1 " TorqueCtrl " 2 " SpeedCtrl " 3 " VoltageCtrl_Precharge " 4 " VoltageCtrl_LoadCompensation " 5 " InverterError " 6 " InverterSafeState " 7 " InverterCrashPreSleep(for A1) " 8 " Inverter Init mode " 9 " CrashInit(for A1) " 10 " PrepareSleep " 11 " Resolver Offset Detection " 12 " AC Insulation Detection " 13 " Sleep mode " 14 " Reserved " 15 " OFF " ;
VAL_ 234 RollingCounter_HCU_HP4 0 " Valid value " 15 " Invalid value " ;
VAL_ 234 CheckSum_HCU_HP8 0 " Valid values " ;
VAL_ 234 IdleLoadTrq 0 " Valid values " 4095 " Invalid value " ;
VAL_ 234 HCU_TrqLimMax_Norm 0 " Valid values " 276 " Reserved " ;
VAL_ 234 TrqReqSlowPath 0 " Valid values " 4095 " Invalid value " ;
VAL_ 234 TrqReqFastPath 0 " Valid values " 4095 " Invalid value " ;
VAL_ 234 RollingCounter_HCU_HP8 0 " Valid value " 15 " Invalid value " ;
VAL_ 234 Checksum_HCU_HP9 0 " Valid values " ;
VAL_ 234 HCU_K0ClutchStatusReq 0 " No request " 1 " open request " 2 " close request " 3 " HCU K0 torque control request " ;
VAL_ 234 HCU_TrsmClutchTargetSpeedDif 0 " Valid values " 1001 " Reserved " ;
VAL_ 234 HCU_K0ClutchTrqReq 0 " Valid values " 4001 " Reserved " ;
VAL_ 234 TorqueLossValid 0 " Invalid value " 1 " Valid value " ;
VAL_ 234 HCU_KickDownActv 0 " Not active " 1 " Active " ;
VAL_ 234 HCU_EVTgtGearSts 0 " Not active " 1 " Active " 2 " InValid values " 3 " Reserved " ;
VAL_ 234 HCU_DCTCreepInhbn 0 " Not active " 1 " Active " ;
VAL_ 234 TorqueLoss 0 " Valid values " ;
VAL_ 234 RollingCounter_HCU_HP9 0 " Valid value " 15 " Invalid value " ;
VAL_ 234 HCU_ChrgDeplt 0 " No " 1 " Yes " ;
VAL_ 259 Checksum_ECM9 0 " Valid values " ;
VAL_ 259 EngTgtIdleSpd 0 " Valid values " ;
VAL_ 259 EngCatWarmUp 0 " Valid values " 101 " Reserved " 255 " Fault/error " ;
VAL_ 259 RollingCounter_ECM9 0 " Valid value " 15 " Invalid value " ;
VAL_ 259 CheckSum_ECM2 0 " Valid values " ;
VAL_ 259 FuelConsumption 0 " Valid values " ;
VAL_ 259 EngSVSSig 0 " SVS off " 1 " SVS on " ;
VAL_ 259 ThrtlPosRatio 0 " Valid values " 255 " Invalid values " ;
VAL_ 259 TgtCrsVehSpd 0 " Valid values " ;
VAL_ 259 TgtCrsVehSpdvalid 0 " Invalid values " 1 " Valid values " ;
VAL_ 259 MILSts 0 " OFF " 1 " ON " ;
VAL_ 259 RollingCounter_ECM2 0 " Valid value " 15 " Invalid value " ;
VAL_ 259 Checksum_ECM_HP6 0 " Valid values " ;
VAL_ 259 EngCrankshaftPosn 0 " Valid values " 120 " Reserved " 127 " Fault/error " ;
VAL_ 259 Engoverspd 0 " Not over " 1 " Over  " 2 " invalid values " 3 " Reserved " ;
VAL_ 259 FCOReq 0 " no request " 1 " request " 2 " Invalid values " 3 " Reserved " ;
VAL_ 259 EngSpdLim 0 " Valid values " ;
VAL_ 259 RollingCounter_ECM_HP6 0 " Valid value " 15 " Invalid value " ;
VAL_ 259 CheckSum_ECM_PT7 0 " Valid values " ;
VAL_ 259 EngState_PHEV 0 " Stand by " 1 " Ready " 2 " Cranking " 3 " Running " 4 " Stopping " 5 " Finish " 6 " Autostopping " 7 " Reserved " ;
VAL_ 259 EngStalled 0 " Not stalled " 1 " Stalled " ;
VAL_ 259 CruiseCtrlSts_PHEV 0 " OFF " 1 " Stand by " 2 " Cruise " 3 " Acceleration  " 4 " Deceleration " 5 " Tip up " 6 " Tip dwon " 7 " Resume from above vehicle speed " 8 " Resume from below vehicle speed " 9 " Error " 10 " Reserved " ;
VAL_ 259 IdleSpdDmd 0 " No demand  " 1 " Demand  " ;
VAL_ 259 IdleSpdSts 0 " Not in idle speed ststus " 1 " Idle speed status " ;
VAL_ 259 RollingCounter_ECM_PT7 0 " Valid value " 15 " Invalid value " ;
VAL_ 288 Checksum_Ibooster2 0 " Valid values " ;
VAL_ 288 IB_Cmpatbltyindcd 0 " Valid values " ;
VAL_ 288 IB_BrkPedalAppld 0 " Not applied " 1 " Applied " ;
VAL_ 288 IB_BrkPedalAppldVld 0 " Not initialized " 1 " Normal " 2 " Faulty " 3 " Reserved " ;
VAL_ 288 IB_HBCReq 0 " No HBC support requested(Also init value) " 1 " HBC full support requested " ;
VAL_ 288 IB_PressRunout 0 " Valid values " 251 " Reserved " ;
VAL_ 288 IB_PressRunoutVld 0 " Not initialized " 1 " Normal " 2 " Faulty " 3 " Reserved " ;
VAL_ 288 IB_DiagActv 0 " iBooster diagnosis is inactive " 1 " iBooster diagnosis is active " ;
VAL_ 288 IB_RPRMod 0 " Passive " 1 " Preload " 2 " Hold " 3 " Suction " 4 " Hold low pressure " 5 " Abort " ;
VAL_ 288 IB_PressForceBldPotialVld 0 " Not initialized " 1 " Normal " 2 " Faulty " 3 " Reserved " ;
VAL_ 288 IB_PressForceBldPotial 0 " Valid values " 251 " Reserved " ;
VAL_ 288 IB_BLA 0 " No request to the brake light " 1 " Brake light requested " ;
VAL_ 288 IB_Warn 0 " Warning lamp off " 1 " Warning lamp on " ;
VAL_ 288 IBooster_MILSts 0 " the Warning(Mil) light is off  " 1 " the Warning(Mil) light is on " ;
VAL_ 288 RollingCounter_Ibooster2 0 " Valid value " 15 " Invalid value " ;
VAL_ 288 CheckSum_ABS1 0 " Valid values " ;
VAL_ 288 FLWheelDriveDirection 0 " Invalid " 1 " Forward " 2 " Backward " 3 " Stop " ;
VAL_ 288 FLWheelSpdVld 0 " Invalid " 1 " Valid " ;
VAL_ 288 FLWheelSpd 0 " Valid values " 5334 " Reserved " ;
VAL_ 288 FRWheelDriveDirection 0 " Invalid " 1 " Forward " 2 " Backward " 3 " Stop " ;
VAL_ 288 FRWheelSpdVld 0 " Invalid " 1 " Valid " ;
VAL_ 288 FRWheelSpd 0 " Valid values " 5334 " Reserved " ;
VAL_ 288 WssFLEdgesSum 0 " Valid Values " ;
VAL_ 288 WssFREdgesSum 0 " Valid Values " ;
VAL_ 288 WssFLEdgesSumVld 0 " Invalid " 1 " Valid " ;
VAL_ 288 WssFREdgesSumVld 0 " Invalid " 1 " Valid " ;
VAL_ 288 RollingCounter_ABS1 0 " Valid value " 15 " Invalid value " ;
VAL_ 288 CheckSum_ABS3 0 " Valid values " ;
VAL_ 288 VehSpdVld 0 " Invalid " 1 " Valid " ;
VAL_ 288 VehSpd 0 " Valid values " 5334 " Reserved " ;
VAL_ 288 RollingCounter_ABS3 0 " Valid value " 15 " Invalid value " ;
VAL_ 288 CheckSum_IBooster_FD2_5 0 " Valid values " ;
VAL_ 288 L3VLCADactive 0 " Not active " 1 " Active " ;
VAL_ 288 L3mainVMCavailiable 0 " Not initialized " 1 " Not Available " 2 " Available " 3 " Availablewithfault " ;
VAL_ 288 VLC_TgtGear 0 " Idle " 1 " -P- " 2 " -R- " 3 " -N- " 4 " -D- " 5 " reserved " ;
VAL_ 288 RollingCounter_Booster_FD2_5 0 " Valid value " 15 " Invalid value " ;
VAL_ 288 CheckSum_ABS2 0 " Valid values " ;
VAL_ 288 RLWheelDriveDirection 0 " Invalid " 1 " Forward " 2 " Backward " 3 " Stop " ;
VAL_ 288 RLWheelSpdVld 0 " Invalid " 1 " Valid " ;
VAL_ 288 RLWheelSpd 0 " Valid values " 5334 " Reserved " ;
VAL_ 288 RRWheelDriveDirection 0 " Invalid " 1 " Forward " 2 " Backward " 3 " Stop " ;
VAL_ 288 RRWheelSpdVld 0 " Invalid " 1 " Valid " ;
VAL_ 288 RRWheelSpd 0 " Valid values " 5334 " Reserved " ;
VAL_ 288 WssRREdgesSum 0 " Valid Values " ;
VAL_ 288 WssRLEdgesSum 0 " Valid Values " ;
VAL_ 288 WssRLEdgesSumVld 0 " Invalid " 1 " Valid " ;
VAL_ 288 WssRREdgesSumVld 0 " Invalid " 1 " Valid " ;
VAL_ 288 RollingCounter_ABS2 0 " Valid value " 15 " Invalid value " ;
VAL_ 299 Checksum_IFC1 0 " Valid value " ;
VAL_ 299 IFCTrqOvlCmdProtnValue 0 " Valid value " ;
VAL_ 299 IFCTrqOvlCmdReqValue 0 " Valid value " ;
VAL_ 299 IFCFuncTrqCmdReqFlag 0 " No Request " 1 " LKA Request " 2 " ESS Request " 3 " Reserved " ;
VAL_ 299 IFCVibrationWarning 0 " No Request " 1 " LeveL 1 " 2 " Reserved " ;
VAL_ 299 RollingCounter_IFC1 0 " Valid value " 15 " Invalid value " ;
VAL_ 303 Checksum_HCU_PT5 0 " Valid values " ;
VAL_ 303 HCU_DrvMod 0 " Auto/Normal Mode started " 1 " EV Mode started " 2 " Save Mode started " 3 " SPORT Mode started " 4 " AWD Normal Mode started " 5 " Snow Mode started " 6 " Muddy Mode started " 7 " Sand Mode started " 8 " ECO " 9 " SPORT Plus Mode started " 10 " Reserved " ;
VAL_ 303 HCU_PTDrvMod 0 " No propel torque  " 1 " H-FWD (发动机+P2，或发动机) " 2 " E-FWD（纯电即P2） " 3 " RWD （纯电即P4） " 4 " H-AWD（混动四驱即发动机+P4，或P2+发动机+P4） " 5 " E-AWD（纯电四驱，即P2+P4） " 6 " Reserved " ;
VAL_ 303 DrvTrqReqOvld 0 " No driver override " 1 " Driver override " 2 " Reserved " 3 " invalid values " ;
VAL_ 303 HCUImmoAuthRes 0 " Idle " 1 " Passed " 2 " Failed " 3 " Invalid value " ;
VAL_ 303 HCU_EPSEnable 0 " Disable " 1 " Enable " ;
VAL_ 303 HCU_EngLimpHome 0 " Not in limp home mode " 1 " In limp home mode " ;
VAL_ 303 HCU_VitlAccelPedalPosn_CrpValid 0 " Invaild " 1 " Vaild " ;
VAL_ 303 HCU_EVLmpSts 0 " Not active " 1 " Active " ;
VAL_ 303 HCU_ECODrvHabit_Indcn 0 " Valid values " 201 " Reversed " ;
VAL_ 303 HCU_TotDrvReqPower 0 " Valid values-Power percentage Value（-100-0-100） " 201 " invalid values " ;
VAL_ 303 HCU_VitlAccelPedalPosn_Crp 0 " Vaild value  " ;
VAL_ 303 HCU_AvailPower_TM 0 " Valid values " 101 " invalid values " ;
VAL_ 303 RollingCounter_HCU_PT5 0 " Valid value " 15 " Invalid value " ;
VAL_ 303 Checksum_HCU_HP6 0 " Valid values " ;
VAL_ 303 IdleSpdSetPointReq 0 " vaild value " 2046 " Init " 2047 " Invalid value " ;
VAL_ 303 HCU_VirtLoad_FA 0 " 0% " 1 " 5% " 2 " 10% " 3 " 15% " 4 " 20% " 5 " 25% " 6 " 30% " 7 " 35% " 8 " 40% " 9 " 45% " 10 " 50% " 11 " 55% " 12 " 60% " 13 " 65% " 14 " 70% " 15 " 75% " 16 " 80% " 17 " 85% " 18 " 90% " 19 " 95% " 20 " 100% " 21 " Reserved " 31 " Invalid value " ;
VAL_ 303 HCU_VirtAccelPedalPosn_FA 0 " Vaild value " ;
VAL_ 303 HCU_GearShftInhibitReq_FA 0 " Not active " 1 " Active " ;
VAL_ 303 HCU_EngSts 0 " Stopped " 1 " Cranking " 2 " Firing " 3 " transmit torque " 4 " normal operation " 5 " Stopping preparation " 6 " Stopping " 7 " Stalling " ;
VAL_ 303 HCU_VirtAccelPedalPosn_FAValid 0 " Invalid value " 1 " Valid value " ;
VAL_ 303 CrsCtrlSwSts_ASIL 0 " OFF " 1 " ON " ;
VAL_ 303 CrsCtrlSwSts_NoClrSpd 0 " OFF " 1 " ON " ;
VAL_ 303 CrsCtrlSwSts_ClrSpd 0 " OFF " 1 " ON " ;
VAL_ 303 HCU_APS_Available 0 " Available " 1 " Not available " ;
VAL_ 303 RollingCounter_HCU_HP6 0 " Valid value " 15 " Invalid value " ;
VAL_ 303 HCU_SaveModChrgMod_OBD 0 " Not save " 1 " Save " 2 " Parking charge " 3 " Road charging " 4 " Uncharged state " 5 " Charging completed " ;
VAL_ 303 HCU_VehSpdLimit 0 " Valid value " ;
VAL_ 311 CheckSum_ESP_FD2_1 0 " Valid values " ;
VAL_ 311 L12VLCADactive 0 " Not active " 1 " Active " ;
VAL_ 311 L12mainVMCavailiable 0 " Not Available " 1 " Available " ;
VAL_ 311 WssCoreMonRob 0 " Valid values " ;
VAL_ 311 TtcFactor_FL 0 " Valid value " 60001 " Reserved " ;
VAL_ 311 TtcFactor_FR 0 " Valid value " 60001 " Reserved " ;
VAL_ 311 RollingCounter_ESP_FD2_1 0 " Valid value " 15 " Invalid value " ;
VAL_ 311 CheckSum_ESP2 0 " Valid values " ;
VAL_ 311 BrkDskOvrheatd 0 " Not high " 1 " Temp too high " ;
VAL_ 311 NoBrkForce 0 " Exist brake force " 1 " No brake force " ;
VAL_ 311 VehStandstill 0 " Not standstill " 1 " Standstill " 2 " InValid values (short unavailability, max 3s) " 3 " Reserved " ;
VAL_ 311 SwtOffCrsCtrl 0 " Not switch off cruise control " 1 " switch off cruise control " ;
VAL_ 311 HHCSts 0 " Not active " 1 " Active " ;
VAL_ 311 AEBIBActv 0 " Not active " 1 " Active " ;
VAL_ 311 AEBBAActv 0 " Not active " 1 " Active " ;
VAL_ 311 AEBAvailable 0 " Unusable " 1 " Usable " ;
VAL_ 311 ABPAvailable 0 " Unusable " 1 " Usable " ;
VAL_ 311 ABPActv 0 " Not active " 1 " Active " ;
VAL_ 311 ABAavailable 0 " Unusable " 1 " Usable " ;
VAL_ 311 ABAActv 0 " Not active " 1 " Active " ;
VAL_ 311 HDCFault 0 " No failure " 1 " Failure when HDC is on need " 2 " Failure when is not on need " 3 " Reserved " ;
VAL_ 311 HDCCtrl 0 " OFF " 1 " On active braking " 2 " On not active braking " ;
VAL_ 311 CDDActv 0 " Not active " 1 " Active " ;
VAL_ 311 CDDAvailable 0 " Not available " 1 " Available " ;
VAL_ 311 AWBAvailable 0 " Unusable " 1 " Usable " ;
VAL_ 311 AWBActv 0 " Not active " 1 " Active " ;
VAL_ 311 AVHErrSts 0 " No failure " 1 " Failure when AVH is on need " 2 " Failure when is not on need " 3 " Reserved " ;
VAL_ 311 AVHSts 0 " Off " 1 " Standby  " 2 " active " ;
VAL_ 311 CDPVld 0 " InValid values " 1 " Valid values " ;
VAL_ 311 CDPActv 0 " Not active " 1 " Active " ;
VAL_ 311 SysOperatingMod_ESP 0 " ESP OFF " 1 " normal " 2 " Snow " 3 " Mud " 4 " Sand " 5 " Sport(Reserved） " 6 " Reserved " ;
VAL_ 311 SCMActv 0 " Not Active " 1 " Active " ;
VAL_ 311 CTABrkAvailable 0 " Not Available " 1 " Available " ;
VAL_ 311 RollingCounter_ESP2 0 " Valid value " 15 " Invalid value " ;
VAL_ 311 CheckSum_ESP1 0 " Valid values " ;
VAL_ 311 ESPFuncOffSts 0 " Available/On " 1 " Unavailable/Off " ;
VAL_ 311 ESPActvInfoLmp 0 " Not active " 1 " Active " ;
VAL_ 311 ESPBrkLmpCtrl 0 " Brake light off " 1 " Brake light on " ;
VAL_ 311 ESPFailSts 0 " No failure " 1 " Failure " ;
VAL_ 311 ESP_MasterCylBrkPressVld 0 " Invalid " 1 " Valid " ;
VAL_ 311 GearShftInhibitReq_FA 0 " Not active " 1 " Active " ;
VAL_ 311 MSRActv 0 " Not active " 1 " Active " ;
VAL_ 311 VDCActv 0 " Not active " 1 " Active " ;
VAL_ 311 PTCActv 0 " Not active " 1 " Active " ;
VAL_ 311 BTCActv 0 " Not active " 1 " Active " ;
VAL_ 311 MSRActv_RA 0 " Inactive " 1 " Active " ;
VAL_ 311 PTCActv_RA 0 " Inactive " 1 " Active " ;
VAL_ 311 BTCActv_RA 0 " Inactive " 1 " Active " ;
VAL_ 311 ESP_MasterCylBrkPress 0 " Valid values value " 14961 " Reserved " ;
VAL_ 311 TrqMaxLim 0 " Valid values  0xFFF " ;
VAL_ 311 RollingCounter_ESP1 0 " Valid value " 15 " Invalid value " ;
VAL_ 311 CheckSum_ESP7 0 " Valid values " ;
VAL_ 311 ESP_MEBBrkAvail 0 " Not Available " 1 " Available " ;
VAL_ 311 APS_EngTrqReqEna 0 " No demand " 1 " Valid values torque demand " ;
VAL_ 311 EngTrqReq 0 " Valid values " ;
VAL_ 311 ESP_APS_GearBoxEna 0 " No Request " 1 " Request " ;
VAL_ 311 ESP_APS_TgtGear 0 " Idle " 1 " -P- " 2 " -R- " 3 " -N- " 4 " -D- " 5 " reserved " ;
VAL_ 311 FourWhlsBrkTrq 0 " Valid values value " ;
VAL_ 311 LgtCtrlrAvail 0 " Not Available " 1 " Reserved " 2 " Reserved " 3 " Reserved " 4 " Reserved " 5 " AutomaticPark " 6 " Reserved " ;
VAL_ 311 LgtCtrlrFailr 0 " No Error " 1 " Vehicle_Blocked " 2 " Unexpected_GearPosition " 3 " Unexpected_EPB_Action " 4 " Reserved " 5 " Unexpected_GearIntervention " 6 " Active Braking failure " 7 " Invalid values " ;
VAL_ 311 LgtCtrlrSts 0 " Off " 1 " Standby " 2 " Reserved " 3 " Reserved " 4 " Active_AutomaticPark " 5 " Reserved " 6 " Reserved " 7 " Invalid values " ;
VAL_ 311 RollingCounter_ESP7 0 " Valid value " 15 " Invalid value " ;
VAL_ 311 CheckSum_ESP4 0 " Valid values " ;
VAL_ 311 DrvTrqIncReq_FA 0 " Valid values value " ;
VAL_ 311 DrvTrqRedFastReq_FA 0 " Valid values value " ;
VAL_ 311 DrvTrqRedSlowReq_FA 0 " Valid values value " ;
VAL_ 311 DrvTrqRedReqActv_FA 0 " Not active " 1 " Active " ;
VAL_ 311 DrvTrqIncReqActv_FA 0 " Not active " 1 " Active " ;
VAL_ 311 RollingCounter_ESP4 0 " Valid value " 15 " Invalid value " ;
VAL_ 311 CheckSum_ABS3 0 " Valid values " ;
VAL_ 311 ABSFailSts 0 " No failure " 1 " Failure " ;
VAL_ 311 EBDFailSts 0 " No failure " 1 " Failure " ;
VAL_ 311 VehSpdVld 0 " Invalid values " 1 " Valid values " ;
VAL_ 311 VehSpd 0 " Valid values " 5334 " Reserved " ;
VAL_ 311 EBDActv 0 " Not active " 1 " Active " ;
VAL_ 311 ABSActv 0 " Not active " 1 " Active " ;
VAL_ 311 VehOdoInfoSts 0 " Invalid value " 1 " Valid value " ;
VAL_ 311 VehOdoInfo 0 " Valid values " 1000 " Reserved " ;
VAL_ 311 ESP_MILSts 0 " the Warning(Mil) light is off  " 1 " the Warning(Mil) light is on " ;
VAL_ 311 RollingCounter_ABS3 0 " Valid value " 15 " Invalid value " ;
VAL_ 311 CheckSum_ESP_FD2_7 0 " Valid values " ;
VAL_ 311 TtcFactor_RL 0 " Valid value " 60001 " Reserved " ;
VAL_ 311 TtcFactor_RR 0 " Valid value " 60001 " Reserved " ;
VAL_ 311 RollingCounter_ESP_FD2_7 0 " Valid value " 15 " Invalid value " ;
VAL_ 315 CheckSum_ABS1 0 " Valid values " ;
VAL_ 315 FLWheelDriveDirection 0 " InValid values " 1 " Forward " 2 " Backward " 3 " Stop " ;
VAL_ 315 FLWheelSpdVld 0 " InValid values " 1 " Valid values " ;
VAL_ 315 FLWheelSpd 0 " Valid values " 5334 " Reserved " ;
VAL_ 315 FRWheelDriveDirection 0 " InValid values " 1 " Forward " 2 " Backward " 3 " Stop " ;
VAL_ 315 FRWheelSpdVld 0 " InValid values " 1 " Valid values " ;
VAL_ 315 FRWheelSpd 0 " Valid values " 5334 " Reserved " ;
VAL_ 315 WssFLEdgesSum 0 " Valid value " ;
VAL_ 315 WssFREdgesSum 0 " Valid value " ;
VAL_ 315 WssFLEdgesSumVld 0 " Invalid " 1 " Valid " ;
VAL_ 315 WssFREdgesSumVld 0 " Invalid " 1 " Valid " ;
VAL_ 315 RollingCounter_ABS1 0 " Valid value " 15 " Invalid value " ;
VAL_ 315 CheckSum_ABS2 0 " Valid values " ;
VAL_ 315 RLWheelDriveDirection 0 " Invalid value " 1 " Forward " 2 " Backward " 3 " Stop " ;
VAL_ 315 RLWheelSpdVld 0 " Invalid value " 1 " Valid value " ;
VAL_ 315 RLWheelSpd 0 " Valid values " 5334 " Reserved " ;
VAL_ 315 RRWheelDriveDirection 0 " InValid values " 1 " Forward " 2 " Backward " 3 " Stop " ;
VAL_ 315 RRWheelSpdVld 0 " Invalid value " 1 " Valid value " ;
VAL_ 315 RRWheelSpd 0 " Valid values " 5334 " Reserved " ;
VAL_ 315 WssRREdgesSum 0 " Valid values " ;
VAL_ 315 WssRLEdgesSum 0 " Valid values " ;
VAL_ 315 WssRLEdgesSumVld 0 " Invalid " 1 " Valid " ;
VAL_ 315 WssRREdgesSumVld 0 " Invalid " 1 " Valid " ;
VAL_ 315 RollingCounter_ABS2 0 " Valid value " 15 " Invalid value " ;
VAL_ 315 CheckSum_EPB1 0 " Valid values " ;
VAL_ 315 EPB_SwtPosnVld 0 " Invaild " 1 " Vaild " ;
VAL_ 315 PressBrakePedalPointOut 0 " No reminder " 1 " Pedal needs to be applied " ;
VAL_ 315 EPBErrSts 0 " Undefined " 1 " No Error " 2 " Error " 3 " Diagnosis " ;
VAL_ 315 EPBSts 0 " Released " 1 " Closed " 2 " In progress " 3 " unknown " ;
VAL_ 315 EPB_SwtPosn 0 " Neutral " 1 " Release " 2 " Apply " 3 " Reserved " ;
VAL_ 315 EPBTextDisp 0 " No display " 1 " Gradient too high " 2 " Park brake force not enough " 3 " Park brake system overheated " 4 " Remind driver to apply safety belt " 5 " Park brake maintenance mode " 6 " Roller bench mode " 7 " Reserved " ;
VAL_ 315 ESP_DSTTrqReq 0 " Valid values " 801 " Reserved " 1023 " Invalid value " ;
VAL_ 315 ESP_DSTTrqReqDir 0 " Positive(left) " 1 " Negative(right) " ;
VAL_ 315 ESP_DSTSts 0 " No active " 1 " Active " 2 " Not available " 3 " Reserved " ;
VAL_ 315 EPBRedLmpSts 0 " Lamp off " 1 " Lamp on " 2 " Lamp flash " 3 " Reserved " ;
VAL_ 315 RollingCounter_EPB1 0 " Valid value " 15 " Invalid value " ;
VAL_ 315 CheckSum_ESP13 0 " Valid values " ;
VAL_ 315 DrvTrqIncReq_RA 0 " Valid values " ;
VAL_ 315 DrvTrqRedReq_RA 0 " Valid values " ;
VAL_ 315 GearShftInhibitReq_RA 0 " No request Inactive " 1 " Request Active " ;
VAL_ 315 DrvTrqRedReqActv_RA 0 " Not active " 1 " Active " ;
VAL_ 315 DrvTrqIncReqActv_RA 0 " Not active " 1 " Active " ;
VAL_ 315 RollingCounter_ESP13 0 " Valid value " 15 " Invalid value " ;
VAL_ 315 CheckSum_ESP_FD3_7 0 " Valid values " ;
VAL_ 315 L3VLCADactive 0 " Not active " 1 " Active " ;
VAL_ 315 L3mainVMCavailiable 0 " Not initialized " 1 " Not Available " 2 " Available " 3 " Availablewithfault " ;
VAL_ 315 VLC_ESP_FuelCutOffPrevention 0 " Valid value " ;
VAL_ 315 VLC_ESP_State 0 " Valid value " ;
VAL_ 315 LSMPosLongACapbl 0 " AxCapbl_Full " 1 " reversed " 2 " AxCapbl_VehBlocked " 3 " reversed " ;
VAL_ 315 LSMSubMTReqAvailable 0 " False " 1 " True " ;
VAL_ 315 LSMSubMTLevelEcho 0 " MTLevel_None " 1 " MTLevel_12 " 2 " MTLevel_23 " 3 " MTLevel_Reserved " ;
VAL_ 315 LSMSubMTLongEcho 0 " MTLong_None " 1 " MTLong_Comfort " 2 " MTLong_Emergency " 3 " MTLong_Reserved " ;
VAL_ 315 LSMSubMTReqEcho 0 " MTLong_None " 1 " MTLong_Drive " 2 " MTLong_LSM " 3 " reversed " ;
VAL_ 315 Lsm12ComfortAvl 0 " NotAvailable " 1 " FailureDetectedReducedAvl " 2 " FailureDetectedFullyAvl " 3 " Available " ;
VAL_ 315 Lsm12EmergencyAvl 0 " NotAvailable " 1 " FailureDetectedReducedAvl " 2 " FailureDetectedFullyAvl " 3 " Available " ;
VAL_ 315 Lsm23Avl 0 " NotAvailable " 1 " FailureDetectedReducedAvl " 2 " FailureDetectedFullyAvl " 3 " Available " ;
VAL_ 315 LSMGearRequest 0 " GearReq_NoReq " 1 " GearReq_Forward " 2 " GearReq_Backward " 3 " reversed " ;
VAL_ 315 ParkPawlRequest 0 " No request " 1 " P Gear request " ;
VAL_ 315 RollingCounter_ESP_FD3_7 0 " Valid value " 15 " Invalid value " ;
VAL_ 317 Checksum_APS4 0 " Valid Value " ;
VAL_ 317 MEB_BrkgReqValue 0 " Valid value " 201 " Reserved " ;
VAL_ 317 MEB_BrkgReq 0 " No Request " 1 " Request " ;
VAL_ 317 MEBErrSts 0 " No Error " 1 " Error " ;
VAL_ 317 MEB_AVHReq 0 " No Request " 1 " Request " ;
VAL_ 317 RollingCounter_APS4 0 " Valid value " 15 " Invalid value " ;
VAL_ 323 HWP_MotTypeReqMode_L2 0 " None " 1 " Drv L12 " 2 " Drv L3 " 3 " Reserved " ;
VAL_ 323 HWP_MotTypeReqLong_L2 0 " Longitudinal Off " 1 " Longitudinal Comfort " 2 " Longitudinal Emergency " 3 " Reserved3 " 4 " Reserved4 " ;
VAL_ 323 HWP_ShutdownReq_L2 0 " no demand " 1 " demand " ;
VAL_ 323 HWP_TgtAccel_L2 0 " Valid value " 21 " Reserved " ;
VAL_ 323 HWP_UpperLimit_L2 0 " Valid value " 128 " Reserved " ;
VAL_ 323 HWP_LowerLimit_L2 0 " Valid value " 128 " Reserved " ;
VAL_ 323 HWP_SecureReq_L2 0 " no request " 1 " request " ;
VAL_ 323 HWP_AEBAvail 0 " Not Available " 1 " Available " ;
VAL_ 323 HWP_ACCAvail 0 " Not Available " 1 " Available " ;
VAL_ 323 HWP_TgtAccelCmftUpprLimVal_L2 0 " Valid value " 251 " Reserved " ;
VAL_ 323 HWP_TgtAccelCmftLwrLimVal_L2 0 " Valid value " 251 " Reserved " ;
VAL_ 323 HWP_UseTgtAccelCmftUpprLimVal_L2 0 " No demand " 1 " Demand " ;
VAL_ 323 Checksum_ACC1 0 " Valid value " ;
VAL_ 323 Longctrl_VehHldReq 0 " No Request " 1 " Request " ;
VAL_ 323 Longctrl_DrvOFF_Req 0 " No Request " 1 " Request " ;
VAL_ 323 Longctrl_ModSts 0 " OFF mode " 1 " Passive mode(Reject) " 2 " Passive mode(Stand-by) " 3 " Active-Control mode " 4 " Brake-only mode " 5 " Override " 6 " Standstill " 7 " Failure mode Longctrl " 8 " Reserved " 9 " Shut off " 10 " Reserved " ;
VAL_ 323 Longctrl_Decel_Req 0 " No Request " 1 " Request " ;
VAL_ 323 Longctrl_DecelToStopReq 0 " No Request " 1 " Request " ;
VAL_ 323 Longctrl_Decel_ReqValue 0 " Valid value " ;
VAL_ 323 Longctrl_ParkShiftReq 0 " No request " 1 " Request park Shift " 2 " Invalid " 3 " Reserved " ;
VAL_ 323 RollingCounter_ACC1 0 " Valid value " 15 " Invalid value " ;
VAL_ 323 Checksum_ACC10 0 " Valid value " ;
VAL_ 323 Longctrl_HCUTrqReq 0 " Valid value " ;
VAL_ 323 Longctrl_HCUTrqReqActive 0 " Not active " 1 " Active " ;
VAL_ 323 RollingCounter_ACC10 0 " Valid value " 15 " Invalid value " ;
VAL_ 327 CheckSum_EPS1 0 " Valid values " ;
VAL_ 327 EPS_DSTCtrlSts 0 " Permanently fail " 1 " Temporary inhibit " 2 " Available for control " 3 " Active " 4 " Reserved " ;
VAL_ 327 EPS_FailSts 0 " No fault " 1 " Permanent Error Detected " 2 " Intermittent Error Detected " 3 " Reserved " ;
VAL_ 327 EPS_TrqSnsrSts 0 " Normal " 1 " Abnormal " ;
VAL_ 327 EPS_InterferDetd 0 " No Interference " 1 " Interference " ;
VAL_ 327 EPS_InterferDetdVld 0 " Invalid " 1 " Valid " ;
VAL_ 327 EPS_AvailSts 0 " Temporary inhibit " 1 " Available for control " 2 " Active " 3 " Permanently failed " ;
VAL_ 327 EPS_SteerMod 0 " Comfort Mode " 1 " sport mode  " 2 " Handiness Mode " 3 " Reserved " ;
VAL_ 327 RollingCounter_EPS1 0 " Valid value " 15 " Invalid value " ;
VAL_ 327 CheckSum_EPS2 0 " Valid values " ;
VAL_ 327 EPS_LKATorqOvrlDlvd 0 " Valid value " 3001 " Reserved " ;
VAL_ 327 EPS_LKATorqOvrlDlvdVld 0 " Invalid " 1 " Valid " ;
VAL_ 327 EPS_LKATrqOvlDlvdSts 0 " Not active " 1 " Active " 2 " Temporary inhibit " 3 " Permanently failed " ;
VAL_ 327 EPS_DSTTrqOvl 0 " Valid value " 3001 " Reserved " ;
VAL_ 327 EPS_DrvInpTrqVal_HighReslolution 0 " Valid Values " ;
VAL_ 327 RollingCounter_EPS2 0 " Valid value " 15 " Invalid value " ;
VAL_ 327 CheckSum_EPS3 0 " Valid values " ;
VAL_ 327 ElecPwrSteerCpby 0 " Normal " 1 " 50% assist " 2 " 0% assist " 3 " Reserved " ;
VAL_ 327 EPS_SteerWheelAng 0 " Valid value " 7801 " Reserved " 32767 " Invalid " ;
VAL_ 327 EPS_SteerWheelAngSign 0 " Left (Positive) " 1 " Right (Negative) " ;
VAL_ 327 EPS_SteerWheelSpd 0 " Valid value " 10161 " Reserved " 32767 " Invalid " ;
VAL_ 327 EPS_SteerWheelSpdSign 0 " Left (Positive) " 1 " Right (Negative) " ;
VAL_ 327 EPS_HWPHndShkResp 0 " No Response " 1 " Response " ;
VAL_ 327 RollingCounter_EPS3 0 " Valid value " 15 " Invalid value " ;
VAL_ 344 Checksum_IDC_L3_1 0 " Valid values " ;
VAL_ 344 HWP_ReqCtrlEPS 0 " 0x1 " ;
VAL_ 344 HWP_ReqCtrlEPSVld 0 " Invalid " 1 " Valid " ;
VAL_ 344 HWP_AngCmdReqVal 0 " Valid value " 15601 " reserved " ;
VAL_ 344 HWP_AngCmdReqValVld 0 " Invalid " 1 " Valid " ;
VAL_ 344 HWP_HapcWarnReq 0 " No Request " 1 " LeveL 1 " 2 " Reserved " ;
VAL_ 344 HWP_TrqOvlCmdProtnValue 0 " Valid value " ;
VAL_ 344 HWP_TrqOvlCmdReqValue 0 " Valid value " ;
VAL_ 344 HWP_FuncTrqCmdReqFlag 0 " No Request " 1 " HWP Request " 2 " Reserved " ;
VAL_ 344 RollingCounter_IDC_L3_1 0 " Valid value " 15 " Invalid value " ;
VAL_ 344 HWP_WorkReq 0 " OFF " 1 " Standby " 2 " Ready " 3 " Active " 4 " Reserved " ;
VAL_ 344 HWP_WorkReqVld 0 " Invalid " 1 " Valid " ;
VAL_ 344 HWP_TgtGearReq 0 " No request " 1 " P  " 2 " R " 3 " N " 4 " D " 5 " Reserved " ;
VAL_ 344 HWP_TgtGearReqVld 0 " Invalid " 1 " Valid " ;
VAL_ 344 HWP_lgt_ModSts 0 " OFF mode " 1 " Passive mode(Reject) " 2 " Passive mode(Stand-by) " 3 " Active-Control mode " 4 " Brake-only mode " 5 " Override " 6 " Standstill " 7 " Failure mode Longctrl " 8 " Reserved " 9 " Shut off " 10 " Reserved " ;
VAL_ 344 HWP_lgt_VehHldReq 0 " No Request " 1 " Request " ;
VAL_ 344 HWP_lgt_DrvOFF_Req 0 " No Request " 1 " Request " ;
VAL_ 344 HWP_lgt_DecelToStopReq 0 " No Request " 1 " Request " ;
VAL_ 344 HWP_EPBCtrlReq 0 " Release " 1 " Brake " ;
VAL_ 344 HWP_EPBCtrlReqVld 0 " Invalid " 1 " Valid " ;
VAL_ 344 HWP_Lgt_HCUTrqReq 0 " Valid value " ;
VAL_ 344 HWP_Lgt_HCUTrqReqVld 0 " Invalid " 1 " Valid " ;
VAL_ 344 HWP_Lgt_HCUTrqReqActv 0 " Not active " 1 " Active " ;
VAL_ 344 HWP_Lgt_HCUTrqReqActvVld 0 " Invalid " 1 " Valid " ;
VAL_ 344 HWP_HCUOvrdReq 0 " Not active " 1 " Active " ;
VAL_ 344 HWP_MotTypeReqMode 0 " None " 1 " Drv L12 " 2 " Drv L3 " 3 " Reserved " ;
VAL_ 344 HWP_MotTypeReqLong 0 " Longitudinal Off " 1 " Longitudinal Comfort " 2 " Longitudinal Emergency " 3 " Reserved " ;
VAL_ 344 HWP_ShutdownReq 0 " no demand " 1 " demand " ;
VAL_ 344 HWP_TgtAccel 0 " Valid value " 21 " Reserved " ;
VAL_ 344 HWP_UpperLimit 0 " Valid value " 128 " Reserved " ;
VAL_ 344 HWP_LowerLimit 0 " Valid value " 128 " Reserved " ;
VAL_ 344 HWP_SecureReq 0 " no request " 1 " request " ;
VAL_ 344 HWP_SuprAvail 0 " Not Available " 1 " Available " ;
VAL_ 344 HWP_TgtAccelCmftUpprLimVal 0 " Valid value " 251 " Reserved " ;
VAL_ 344 HWP_TgtAccelCmftLwrLimVal 0 " Valid value " 251 " Reserved " ;
VAL_ 344 HWP_UseTgtAccelCmftUpprLimVal 0 " No demand " 1 " Demand " ;
VAL_ 347 Checksum_APS1 0 " Valid Value " ;
VAL_ 347 APS_ReqEPSTgtAngValid 0 " Invalid " 1 " Valid " ;
VAL_ 347 APS_ReqCtrlEPS 0 " No request " 1 " Request " ;
VAL_ 347 APS_ReqEPSTgtAng 0 " Valid value " ;
VAL_ 347 RollingCounter_APS1 0 " Valid value " 15 " Invalid value " ;
VAL_ 347 Checksum_APS4 0 " Valid Value " ;
VAL_ 347 APS_BrkFctnMod 0 " ParkAssist_NoSignal " 1 " Reserved " 2 " Reserved " 3 " ParkAssist_AutomaticPark " 4 " Reserved " ;
VAL_ 347 APS_ESP_TgtGearReq 0 " No request " 1 " P  " 2 " R " 3 " N " 4 " D " 5 " Reserved " ;
VAL_ 347 APS_BrkCategory 0 " ParkAssist_Idle " 1 " ParkAssist_Comfort " 2 " ParkAssist_Emergency " 3 " Reserved " ;
VAL_ 347 APS_BrkModSts 0 " ParkAssist_Int " 1 " ParkAssist_Standby " 2 " ParkAssist_Active " 3 " ParkAssist_ManeuverFinished " 4 " ParkAssist_Suspend (Reserved) " 5 " ParkAssist_Abort " 6 " Reserved  " ;
VAL_ 347 MEBErrSts 0 " No Error " 1 " Error " ;
VAL_ 347 MEB_BrkgReq 0 " No Request " 1 " Request " ;
VAL_ 347 APS_WorkSts 0 " Disable " 1 " Standby " 2 " Searching " 3 " Guidance " 4 " Failed " 5 " Wait for Engine restart " 6 " Reserved " ;
VAL_ 347 APS_ESP_SpdLimn 0 " Valid Value " ;
VAL_ 347 APS_ESP_BrkDistance 0 " Valid value " ;
VAL_ 347 MEB_AVHReq 0 " No Request " 1 " Request " ;
VAL_ 347 MEB_BrkgReqValue 0 " Valid value " 201 " Reserved " ;
VAL_ 347 RollingCounter_APS4 0 " Valid value " 15 " Invalid value " ;
VAL_ 347 HAP_ESP_LSMSubMTReq 0 " MTReq_None " 1 " MTReq_Drive " 2 " MTReq_LSM " 3 " Reserved " ;
VAL_ 347 HAP_ESP_LSMSubMTLevel 0 " MTLevel_None " 1 " MTLevel_12 " 2 " MTLevel_23 " 3 " MTLevel_Reserved " ;
VAL_ 347 HAP_ESP_LSMSubMTLong 0 " MTLong_None " 1 " MTLong_Comfort " 2 " MTLong_Emergency " 3 " MTLong_Reserved " ;
VAL_ 347 HAP_ESP_LSMPrefill 0 " No Request " 1 " Requested " ;
VAL_ 347 HAP_ESP_LSMDistToStop 0 " Valid value " ;
VAL_ 347 HAP_ESP_LSMVehDirRq 0 " DirReq_None " 1 " DirReq_Forward " 2 " DirReq_Backward " 3 " Reserved " ;
VAL_ 347 HAP_ESP_LSMvMaxRq 0 " Valid value " 201 " Reserved " ;
VAL_ 347 HAP_ESP_LSMVehSecReq 0 " No Request " 1 " Requested " ;
VAL_ 347 HAP_ESP_LSMNudgeReq 0 " No Request " 1 " Requested " ;
VAL_ 347 HAP_ESP_LSMComfBrakeReq 0 " ComfBrakeReq_NoReq  " 1 " ComfBrakeReq_Type1  " 2 " ComfBrakeReq_Type2 " 3 " Reserved " ;
VAL_ 347 HAP_ESP_DriverPresenceExternal 0 " False " 1 " True " ;
VAL_ 347 HAP_ESP_SafeDrvrHandoverReq 0 " No Request " 1 " Requested " ;
VAL_ 367 Checksum_RSDS_R_2 0 " Valid value " ;
VAL_ 367 RSDS_Brk_ErrSts 0 " No error  " 1 " Error  " ;
VAL_ 367 RSDS_BrkgReq 0 " No Request " 1 " Request " ;
VAL_ 367 RSDS_BrkgReqVal 0 " Valid value " ;
VAL_ 367 RollingCounter_RSDS_R_2 0 " Valid value " 15 " Invalid value " ;
VAL_ 395 Checksum_AEB1 0 " Valid value " ;
VAL_ 395 AEB_ABA_Level 0 " Level 0 " 1 " Level 1 " 2 " Level 2 " 3 " Level 3 " ;
VAL_ 395 AEB_ABA_Req 0 " No Request " 1 " Request " ;
VAL_ 395 EBA_TgtDecel_Req 0 " No Request " 1 " Request " ;
VAL_ 395 AEB_ObjSty 0 " No Object " 1 " Vehicle " 2 " Pedestrian " 3 " Cyclist " 4 " unknown " 5 " Resvered " ;
VAL_ 395 AEB_VehHldReq 0 " No Request " 1 " Request " ;
VAL_ 395 AEB_TgtDecel_Req 0 " No Request " 1 " Request " ;
VAL_ 395 AEB_TgtDecel_ReqValue 0 " Valid value " 65535 " Invalid " ;
VAL_ 395 AEB_AWB_Req 0 " No Request " 1 " Request " ;
VAL_ 395 AEB_AWB_Level 0 " No level " 1 " Level 1 " 2 " Level 2 " 3 " Level 3 " 4 " Level 4 " 5 " Resvered " ;
VAL_ 395 AEB_ABP_Req 0 " No Request " 1 " Request " ;
VAL_ 395 RollingCounter_AEB1 0 " Valid value " 15 " Invalid value " ;
VAL_ 411 HoodSts_F_Pbox 0 " Closed " 1 " Open " ;
VAL_ 516 CheckSum_HCU_PT7 0 " Valid values " ;
VAL_ 516 HCU_HybSysErr_1 0 " Not indicate " 1 " Indicate " ;
VAL_ 516 HCU_HybSysErr_2 0 " Not indicate " 1 " Indicate " ;
VAL_ 516 HCU_HybSysErr_3 0 " Not indicate " 1 " Indicate " ;
VAL_ 516 HCU_HybSysErr_4 0 " Not indicate " 1 " Indicate " ;
VAL_ 516 HCU_HybSysErr_5 0 " Not indicate " 1 " Indicate " ;
VAL_ 516 HCU_HybSysErr_6 0 " Not indicate " 1 " Indicate " ;
VAL_ 516 HCU_HybSysErr_7 0 " Not indicate " 1 " Indicate " ;
VAL_ 516 HCU_12VSysErrLmpSts 0 " OFF " 1 " ON " ;
VAL_ 516 HCU_HybSysErrLmpSts 0 " OFF " 1 " Yellow Light ON " 2 " Red Light ON " 3 " Reserved " ;
VAL_ 516 HCU_PowerRedWarnLmpCmd 0 " Lamp off " 1 " Lamp on " ;
VAL_ 516 HCU_12VSysErr_1 0 " Not indicate " 1 " Indicate " ;
VAL_ 516 HCU_12VSysErr_2 0 " Not indicate " 1 " Indicate " ;
VAL_ 516 HCU_12VSysErr_3 0 " Not indicate " 1 " Indicate " ;
VAL_ 516 HCU_RdyLmpSts 0 " OFF " 1 " ON " ;
VAL_ 516 HCU_EnrgFlowInd_P2 0 " mode 1 Vehicle standstill(P2&P2+P4) " 1 " mode 2 engine drive , P2M generate electricity and P4M generates electricity(P2+P4) " 2 " mode 3 engine drive, P2M generate electricity and P4M drive the vehicle(P2+P4) " 3 " mode 4 engine drive and P2M generate electricity(P2&P2+P4) " 4 " mode 5 engine drive, P2M don't generate electricity and P4M generate electricity(P2+P4) " 5 " mode 6 P2M with engine and P4M drive the vehicle at the same time(P2+P4) " 6 " mode 7 P2M supply boost for engine (P2&P2+P4) " 7 " mode 8 engine and P4M drive the vehicle at the same time(P2+P4) " 8 " mode 9 engine drives the vehicle only (P2&P2+P4) " 9 " mode 10 engine drives P2M to generate electricity,P4M drives the vehicle(P2M、battery supply power)(P2+P4) " 10 " mode 11 P2M generate electricity when engine idling(P2&P2+P4) " 11 " mode 12 engine idling and the P2M doesn’t generate electricity(P2&P2+P4) " 12 " mode 13 brake recuperation of the front wheels(P2&P2+P4) " 13 " mode 14 brake recuperation of the rear wheels(P2+P4) " 14 " mode 15 P2M and P4M drive the vehicle at the same time(P2+P4) " 15 " mode 16 P4M drive the vehicle,only(P2&P2+P4) / P2M drive the vehicle,only(P2) " 16 " mode 17 plug-in-charging(P2&P2+P4) " 17 " mode 18 Charging heating(P2&P2+P4) " 18 " Reserved " ;
VAL_ 516 HCU_StrtMod 0 " No action " 1 " By electric " 2 " By oil " 3 " Reserved " ;
VAL_ 516 HCU_ModSwtFail 14 "Reserve" 0 " Default  " 1 " EV not available due to low battery charge  " 2 " EV not available due to temporary hybrid system limitations " 3 " SAVE not available due to temporary hybrid system limitations " 4 " AWD not available due to temporary hybrid system limitations " 5 " SPORT not available due to temporary hybrid system limitations " 6 " Manual gear change ,drive mode goes SPORT  " 7 " Manual gear change,only SPORT available " 8 " EV mode available " 9 " Snow not available due to temporary hybrid system limitations " 10 " Muddy not available due to temporary hybrid system limitations " 11 " Sand not available due to temporary hybrid system limitations " 12 " SPORT Plus Mode not available due to temporary hybrid system limitations " 13 " ECO Mode not available " ;
VAL_ 516 RollingCounter_HCU_PT7 0 " Valid value " 15 " Invalid value " ;
VAL_ 516 HCU_ChrgSysLmpSts 0 " OFF " 1 " Green Light ON " 2 " Red Light ON " 3 " Yellow Light with slanting line " 4 " Red Light with slanting line " 5 " Reserved " ;
VAL_ 516 HCU_ChrgSysErr_1 0 " Not indicate " 1 " Indicate " ;
VAL_ 516 HCU_ChrgSysErr_2 0 " Not indicate " 1 " Indicate " ;
VAL_ 516 HCU_ChrgSysErr_3 0 " Not indicate " 1 " Indicate " ;
VAL_ 516 HCU_ChrgSysErr_4 0 " Not indicate " 1 " Indicate " ;
VAL_ 516 HCU_ChrgSysErr_5 0 " Not indicate " 1 " Indicate " ;
VAL_ 516 HCU_ChrgSysErr_6 0 " Not indicate " 1 " Indicate " ;
VAL_ 516 HCU_ChrgSysErr_7 0 " Not indicate " 1 " Indicate " ;
VAL_ 516 HCU_ChrgSysErr_8 0 " Not indicate " 1 " Indicate " ;
VAL_ 516 HCU_DrvModDisp 0 " Auto/Normal Mode started " 1 " EV Mode started " 2 " Save Mode started " 3 " SPORT Mode started " 4 " AWD Normal Mode started " 5 " Snow Mode started " 6 " Muddy Mode started " 7 " Sand Mode started " 8 " ECO " 9 " SPORT Plus Mode started " 10 " Reserved " ;
VAL_ 516 Checksum_HCU_HP5 0 " Valid values " ;
VAL_ 516 HCU_MILSts 0 " the Warning(Mil) light is off  " 1 " the Warning(Mil) light is on " ;
VAL_ 516 RadiatorFanReq 0 " Vaild value " ;
VAL_ 516 RollingCounter_HCU_HP5 0 " Valid value " 15 " Invalid value " ;
VAL_ 542 CheckSum_DCT5 0 " Valid values " ;
VAL_ 542 CurrentGearValid 0 " Invalid value " 1 " Valid value " ;
VAL_ 542 SHIFT_IN_PROGRESS 0 " Gear Shift NOT in progress. " 1 " Gear Shif is in progress " ;
VAL_ 542 TargetGearValid 0 " Invalid value " 1 " Valid value " ;
VAL_ 542 TCU_APS_Available 0 " Available " 1 " Not available " ;
VAL_ 542 TCU_ESP_DriverIntervention 0 " False " 1 " True " ;
VAL_ 542 TARGET_GEAR 0 " Target gear -N- or -P - " 1 " Target gear -1- " 2 " Target gear -2- " 3 " Target gear -3- " 4 " Target gear -4- " 5 " Target gear -5- " 6 " Target gear -6- " 7 " Target gear -7- " 8 " Target gear -R- " 9 " Target gear -8- " 10 " Target gear -9- " 11 " Reserved " ;
VAL_ 542 ShiftInPrgValid 0 " Invalid value " 1 " Valid value " ;
VAL_ 542 DCT_OSS 0 " Valid values " 10001 " Reserved " 16383 " Invalid value " ;
VAL_ 542 CURRENT_GEAR 0 " Current gear -N- or -P- " 1 " Current gear -1- " 2 " Current gear -2- " 3 " Current gear -3- " 4 " Current gear -4- " 5 " Current gear -5- " 6 " Current gear -6- " 7 " Current gear -7- " 8 " Current gear -R- " 9 " Current gear -8- " 10 " Current gear -9- " 11 " Reserved " ;
VAL_ 542 TGS_LEVER 0 " Select lever in position -P- " 1 " Reserved " 2 " Reserved " 3 " Reserved " 4 " Reserved " 5 " Select lever in position -D- " 6 " Select lever in position -N- " 7 " Select lever in position -R- " 8 " Select lever in position -M- " 9 " Reserved " 14 " Intermediate position " 15 " InValid values  " ;
VAL_ 542 TRANS_Warning_LAMP 0 " The Warning(Mil) light is off  " 1 " The Warning(Mil) light is on " ;
VAL_ 542 ShiftLeverPosn_SBWM 0 " P " 1 " D " 2 " N " 3 " R " 4 " M " 5 " Blank " 6 " Reserved " 7 " InValid values value " ;
VAL_ 542 RollingCounter_DCT5 0 " Valid value " 15 " Invalid value " ;
VAL_ 542 CheckSumDCT17 0 " Valid values " ;
VAL_ 542 DCT_SlipStrtSts 0 " Slip Start not available " 1 " Slip Start available " 2 " Slip Start aborted " 3 " Reserved " ;
VAL_ 542 TCU_DrivingMode 0 " Auto/Normal Mode started " 1 " EV Mode started " 2 " Save Mode started " 3 " SPORT Mode started " 4 " AWD Normal Mode started " 5 " Snow Mode started " 6 " Muddy Mode started " 7 " Sand Mode started " 8 " ECO " 9 " Reserved " ;
VAL_ 542 TCU_EngSpdReq 0 " Valid values " 3151 " Reserved  " 4094 " No control " 4095 " Invalid value " ;
VAL_ 542 TCU_TgtGearHybMode 0 " Target gear -N- or -P- " 1 " Target gear -1- " 2 " Target gear -2- " 3 " Target gear -3- " 4 " Target gear -4- " 5 " Target gear -5- " 6 " Target gear -6- " 7 " Target gear -7- " 8 " Target gear -8- " 9 " Target gear -R- " 10 " Target gear -9- " 11 " Reserved " ;
VAL_ 542 DCT_TgtGearEleMode 0 " Target gear -N- or -P- " 1 " Target gear -1- " 2 " Target gear -2- " 3 " Target gear -3- " 4 " Target gear -4- " 5 " Target gear -5- " 6 " Target gear -6- " 7 " Target gear -7- " 8 " Target gear -8- " 9 " Target gear -R- " 10 " Target gear -9- " 11 " Reserved " ;
VAL_ 542 RollingCounterDCT17 0 " Valid value " 15 " Invalid value " ;
VAL_ 566 CheckSum_DCT7 0 " Valid values " ;
VAL_ 566 Oil_CoolerReq 0 " no request  " 1 " Rotation speed lever 1 request  " 2 " Rotation speed lever 2 request " 3 " Rotation speed lever 3 request " 4 " Rotation speed lever 4 request " 5 " Rotation speed lever 5 request " 6 " Rotation speed lever 6 request " 7 " Rotation speed lever 7 request " 8 " Rotation speed lever 8 request       " 9 " Reserved  " 15 " Invalid  " ;
VAL_ 566 TRANS_OIL_TEMP 0 " Valid values " 255 " Invalid values " ;
VAL_ 566 DCT_PrsBrk_Warn 0 " No warning " 1 " Press brake and Unlock-button to shift " 2 " Press Unlock-button to shift " 3 " Press brake to shift " ;
VAL_ 566 DCT_ShftNotAlwd_Warn 0 " No warning " 1 " Vehicle speed too high, shift not allowed " 2 " Engage P not allowed due to high vehicle speed " 3 " Transmission is in N, park-lock is not locked " ;
VAL_ 566 DCT_ShftRecom_M 0 " No Recommendation " 1 " Up Shift " 2 " Down Shift " 3 " Reserved " ;
VAL_ 566 DrvWarnMsg 0 " No Text  " 1 " PressBrake   " 2 " TransToo_Hot                    " 3 " Reserved " ;
VAL_ 566 DrvFaiMsg 0 " No Message " 1 " Transmission Malfunction  " 2 " Transmission P engagement fault " 3 " Transmission P disengagement fault " 4 " Authentication failure " 5 " Reserved  " 15 " transmission limit function " ;
VAL_ 566 DrvModDisp 0 " P                                    " 1 " R                                    " 2 " N                                                " 3 " D                                             " 4 " M                                          " 5 " Reserved  " ;
VAL_ 566 DrvModDispSts 0 " Blank/No Display                              " 1 " On                                            " 2 " Flashing                                         " 3 " Reserved(treat as Blank/No Display) " ;
VAL_ 566 DrvAutoGearDisp 0 " Neutral " 1 " 1st Gear " 2 " 2nd Gear " 3 " 3rd Gear " 4 " 4th Gear " 5 " 5th Gear " 6 " 6th Gear " 7 " 7th Gear " 8 " 8th Gear " 9 " 9th Gear " 10 " Reserved " ;
VAL_ 566 DrvGearDispSts 0 " Blank / No display " 1 " On " 2 " Flashing " 3 " Reserved (treat as Blank/No display) " ;
VAL_ 566 CoolFanReq_DCT7 0 " no fan control " 1 " low speed " 2 " mid speed " 3 " max speed " 4 " Reserved " 15 " Invalid value " ;
VAL_ 566 RollingCounter_DCT7 0 " Valid value " 15 " Invalid value " ;
VAL_ 566 CheckSum_DCT18 0 " Valid values " ;
VAL_ 566 DCT_MaxVehSpd 0 " Valid values " 255 " No limitation " ;
VAL_ 566 DCT_MinVehSpd 0 " Valid values " 255 " No limitation " ;
VAL_ 566 DCT_OvrspdFlag 0 " not overspeed " 1 " overspeed " 2 " Invalid value " 3 " Reserved " ;
VAL_ 566 DCT_MaxAllwSpd 0 " Valid values  " 3151 " Reserved " 4095 " Invalid value " ;
VAL_ 566 RollingCounter_DCT18 0 " Valid value " 15 " Invalid value " ;
VAL_ 581 CheckSum_ABM2 0 " Valid values " ;
VAL_ 581 VehLgtAccel 0 " Valid Value " 44067 " Reserved " ;
VAL_ 581 VehLatAccel 0 " Valid Value " 44067 " Reserved " ;
VAL_ 581 VehYawRate 0 " Valid Value " 17442 " Reserved " ;
VAL_ 581 VehLgtAccelVld 0 " Invalid " 1 " Valid " ;
VAL_ 581 VehLatAccelVld 0 " Invalid " 1 " Valid " ;
VAL_ 581 VehDynYawRateVld 0 " Invalid " 1 " Valid " ;
VAL_ 581 RollingCounter_ABM2 0 " Valid value " 15 " Invalid value " ;
VAL_ 639 CheckSum_IP2 0 " Valid values " ;
VAL_ 639 IP_VehTotDistance 0 " 0-9999999-km " 10000000 " Reserved " 16777215 " Invalid " ;
VAL_ 639 IP_FuelLvlInfo 0 " Valid Value " 201 " Reserved " 255 " Invalid Value " ;
VAL_ 639 IP_VehTotDistanceValid 0 " Invalid " 1 " Valid " ;
VAL_ 639 IP_VehSpdUnit 0 " kph " 1 " mph " ;
VAL_ 639 IP_VINcompr 0 " equality " 1 " inequality " ;
VAL_ 639 RollingCounter_IP2 0 " Valid value " 15 " Invalid value " ;
VAL_ 659 IP_FuelMainTankR 0 " Invalid value " 1 " Reserved " 10 " Valid value " 1001 " Reserved " 1023 " Invalid value " ;
VAL_ 659 IP_FuelAuxTankR 0 " Invalid value " 1 " Reserved " 10 " Valid value " 1001 " Reserved " 1023 " Invalid value " ;
VAL_ 661 CheckSum_PEPS2 0 " Valid value " ;
VAL_ 661 SysPowerMod 0 " OFF " 1 " ACC (reserved) " 2 " ON " 3 " Crank " ;
VAL_ 661 SysPowerModVld 0 " Invalid " 1 " Valid " ;
VAL_ 661 RollingCounter_PEPS2 0 " Valid value " 15 " Invalid value " ;
VAL_ 669 ACDrvTemp_ETC 0 " Initial value " 1 " Level 1(Low)_17(Hi) " 18 " Reserved " ;
VAL_ 669 ACEngRunngReq 0 " No Request " 1 " Request " ;
VAL_ 669 ACCmprOffCode 0 " No off code " 1 " Over pressure " 2 " Blower voltage fault " 3 " Under pressure " 4 " Reserved " 5 " Engine off time too short " 6 " Compressor request off " 7 " AC off mode " 8 " Low outside ambient temperature " 9 " Reserved " 10 " Low Battery Voltage " 11 " High engine coolant temperature " 12 " Reserved " 13 " High Battery Voltage " 14 " Low evaporator temperature " 15 " Numbers of overpressure error are max " 16 " Compressor PWM error " 17 " Pressure sensor error " 18 " Burn out " 19 " Low ambttemp " 20 " Reserved " 25 " Evaporator valve error " 26 " No cooling request " 27 " Fan only mode " 28 " CMP error " 29 " AC_LIN communication error " 30 " Vehicle hev supply fail " 31 " Vehicle crash " ;
VAL_ 680 TranPMode_Sts 0 " Normal Mode " 1 " Transport Mode " ;
VAL_ 699 U_BATT 0 " valid value " 15361 " Reserved " 16383 " Invalid " ;
VAL_ 699 I_RANGE 0 " current Range [-1, 1A] " 1 " current Range [-200, 200A] " 2 " current Range [-1500, 1500A] " 3 " Invalid " ;
VAL_ 699 I_BATT 31744 " valid value[-1, 1A] " 7168 " valid value [-200, 200A] " 8768 " valid value  [-1500, 1500A] " 65535 " Invalid " ;
VAL_ 699 T_BATT 0 " valid value " 146 " Reserved " 255 " Invalid " ;
VAL_ 699 IBATT_QUIESCENT 0 " valid value " 253 " Overflow " 254 " Out of bounds " 255 " Invalid " ;
VAL_ 699 Status_Current 0 " No error " 1 " Error Open circuit " 2 " HW defect -out of range or ADC defect " 3 " LIN saturation -no HW defect " ;
VAL_ 699 Status_Voltage 0 " No error " 1 " Error Open circuit " 2 " HW defect -ADC defect " 3 " LIN saturation -no HW defect " ;
VAL_ 699 Status_Temp 0 " No error " 1 " not used " 2 " HW defect -ADC defect " 3 " LIN saturation -no HW defect " ;
VAL_ 699 ERROR_Calib 0 " No error " 1 " Error " ;
VAL_ 699 ERROR_IDENT 0 " No error " 1 " Error " ;
VAL_ 699 Resp_Error 0 " No error " 1 " Error " ;
VAL_ 699 FLAG_INCONSISTENCY 0 " no battery inconsistency " 1 " battery inconsistency " ;
VAL_ 699 SOC 0 " valid value " 101 " Reserved " 255 " Invalid " ;
VAL_ 699 SOH_SUL 0 " valid value " 101 " Reserved " 255 " Invalid " ;
VAL_ 699 SOFV_StopEnable 0 " valid value " 255 " Invalid " ;
VAL_ 699 SOFV_Restart 0 " valid value " 255 " Invalid " ;
VAL_ 699 SOH_LAM 0 " valid value " 255 " Invalid " ;
VAL_ 699 SOH_COR 0 " valid value " 255 " Invalid " ;
VAL_ 699 SOC_STATE 0 " deviation > 15% " 1 " deviation <15% " 2 " deviation < 10% " 3 " Invalid " ;
VAL_ 699 SOH_SUL_STATE 0 " not learned " 1 " learned " 2 " Reserved " 3 " Invalid " ;
VAL_ 699 SOFV_StopEnable_STATE 0 " Inaccurate " 1 " accurate(deviation<400mv) " 2 " Reserved " 3 " Invalid " ;
VAL_ 699 SOFV_Restart_STATE 0 " Inaccurate " 1 " accurate(deviation<400mv) " 2 " Reserved " 3 " Invalid " ;
VAL_ 699 SOH_LAM_STATE 0 " not learned at all " 1 " learned at least once " 2 " Reserved " 3 " Invalid " ;
VAL_ 699 SOH_COR_STATE 0 " not learned at all " 1 " Inaccurate " 2 " accurate(deviation<400mv) " 3 " Invalid " ;
VAL_ 699 Q_Charge 0 " Valid values " 65535 " Invalid values " ;
VAL_ 699 Q_Discharge 0 " Valid values " 65535 " Invalid values " ;
VAL_ 707 HUT_ESPFuncOffSwtSts 0 " Not Pressed " 1 " Pressed " ;
VAL_ 707 DSTSwtReq 0 " OFF " 1 " ON " ;
VAL_ 707 EPSSteerModSwtReq 0 " Comfort Mode " 1 " Sport?mode? " 2 " Handiness Mode " 3 " NO Hut Control " ;
VAL_ 707 HUT_BattSOCLimSaveMod 0 " 30% " 1 " 35% " 2 " 40% " 3 " 45% " 4 " 50% " 5 " 55% " 6 " 60% " 7 " 65% " 8 " 70% " 9 " 75% " 10 " 80% " 11 " 85% " 12 " 90% " 13 " 95% " 14 " 100% " 15 " Reserved " 31 " Invalid " ;
VAL_ 708 BMS_BattSOC 0 " Valid values " 1001 " Reserved " 1023 " Invalid values " ;
VAL_ 729 CurrDamprMode 0 " No Command " 1 " Comfort " 2 " Normal " 3 " Sport " 4 " Invalid " 5 " Not used " ;
VAL_ 729 WarnLmpReq 0 " Lamp off " 1 " Lamp on " ;
VAL_ 760 ACCoolFanReq 0 " Valid value " 101 " Reserved " 127 " Invalid value " ;
VAL_ 764 Checksum_HCU_PT4 0 " Valid values " ;
VAL_ 764 P2M_MotorStatorActTemp 0 " Valid values " 254 " Init " 255 " Error " ;
VAL_ 764 P4M_MotorOverSpdSts 0 " Not over " 1 " Over  " ;
VAL_ 764 HCU_EnerSavePowerMod 0 " No action " 1 " Close blower " 2 " Close seat heat " 3 " Close both blower and seat heat " ;
VAL_ 764 HCU_SOCLow_Indcn 0 " Not active " 1 " Active " ;
VAL_ 764 HCU_RemoveChrgLine_Indcn 0 " Not active " 1 " Active " ;
VAL_ 764 HCU_Shift_P_Indcn 0 " Not active " 1 " Active " ;
VAL_ 764 HCU_ConnectChrgLine_Indcn 0 " Not active " 1 " Active " ;
VAL_ 764 ImdtlyChrgSts 0 " Not active " 1 " Active " ;
VAL_ 764 HCU_EgyRecFB 0 " Standard " 1 " Enhanced " 2 " Low " 3 " Not Available " ;
VAL_ 764 HCU_ACStsReq 0 " Disable " 1 " Derating " 2 " Normal " 3 " Invalid value " ;
VAL_ 764 HCU_RefuReq 0 " No request " 1 " Refueling request " 2 " When vehicle is ready inhibit refuel " 3 " When engine is run inhibit refuel " 4 " When charger is connected inhibit refuel " 5 " Reserved " ;
VAL_ 764 HCU_OilTankCoverSts 0 " Closed " 1 " Open " ;
VAL_ 764 HCU_InhbChrgInfo 0 " No warning " 1 " When vehicle is refueling inhibit charge " ;
VAL_ 764 HCU_RefuBtnSts 0 " No pressed " 1 " Pressed " ;
VAL_ 764 HCU_EACPwrAld 0 " Valid values（0-8kw） " 401 " Reserved " 511 " unlimited " ;
VAL_ 764 RollingCounter_HCU_PT4 0 " Valid value " 15 " Invalid value " ;
VAL_ 764 HCU_AGSPosnReq 0 " Valid values " 101 " Reserved " ;
VAL_ 769 CheckSum_ECM3 0 " Valid values " ;
VAL_ 769 BaroPressure 0 " Valid values " 255 " Invalid values " ;
VAL_ 769 EngCoolantTemp 0 " Valid values " ;
VAL_ 769 IntakeAirTemp 0 " Valid values " 255 " InValid values " ;
VAL_ 769 GPF_Warning 0 " No Warning " 1 " GPF is regenerating " 2 " GPF need to regenerate " 3 " Reserved " ;
VAL_ 769 EngClntTempWarn 0 " No " 1 " Yes " ;
VAL_ 769 EngClntTempVldty 0 " Invalid values " 1 " Valid values " 2 " Init value " ;
VAL_ 769 DrivingCycle 0 " Not achieved " 1 " Achieved " ;
VAL_ 769 WarmUpCycle 0 " Not achieved " 1 " Achieved " ;
VAL_ 769 GPF_ActvRgn_Ena 0 " Not enable " 1 " enable " ;
VAL_ 769 ECM_ClearPDTC 0 " not Clear the PDTC " 1 " Clear the PDTC " ;
VAL_ 769 GeneralDenominator 0 " Not achieved " 1 " Achieved " ;
VAL_ 769 IgnitionCycle 0 " Not achieved " 1 " Achieved " ;
VAL_ 769 ECM_FreezeIUPR 0 " Not freeze " 1 " Freeze " ;
VAL_ 769 AGS_Failure 0 " No Failure " 1 " Failure " ;
VAL_ 769 RollingCounter_ECM3 0 " Valid value " 15 " Invalid value " ;
VAL_ 769 CheckSum_ECM11 0 " Valid values " ;
VAL_ 769 EngSpd_ForIP 0 " Valid values  " ;
VAL_ 769 CoolFanDutyRatio 0 " Valid values " 101 " Reserved " ;
VAL_ 769 GPF_PasRgn_Ena 0 " Not enable " 1 " enable " 2 " Reserved " 3 " Reserved " ;
VAL_ 769 AbsltthrtlPosn 0 " Valid values " ;
VAL_ 769 MaxAvailEngTrq 0 " Valid values " ;
VAL_ 769 CoolerSts 0 " Rotation speed " 101 " Reserved " 255 " Error " ;
VAL_ 769 EWP_Err 0 " No error " 1 " Error " ;
VAL_ 769 RollingCounter_ECM11 0 " Valid value " 15 " Invalid value " ;
VAL_ 769 CheckSum_ECM_PT6 0 " Valid values " ;
VAL_ 769 PressReliProgs 0 " value " 100 " Finish " 101 " reserved " ;
VAL_ 769 FTIVFault 0 " No warning " 1 " Warning " ;
VAL_ 769 FanErrSts 0 " No error " 1 " Fan error with max speed " 2 " reserved " 3 " reserved " ;
VAL_ 769 FuelTankCapWarning 0 " No warning " 1 " Warning(Fuel tank cap did not close) " 2 " Reserved " 3 " Fault(Fuel tank cap did not open) " ;
VAL_ 769 RollingCounter_ECM_PT6 0 " Valid value " 15 " Invalid value " ;
VAL_ 791 CheckSum_OBC2 0 " Valid value " ;
VAL_ 791 OBC_StsCPLine 0 " Not Connected; " 1 " S2 lock-up state failure " 2 " Reserved " 6 " CP signal failure " 7 " No fault " ;
VAL_ 791 OBC_StstCCLine 0 " Not Connected " 1 " Connected " 2 " Error " 3 " Partial Connected " ;
VAL_ 791 RollingCounter_OBC2 0 " Valid value " 15 " Invalid value " ;
VAL_ 793 DrvDoorSts 0 " Closed " 1 " Open " ;
VAL_ 837 DoorLockSts 0 " NA " 1 " All doors locked " 2 " Driver door unlocked " 3 " All doors unlocked " ;
VAL_ 837 VehicleSoakTime 0 " Valid Value " 1001 " Reserved " 4095 " not available " ;
VAL_ 849 CheckSum_ABM1 0 " Valid values " ;
VAL_ 849 DrvSBR 0 " No reminder " 1 " Reminder " ;
VAL_ 849 CrashOutputSts 0 " No crash " 1 " Reserved " 2 " Front First level " 3 " rear crash(Reserved) " 4 " Reserved " 8 " Right hand side " 9 " Reserved " 16 " Left hand side  " 17 " Rollover(Reserved) " 18 " Static Roll(Reserved)  " 19 " Reserved " ;
VAL_ 849 RollingCounter_ABM1 0 " Valid value " 15 " Invalid value " ;
VAL_ 865 P2M_DFC 0 " Valid value " 254 " Init " 255 " Error " ;
VAL_ 865 P2M_MotorStatorActTemp 0 " Valid value " 254 " Init " 255 " Invalid value " ;
VAL_ 865 P2M_InverterActTemp 0 " Valid value " 254 " Init " 255 " Invalid value " ;
VAL_ 865 P2M_CoolantTemp 0 " Valid value " 254 " Init " 255 " Invalid value " ;
VAL_ 865 P2M_ResOffsetActSts 0 " Not Active " 1 " Active " 2 " passed/calibration value exists " 3 " failed/Invalid " ;
VAL_ 865 P2M_InvActSts 0 " InverterStandby " 1 " TorqueCtrl " 2 " Reserved " 3 " Reserved " 4 " VoltageCtrl " 5 " InverterError " 6 " Reserved " 7 " Reserved " 8 " Inverter Init mode " 9 " Reserved " 10 " Reserved " 11 " Resolver Offset Detection " 12 " Reserved " 13 " discharge mode " 14 " Reserved " 15 " OFF " ;
VAL_ 865 P2M_ResOffset_Calib 0 " Init " 1 " ResOffsetCalib not done " 2 " ResOffsetCalib successfully done " 3 " Invalid " ;
VAL_ 865 P2M_ActvDchrgSts 0 " Active discharge is Ready " 1 " Active discharge is ongoing " 2 " Active discharge finished " 3 " Active discharge timeout " 4 " Reserved " 6 " Init " 7 " Error " ;
VAL_ 865 P2M_ErrCagy 0 " Init " 1 " Waring(only record DTC, no response) " 2 " Derating/Limphome(recovery automatic) " 3 " Disable(recovery automatic) " 4 " Disable(recovery after KL15 on) " 5 " discharge " 6 " Reserved " ;
VAL_ 865 P2M_ActEffi 0 " Valid " 101 " reserved " 127 " Invalid " ;
VAL_ 865 P2M_ASCSts 0 " Inactive " 1 " Active " 2 " Invalid " 3 " Reserved " ;
VAL_ 865 P2M_InvPlsOffSts 0 " Inactive " 1 " Active " 2 " Invalid " 3 " Reserved " ;
VAL_ 865 P2M_ActvdampSts 0 " Inactive " 1 " Active " ;
VAL_ 865 P2M_MILSts 0 " the Warning(Mil) light is off  " 1 " the Warning(Mil) light is on " ;
VAL_ 865 P2M_PosTrqAvailMax 0 " Valid value " 8190 " Init " 8191 " Invalid " ;
VAL_ 865 P2M_NegTrqAvailMin 0 " Valid value " 8190 " Init " 8191 " Invalid " ;
VAL_ 865 P2M_NegTrqAvailMin_2s 0 " Valid value " 8190 " Init " 8191 " Invalid " ;
VAL_ 865 P2M_PosTrqAvailMax_2s 0 " Valid value " 8190 " Init " 8191 " Invalid " ;
VAL_ 865 P4M_PosTrqAvailMax_2s 0 " Valid value " 8190 " Init " 8191 " invalid " ;
VAL_ 865 P4M_NegTrqAvailMin_2s 0 " Valid value " 8190 " Init " 8191 " invalid " ;
VAL_ 865 P4M_NegTrqAvailMin_10s 0 " Valid value " 8190 " Init " 8191 " invalid " ;
VAL_ 865 P4M_NegTrqAvailMin 0 " Valid value " 8190 " Init " 8191 " invalid " ;
VAL_ 865 P4M_MotorActTemp 0 " Valid value " 254 " Init " 255 " Error " ;
VAL_ 865 P4M_InvActTemp 0 " Valid value " 254 " Init " 255 " Invalid " ;
VAL_ 865 P4M_InletCoolantTemp 0 " Valid value " 254 " Init " 255 " Error " ;
VAL_ 865 P4M_ResOffsetActSts 0 " Not Active " 1 " Active " 2 " passed/calibration value exists " 3 " failed/Invalid " ;
VAL_ 865 P4M_SPOTest 0 " Not Active " 1 " Active " 2 " Passed " 3 " failed " ;
VAL_ 865 P4M_MotorOverSpdSts 0 " Not over " 1 " Over  " ;
VAL_ 865 HCU_HVILSts 0 " Init " 1 " Normal " 2 " Error " 3 " Reserved " ;
VAL_ 865 HCU_BMSSleepCmd 0 " no sleep " 1 " sleep " ;
VAL_ 865 HCU_InvStsReq_P2M 0 " Standby " 1 " TorqueCtrl " 2 " SpeedCtrl " 3 " VoltageCtrl " 4 " Reserved " 8 " Inverter init " 9 " Reserved " 10 " InverterPrepareSleep " 11 " Reslover Offset Dtection " 12 " AC isolation Detection " 13 " discharge mode " 14 " Reserved " ;
VAL_ 865 HCU_P2MTrqReq 0 " Valid value " 16382 " Init " 16383 " Invalid " ;
VAL_ 865 HCU_P2MActHvDcCurr_RM 0 " Valid value " 20001 " Reserved " 65534 " Error " 65535 " Invalid " ;
VAL_ 865 HCU_P2MActHvDcVolt_RM 0 " Valid value " 60001 " Reserved " 65534 " Error " 65535 " Invalid " ;
VAL_ 865 HCU_DTCNumber1 0 " Valid values " ;
VAL_ 865 HCU_DTCNumber2 0 " Valid values " ;
VAL_ 865 HCU_MotorAmount_RM 0 " Reserved " 1 " Valid value " 254 " Invalid value " ;
VAL_ 880 TimeMod 0 " 24 " 1 " 12 " ;
VAL_ 880 TimeIndcn 0 " am " 1 " pm " ;
VAL_ 880 Time_Hour 0 " Valid hour " 24 " Reserved " 31 " Invalid " ;
VAL_ 880 Time_Minutes 0 " Valid minute " 60 " Reserved " 63 " Invalid " ;
VAL_ 880 Time_Second 0 " Valid second " 60 " Reserved " 63 " Invalid " ;
VAL_ 880 Time_Year_Left 0 " Valid year " 10 " Reserved " 15 " Invalid " ;
VAL_ 880 Time_Year_Right 0 " Valid year " 10 " Reserved " 15 " Invalid " ;
VAL_ 880 Time_Month 0 " Invalid " 1 " Valid month " 13 " Reserved " ;
VAL_ 880 Time_Day 0 " Invalid " 1 " Valid day " ;
VAL_ 901 CheckSum_AC2 0 " Valid value " ;
VAL_ 901 ACFrntBlwrSpd 0 " Off " 1 " Level 1（Low）-7（Hi） " 8 " Reserved " 14 " Auto blower level " 15 " Initial value " ;
VAL_ 901 ACDrvTemp_ATC 0 " Low " 1 " Valid value " 32 " High " 33 " Initial value " 34 " Reserved " ;
VAL_ 901 ACAmbTempSnsrFlt 0 " Normal " 1 " Short to Battery " 2 " Short to GND " 3 " Open " 4 " Reserved " ;
VAL_ 901 ACFrntPasstTemp_ATC 0 " Low " 1 " Valid value " 32 " High " 33 " Initial value " 34 " Reserved " ;
VAL_ 901 ACActTempThrtlPosn 0 " Valid value " 101 " Invalid Value " ;
VAL_ 901 ACAmbTemp 0 " Valid value " 254 " Initial value " 255 " Invalid Value " ;
VAL_ 901 RollingCounter_AC2 0 " Valid value " 15 " Invalid value " ;
VAL_ 951 ECM_VehDstBackup 0 " 0-9999999-km " 10000000 " Reserved " 16777215 " Invalid " ;
VAL_ 951 EngStrtEndCounter 0 " Valid Values " ;
